VERSION "dbc-export 1 2026.26.6.5"

NS_ :

BS_:

BU_: APB APP APS DAS DPB EPAS3S EPASTS ESP GTW IBST IDB PARK RADC RCM RCM2 RCM3 RCU TPMS USM

BO_ 1009 RCM2_alertMatrix: 8 RCM2
 SG_ RCM2_matrixIndex M : 0|4@1+ (1,0) [0|15] "" Vector__XXX
 SG_ RCM2_a000_crashDetected m0 : 4|1@1+ (1,0) [0|1] "" Vector__XXX
 SG_ RCM2_a001_nearDeploy m0 : 5|1@1+ (1,0) [0|1] "" Vector__XXX
 SG_ RCM2_a002_airbagsUnArmed m0 : 6|1@1+ (1,0) [0|1] "" Vector__XXX
 SG_ RCM2_a003_warningIndicator m0 : 7|1@1+ (1,0) [0|1] "" Vector__XXX
 SG_ RCM2_a004_crashAlgoWakeup m0 : 8|1@1+ (1,0) [0|1] "" Vector__XXX
 SG_ RCM2_a005_abuseImmunityThrshold m0 : 9|1@1+ (1,0) [0|1] "" Vector__XXX
 SG_ RCM2_a006_supplierDiagEnabled m0 : 10|1@1+ (1,0) [0|1] "" Vector__XXX
 SG_ RCM2_a007_pedProCrashDetected m0 : 11|1@1+ (1,0) [0|1] "" Vector__XXX
 SG_ RCM2_a008_factoryMode m0 : 12|1@1+ (1,0) [0|1] "" Vector__XXX
 SG_ RCM2_a009_edrDataAreaLocked m0 : 13|1@1+ (1,0) [0|1] "" Vector__XXX
 SG_ RCM2_a010_pedProEDRDataLocked m0 : 14|1@1+ (1,0) [0|1] "" Vector__XXX
 SG_ RCM2_a011_placeholder0 m0 : 15|1@1+ (1,0) [0|1] "" Vector__XXX
 SG_ RCM2_a012_placeholder1 m0 : 16|1@1+ (1,0) [0|1] "" Vector__XXX
 SG_ RCM2_a013_placeholder2 m0 : 17|1@1+ (1,0) [0|1] "" Vector__XXX
 SG_ RCM2_a014_pedProNearDeploy m0 : 18|1@1+ (1,0) [0|1] "" Vector__XXX
 SG_ RCM2_a015_noDeployCrashCal m0 : 19|1@1+ (1,0) [0|1] "" Vector__XXX
 SG_ RCM2_a016_noDeployPedProCal m0 : 20|1@1+ (1,0) [0|1] "" Vector__XXX
 SG_ RCM2_a017_ecuLogAvailable m0 : 21|1@1+ (1,0) [0|1] "" Vector__XXX
 SG_ RCM2_a047_batteryESRhigh m0 : 22|1@1+ (1,0) [0|1] "" Vector__XXX
 SG_ RCM2_a048_batteryVoltageTooHigh m0 : 23|1@1+ (1,0) [0|1] "" Vector__XXX
 SG_ RCM2_a049_batteryVoltageTooLow m0 : 24|1@1+ (1,0) [0|1] "" Vector__XXX
 SG_ RCM2_a050_driverABStg1Sht2Gnd m0 : 25|1@1+ (1,0) [0|1] "" Vector__XXX
 SG_ RCM2_a051_driverABStg1Sht2Bat m0 : 26|1@1+ (1,0) [0|1] "" Vector__XXX
 SG_ RCM2_a052_driverABStg1Open m0 : 27|1@1+ (1,0) [0|1] "" Vector__XXX
 SG_ RCM2_a053_driverABStg1Short m0 : 28|1@1+ (1,0) [0|1] "" Vector__XXX
 SG_ RCM2_a054_driverABStg1CrssCoup m0 : 29|1@1+ (1,0) [0|1] "" Vector__XXX
 SG_ RCM2_a055_driverABStg1Config m0 : 30|1@1+ (1,0) [0|1] "" Vector__XXX
 SG_ RCM2_a056_driverABStg2Sht2Gnd m0 : 31|1@1+ (1,0) [0|1] "" Vector__XXX
 SG_ RCM2_a057_driverABStg2Sht2Bat m0 : 32|1@1+ (1,0) [0|1] "" Vector__XXX
 SG_ RCM2_a058_driverABStg2Open m0 : 33|1@1+ (1,0) [0|1] "" Vector__XXX
 SG_ RCM2_a059_driverABStg2Short m0 : 34|1@1+ (1,0) [0|1] "" Vector__XXX
 SG_ RCM2_a060_driverABStg2CrssCoup m0 : 35|1@1+ (1,0) [0|1] "" Vector__XXX
 SG_ RCM2_a061_driverABStg2Config m0 : 36|1@1+ (1,0) [0|1] "" Vector__XXX
 SG_ RCM2_a062_passABStg1Sht2Gnd m0 : 37|1@1+ (1,0) [0|1] "" Vector__XXX
 SG_ RCM2_a063_passABStg1Sht2Bat m0 : 38|1@1+ (1,0) [0|1] "" Vector__XXX
 SG_ RCM2_a064_passABStg1Open m0 : 39|1@1+ (1,0) [0|1] "" Vector__XXX
 SG_ RCM2_a065_passABStg1Short m0 : 40|1@1+ (1,0) [0|1] "" Vector__XXX
 SG_ RCM2_a066_passABStg1CrssCoup m0 : 41|1@1+ (1,0) [0|1] "" Vector__XXX
 SG_ RCM2_a067_passABStg1Config m0 : 42|1@1+ (1,0) [0|1] "" Vector__XXX
 SG_ RCM2_a068_passABStg2Sht2Gnd m0 : 43|1@1+ (1,0) [0|1] "" Vector__XXX
 SG_ RCM2_a069_passABStg2Sht2Bat m0 : 44|1@1+ (1,0) [0|1] "" Vector__XXX
 SG_ RCM2_a070_passABStg2Open m0 : 45|1@1+ (1,0) [0|1] "" Vector__XXX
 SG_ RCM2_a071_passABStg2Short m0 : 46|1@1+ (1,0) [0|1] "" Vector__XXX
 SG_ RCM2_a072_passABStg2CrssCoup m0 : 47|1@1+ (1,0) [0|1] "" Vector__XXX
 SG_ RCM2_a073_passABStg2Config m0 : 48|1@1+ (1,0) [0|1] "" Vector__XXX
 SG_ RCM2_a074_passActiveVentSht2Gnd m0 : 49|1@1+ (1,0) [0|1] "" Vector__XXX
 SG_ RCM2_a075_passActiveVentSht2Bat m0 : 50|1@1+ (1,0) [0|1] "" Vector__XXX
 SG_ RCM2_a076_passActiveVentOpen m0 : 51|1@1+ (1,0) [0|1] "" Vector__XXX
 SG_ RCM2_a077_passActiveVentShort m0 : 52|1@1+ (1,0) [0|1] "" Vector__XXX
 SG_ RCM2_a078_passActiveVentCrssCoup m0 : 53|1@1+ (1,0) [0|1] "" Vector__XXX
 SG_ RCM2_a079_passActiveVentConfig m0 : 54|1@1+ (1,0) [0|1] "" Vector__XXX
 SG_ RCM2_a080_pretenShldLeftSht2Gnd m0 : 55|1@1+ (1,0) [0|1] "" Vector__XXX
 SG_ RCM2_a081_pretenShldLeftSht2Bat m0 : 56|1@1+ (1,0) [0|1] "" Vector__XXX
 SG_ RCM2_a082_pretenShldLeftOpen m0 : 57|1@1+ (1,0) [0|1] "" Vector__XXX
 SG_ RCM2_a083_pretenShldLeftShort m0 : 58|1@1+ (1,0) [0|1] "" Vector__XXX
 SG_ RCM2_a084_pretenShldLeftCrossC m0 : 59|1@1+ (1,0) [0|1] "" Vector__XXX
 SG_ RCM2_a085_pretenShldLeftConfig m0 : 60|1@1+ (1,0) [0|1] "" Vector__XXX
 SG_ RCM2_a086_pretenShldRightSht2Gnd m0 : 61|1@1+ (1,0) [0|1] "" Vector__XXX
 SG_ RCM2_a087_pretenShldRightSht2Bat m0 : 62|1@1+ (1,0) [0|1] "" Vector__XXX
 SG_ RCM2_a088_pretenShldRightOpen m0 : 63|1@1+ (1,0) [0|1] "" Vector__XXX
 SG_ RCM2_a089_pretenShldRightShort m1 : 4|1@1+ (1,0) [0|1] "" Vector__XXX
 SG_ RCM2_a090_pretenShldRightCrssCou m1 : 5|1@1+ (1,0) [0|1] "" Vector__XXX
 SG_ RCM2_a091_pretenShldRightConfig m1 : 6|1@1+ (1,0) [0|1] "" Vector__XXX
 SG_ RCM2_a092_pretenLapLeftSht2Gnd m1 : 7|1@1+ (1,0) [0|1] "" Vector__XXX
 SG_ RCM2_a093_pretenLapLeftSht2Bat m1 : 8|1@1+ (1,0) [0|1] "" Vector__XXX
 SG_ RCM2_a094_pretenLapLeftOpen m1 : 9|1@1+ (1,0) [0|1] "" Vector__XXX
 SG_ RCM2_a095_pretenLapLeftShort m1 : 10|1@1+ (1,0) [0|1] "" Vector__XXX
 SG_ RCM2_a096_pretenLapLeftCrssCoup m1 : 11|1@1+ (1,0) [0|1] "" Vector__XXX
 SG_ RCM2_a097_pretenLapLeftConfig m1 : 12|1@1+ (1,0) [0|1] "" Vector__XXX
 SG_ RCM2_a098_pretenLapRightSht2Gnd m1 : 13|1@1+ (1,0) [0|1] "" Vector__XXX
 SG_ RCM2_a099_pretenLapRightSht2Bat m1 : 14|1@1+ (1,0) [0|1] "" Vector__XXX
 SG_ RCM2_a100_pretenLapRightOpen m1 : 15|1@1+ (1,0) [0|1] "" Vector__XXX
 SG_ RCM2_a101_pretenLapRightShort m1 : 16|1@1+ (1,0) [0|1] "" Vector__XXX
 SG_ RCM2_a102_pretenLapRightCrssCoup m1 : 17|1@1+ (1,0) [0|1] "" Vector__XXX
 SG_ RCM2_a103_pretenLapRightConfig m1 : 18|1@1+ (1,0) [0|1] "" Vector__XXX
 SG_ RCM2_a104_loadLimLeftSht2Gnd m1 : 19|1@1+ (1,0) [0|1] "" Vector__XXX
 SG_ RCM2_a105_loadLimLeftSht2Bat m1 : 20|1@1+ (1,0) [0|1] "" Vector__XXX
 SG_ RCM2_a106_loadLimLeftOpen m1 : 21|1@1+ (1,0) [0|1] "" Vector__XXX
 SG_ RCM2_a107_loadLimLeftShort m1 : 22|1@1+ (1,0) [0|1] "" Vector__XXX
 SG_ RCM2_a108_loadLimLeftCrssCoup m1 : 23|1@1+ (1,0) [0|1] "" Vector__XXX
 SG_ RCM2_a109_loadLimLeftConfig m1 : 24|1@1+ (1,0) [0|1] "" Vector__XXX
 SG_ RCM2_a110_loadLimRightSht2Gnd m1 : 25|1@1+ (1,0) [0|1] "" Vector__XXX
 SG_ RCM2_a111_loadLimRightSht2Bat m1 : 26|1@1+ (1,0) [0|1] "" Vector__XXX
 SG_ RCM2_a112_loadLimRightOpen m1 : 27|1@1+ (1,0) [0|1] "" Vector__XXX
 SG_ RCM2_a113_loadLimRightShort m1 : 28|1@1+ (1,0) [0|1] "" Vector__XXX
 SG_ RCM2_a114_loadLimRightCrssCoup m1 : 29|1@1+ (1,0) [0|1] "" Vector__XXX
 SG_ RCM2_a115_loadLimRightConfig m1 : 30|1@1+ (1,0) [0|1] "" Vector__XXX
 SG_ RCM2_a116_kneeABDrvrSht2Gnd m1 : 31|1@1+ (1,0) [0|1] "" Vector__XXX
 SG_ RCM2_a117_kneeABDrvrSht2Bat m1 : 32|1@1+ (1,0) [0|1] "" Vector__XXX
 SG_ RCM2_a118_kneeABDrvrOpen m1 : 33|1@1+ (1,0) [0|1] "" Vector__XXX
 SG_ RCM2_a119_kneeABDrvrShort m1 : 34|1@1+ (1,0) [0|1] "" Vector__XXX
 SG_ RCM2_a120_kneeABDrvrCrssCoup m1 : 35|1@1+ (1,0) [0|1] "" Vector__XXX
 SG_ RCM2_a121_kneeABDrvrConfig m1 : 36|1@1+ (1,0) [0|1] "" Vector__XXX
 SG_ RCM2_a122_kneeABPassSht2Gnd m1 : 37|1@1+ (1,0) [0|1] "" Vector__XXX
 SG_ RCM2_a123_kneeABPassSht2Bat m1 : 38|1@1+ (1,0) [0|1] "" Vector__XXX
 SG_ RCM2_a124_kneeABPassOpen m1 : 39|1@1+ (1,0) [0|1] "" Vector__XXX
 SG_ RCM2_a125_kneeABPassShort m1 : 40|1@1+ (1,0) [0|1] "" Vector__XXX
 SG_ RCM2_a126_kneeABPassCrssCoup m1 : 41|1@1+ (1,0) [0|1] "" Vector__XXX
 SG_ RCM2_a127_kneeABPassConfig m1 : 42|1@1+ (1,0) [0|1] "" Vector__XXX
 SG_ RCM2_a128_sideAB1stRowLSht2Gnd m1 : 43|1@1+ (1,0) [0|1] "" Vector__XXX
 SG_ RCM2_a129_sideAB1stRowLSht2Bat m1 : 44|1@1+ (1,0) [0|1] "" Vector__XXX
 SG_ RCM2_a130_sideAB1stRowLOpen m1 : 45|1@1+ (1,0) [0|1] "" Vector__XXX
 SG_ RCM2_a131_sideAB1stRowLShort m1 : 46|1@1+ (1,0) [0|1] "" Vector__XXX
 SG_ RCM2_a132_sideAB1stRowLCrssCoup m1 : 47|1@1+ (1,0) [0|1] "" Vector__XXX
 SG_ RCM2_a133_sideAB1stRowLConfig m1 : 48|1@1+ (1,0) [0|1] "" Vector__XXX
 SG_ RCM2_a134_sideAB1stRowRSht2Gnd m1 : 49|1@1+ (1,0) [0|1] "" Vector__XXX
 SG_ RCM2_a135_sideAB1stRowRSht2Bat m1 : 50|1@1+ (1,0) [0|1] "" Vector__XXX
 SG_ RCM2_a136_sideAB1stRowROpen m1 : 51|1@1+ (1,0) [0|1] "" Vector__XXX
 SG_ RCM2_a137_sideAB1stRowRShort m1 : 52|1@1+ (1,0) [0|1] "" Vector__XXX
 SG_ RCM2_a138_sideAB1stRowRCrssCoup m1 : 53|1@1+ (1,0) [0|1] "" Vector__XXX
 SG_ RCM2_a139_sideAB1stRowRConfig m1 : 54|1@1+ (1,0) [0|1] "" Vector__XXX
 SG_ RCM2_a140_hvdPyroSht2Gnd m1 : 55|1@1+ (1,0) [0|1] "" Vector__XXX
 SG_ RCM2_a141_hvdPyroSht2Bat m1 : 56|1@1+ (1,0) [0|1] "" Vector__XXX
 SG_ RCM2_a142_hvdPyroOpen m1 : 57|1@1+ (1,0) [0|1] "" Vector__XXX
 SG_ RCM2_a143_hvdPyroShort m1 : 58|1@1+ (1,0) [0|1] "" Vector__XXX
 SG_ RCM2_a144_hvdPyroCrssCoup m1 : 59|1@1+ (1,0) [0|1] "" Vector__XXX
 SG_ RCM2_a145_hvdPyroConfig m1 : 60|1@1+ (1,0) [0|1] "" Vector__XXX
 SG_ RCM2_a146_curABLeftSht2Gnd m1 : 61|1@1+ (1,0) [0|1] "" Vector__XXX
 SG_ RCM2_a147_curABLeftSht2Bat m1 : 62|1@1+ (1,0) [0|1] "" Vector__XXX
 SG_ RCM2_a148_curABLeftOpen m1 : 63|1@1+ (1,0) [0|1] "" Vector__XXX
 SG_ RCM2_a149_curABLeftShort m2 : 4|1@1+ (1,0) [0|1] "" Vector__XXX
 SG_ RCM2_a150_curABLeftCrssCoup m2 : 5|1@1+ (1,0) [0|1] "" Vector__XXX
 SG_ RCM2_a151_curABLeftConfig m2 : 6|1@1+ (1,0) [0|1] "" Vector__XXX
 SG_ RCM2_a152_curABRightSht2Gnd m2 : 7|1@1+ (1,0) [0|1] "" Vector__XXX
 SG_ RCM2_a153_curABRightSht2Bat m2 : 8|1@1+ (1,0) [0|1] "" Vector__XXX
 SG_ RCM2_a154_curABRightOpen m2 : 9|1@1+ (1,0) [0|1] "" Vector__XXX
 SG_ RCM2_a155_curABRightShort m2 : 10|1@1+ (1,0) [0|1] "" Vector__XXX
 SG_ RCM2_a156_curABRightCrssCoup m2 : 11|1@1+ (1,0) [0|1] "" Vector__XXX
 SG_ RCM2_a157_curABRightConfig m2 : 12|1@1+ (1,0) [0|1] "" Vector__XXX
 SG_ RCM2_a158_preten2ndRowLSht2Gnd m2 : 13|1@1+ (1,0) [0|1] "" Vector__XXX
 SG_ RCM2_a159_preten2ndRowLSht2Bat m2 : 14|1@1+ (1,0) [0|1] "" Vector__XXX
 SG_ RCM2_a160_preten2ndRowLOpen m2 : 15|1@1+ (1,0) [0|1] "" Vector__XXX
 SG_ RCM2_a161_preten2ndRowLShort m2 : 16|1@1+ (1,0) [0|1] "" Vector__XXX
 SG_ RCM2_a162_preten2ndRowLCrssCoup m2 : 17|1@1+ (1,0) [0|1] "" Vector__XXX
 SG_ RCM2_a163_preten2ndRowLCgf m2 : 18|1@1+ (1,0) [0|1] "" Vector__XXX
 SG_ RCM2_a164_preten2ndRowRSht2Gnd m2 : 19|1@1+ (1,0) [0|1] "" Vector__XXX
 SG_ RCM2_a165_preten2ndRowRSht2Bat m2 : 20|1@1+ (1,0) [0|1] "" Vector__XXX
 SG_ RCM2_a166_preten2ndRowROpen m2 : 21|1@1+ (1,0) [0|1] "" Vector__XXX
 SG_ RCM2_a167_preten2ndRowRShort m2 : 22|1@1+ (1,0) [0|1] "" Vector__XXX
 SG_ RCM2_a168_preten2ndRowRCrssCoup m2 : 23|1@1+ (1,0) [0|1] "" Vector__XXX
 SG_ RCM2_a169_preten2ndRowRCgf m2 : 24|1@1+ (1,0) [0|1] "" Vector__XXX
 SG_ RCM2_a170_curAB2ndRowLSht2Gnd m2 : 25|1@1+ (1,0) [0|1] "" Vector__XXX
 SG_ RCM2_a171_curAB2ndRowLSht2Bat m2 : 26|1@1+ (1,0) [0|1] "" Vector__XXX
 SG_ RCM2_a172_curAB2ndRowLOpen m2 : 27|1@1+ (1,0) [0|1] "" Vector__XXX
 SG_ RCM2_a173_curAB2ndRowLShort m2 : 28|1@1+ (1,0) [0|1] "" Vector__XXX
 SG_ RCM2_a174_curAB2ndRowLCrssCoup m2 : 29|1@1+ (1,0) [0|1] "" Vector__XXX
 SG_ RCM2_a175_curAB2ndRowLConfig m2 : 30|1@1+ (1,0) [0|1] "" Vector__XXX
 SG_ RCM2_a176_curAB2ndRowRSht2Gnd m2 : 31|1@1+ (1,0) [0|1] "" Vector__XXX
 SG_ RCM2_a177_curAB2ndRowRSht2Bat m2 : 32|1@1+ (1,0) [0|1] "" Vector__XXX
 SG_ RCM2_a178_curAB2ndRowROpen m2 : 33|1@1+ (1,0) [0|1] "" Vector__XXX
 SG_ RCM2_a179_curAB2ndRowRShort m2 : 34|1@1+ (1,0) [0|1] "" Vector__XXX
 SG_ RCM2_a180_curAB2ndRowRCrssCoup m2 : 35|1@1+ (1,0) [0|1] "" Vector__XXX
 SG_ RCM2_a181_curAB2ndRowRConfig m2 : 36|1@1+ (1,0) [0|1] "" Vector__XXX
 SG_ RCM2_a182_hoodActuatorRSht2Gnd m2 : 37|1@1+ (1,0) [0|1] "" Vector__XXX
 SG_ RCM2_a183_hoodActuatorRSht2Bat m2 : 38|1@1+ (1,0) [0|1] "" Vector__XXX
 SG_ RCM2_a184_hoodActuatorROpen m2 : 39|1@1+ (1,0) [0|1] "" Vector__XXX
 SG_ RCM2_a185_hoodActuatorRShort m2 : 40|1@1+ (1,0) [0|1] "" Vector__XXX
 SG_ RCM2_a186_hoodActuatorRCrssCoup m2 : 41|1@1+ (1,0) [0|1] "" Vector__XXX
 SG_ RCM2_a187_hoodActuatorRConfig m2 : 42|1@1+ (1,0) [0|1] "" Vector__XXX
 SG_ RCM2_a188_hoodActuatorLSht2Gnd m2 : 43|1@1+ (1,0) [0|1] "" Vector__XXX
 SG_ RCM2_a189_hoodActuatorLSht2Bat m2 : 44|1@1+ (1,0) [0|1] "" Vector__XXX
 SG_ RCM2_a190_hoodActuatorLOpen m2 : 45|1@1+ (1,0) [0|1] "" Vector__XXX
 SG_ RCM2_a191_hoodActuatorLShort m2 : 46|1@1+ (1,0) [0|1] "" Vector__XXX
 SG_ RCM2_a192_hoodActuatorLCrssCoup m2 : 47|1@1+ (1,0) [0|1] "" Vector__XXX
 SG_ RCM2_a193_hoodActuatorLConfig m2 : 48|1@1+ (1,0) [0|1] "" Vector__XXX
 SG_ RCM2_a194_driverABAVSht2Gnd m2 : 49|1@1+ (1,0) [0|1] "" Vector__XXX
 SG_ RCM2_a195_driverABAVSht2Bat m2 : 50|1@1+ (1,0) [0|1] "" Vector__XXX
 SG_ RCM2_a196_driverABAVOpen m2 : 51|1@1+ (1,0) [0|1] "" Vector__XXX
 SG_ RCM2_a197_driverABAVShort m2 : 52|1@1+ (1,0) [0|1] "" Vector__XXX
 SG_ RCM2_a198_driverABAVCrossCoup m2 : 53|1@1+ (1,0) [0|1] "" Vector__XXX
 SG_ RCM2_a199_driverABAVConfig m2 : 54|1@1+ (1,0) [0|1] "" Vector__XXX
 SG_ RCM2_a200_driverFSABSht2Gnd m2 : 55|1@1+ (1,0) [0|1] "" Vector__XXX
 SG_ RCM2_a201_driverFSABSht2Bat m2 : 56|1@1+ (1,0) [0|1] "" Vector__XXX
 SG_ RCM2_a202_driverFSABOpen m2 : 57|1@1+ (1,0) [0|1] "" Vector__XXX
 SG_ RCM2_a203_driverFSABShort m2 : 58|1@1+ (1,0) [0|1] "" Vector__XXX
 SG_ RCM2_a204_driverFSABCrossCoup m2 : 59|1@1+ (1,0) [0|1] "" Vector__XXX
 SG_ RCM2_a205_driverFSABConfig m2 : 60|1@1+ (1,0) [0|1] "" Vector__XXX
 SG_ RCM2_a206_sideAB2ndRowLSht2Gnd m2 : 61|1@1+ (1,0) [0|1] "" Vector__XXX
 SG_ RCM2_a207_sideAB2ndRowLSht2Bat m2 : 62|1@1+ (1,0) [0|1] "" Vector__XXX
 SG_ RCM2_a208_sideAB2ndRowLOpen m2 : 63|1@1+ (1,0) [0|1] "" Vector__XXX
 SG_ RCM2_a209_sideAB2ndRowLShort m3 : 4|1@1+ (1,0) [0|1] "" Vector__XXX
 SG_ RCM2_a210_sideAB2ndRowLCrssCoup m3 : 5|1@1+ (1,0) [0|1] "" Vector__XXX
 SG_ RCM2_a211_sideAB2ndRowLConfig m3 : 6|1@1+ (1,0) [0|1] "" Vector__XXX
 SG_ RCM2_a212_sideAB2ndRowRSht2Gnd m3 : 7|1@1+ (1,0) [0|1] "" Vector__XXX
 SG_ RCM2_a213_sideAB2ndRowRSht2Bat m3 : 8|1@1+ (1,0) [0|1] "" Vector__XXX
 SG_ RCM2_a214_sideAB2ndRowROpen m3 : 9|1@1+ (1,0) [0|1] "" Vector__XXX
 SG_ RCM2_a215_sideAB2ndRowRShort m3 : 10|1@1+ (1,0) [0|1] "" Vector__XXX
 SG_ RCM2_a216_sideAB2ndRowRCrssCoup m3 : 11|1@1+ (1,0) [0|1] "" Vector__XXX
 SG_ RCM2_a217_sideAB2ndRowRConfig m3 : 12|1@1+ (1,0) [0|1] "" Vector__XXX
 SG_ RCM2_a250_ens1Sht2Bat m3 : 13|1@1+ (1,0) [0|1] "" Vector__XXX
 SG_ RCM2_a251_ens1Sht2Gnd m3 : 14|1@1+ (1,0) [0|1] "" Vector__XXX
 SG_ RCM2_a252_ens1Config m3 : 15|1@1+ (1,0) [0|1] "" Vector__XXX
 SG_ RCM2_a253_ens2Sht2Bat m3 : 16|1@1+ (1,0) [0|1] "" Vector__XXX
 SG_ RCM2_a254_ens2Sht2Gnd m3 : 17|1@1+ (1,0) [0|1] "" Vector__XXX
 SG_ RCM2_a255_ens2Config m3 : 18|1@1+ (1,0) [0|1] "" Vector__XXX
 SG_ RCM2_a256_ens3Sht2Bat m3 : 19|1@1+ (1,0) [0|1] "" Vector__XXX
 SG_ RCM2_a257_ens3Sht2Gnd m3 : 20|1@1+ (1,0) [0|1] "" Vector__XXX
 SG_ RCM2_a258_ens3Config m3 : 21|1@1+ (1,0) [0|1] "" Vector__XXX
 SG_ RCM2_a259_ens4Sht2Bat m3 : 22|1@1+ (1,0) [0|1] "" Vector__XXX
 SG_ RCM2_a260_ens4Sht2Gnd m3 : 23|1@1+ (1,0) [0|1] "" Vector__XXX
 SG_ RCM2_a261_ens4Config m3 : 24|1@1+ (1,0) [0|1] "" Vector__XXX
 SG_ RCM2_a264_imuYawR8OffCompPosLife m3 : 25|1@1+ (1,0) [0|1] "" Vector__XXX
 SG_ RCM2_a265_imuYawR8OffCompNegLife m3 : 26|1@1+ (1,0) [0|1] "" Vector__XXX
 SG_ RCM2_a266_imuYawR8OffCompPosFLDC m3 : 27|1@1+ (1,0) [0|1] "" Vector__XXX
 SG_ RCM2_a267_imuYawR8OffCompNegFLDC m3 : 28|1@1+ (1,0) [0|1] "" Vector__XXX
 SG_ RCM2_a268_imuYawR8OffCompPosSLDC m3 : 29|1@1+ (1,0) [0|1] "" Vector__XXX
 SG_ RCM2_a269_imuYawR8OffCompNegSLDC m3 : 30|1@1+ (1,0) [0|1] "" Vector__XXX
 SG_ RCM2_a270_imuPtchR8OffCompPosLif m3 : 31|1@1+ (1,0) [0|1] "" Vector__XXX
 SG_ RCM2_a271_imuPtchR8OffCompNegLif m3 : 32|1@1+ (1,0) [0|1] "" Vector__XXX
 SG_ RCM2_a272_imuPtchR8OffCompPosFLD m3 : 33|1@1+ (1,0) [0|1] "" Vector__XXX
 SG_ RCM2_a273_imuPtchR8OffCompNegFLD m3 : 34|1@1+ (1,0) [0|1] "" Vector__XXX
 SG_ RCM2_a274_imuPtchR8OffCompPosSLD m3 : 35|1@1+ (1,0) [0|1] "" Vector__XXX
 SG_ RCM2_a275_imuPtchR8OffCompNegSLD m3 : 36|1@1+ (1,0) [0|1] "" Vector__XXX
 SG_ RCM2_a276_imuRollR8OffCompPosLif m3 : 37|1@1+ (1,0) [0|1] "" Vector__XXX
 SG_ RCM2_a277_imuRollR8OffCompNegLif m3 : 38|1@1+ (1,0) [0|1] "" Vector__XXX
 SG_ RCM2_a278_imuRollR8OffCompPosFLD m3 : 39|1@1+ (1,0) [0|1] "" Vector__XXX
 SG_ RCM2_a279_imuRollR8OffCompNegFLD m3 : 40|1@1+ (1,0) [0|1] "" Vector__XXX
 SG_ RCM2_a280_imuRollR8OffCompPosSLD m3 : 41|1@1+ (1,0) [0|1] "" Vector__XXX
 SG_ RCM2_a281_imuRollR8OffCompNegSLD m3 : 42|1@1+ (1,0) [0|1] "" Vector__XXX
 SG_ RCM2_a282_imuLongAOffCompPosLife m3 : 43|1@1+ (1,0) [0|1] "" Vector__XXX
 SG_ RCM2_a283_imuLongAOffCompNegLife m3 : 44|1@1+ (1,0) [0|1] "" Vector__XXX
 SG_ RCM2_a284_imuLongAOffCompPosFLDC m3 : 45|1@1+ (1,0) [0|1] "" Vector__XXX
 SG_ RCM2_a285_imuLongAOffCompNegFLDC m3 : 46|1@1+ (1,0) [0|1] "" Vector__XXX
 SG_ RCM2_a286_imuLongAOffCompPosSLDC m3 : 47|1@1+ (1,0) [0|1] "" Vector__XXX
 SG_ RCM2_a287_imuLongAOffCompNegSLDC m3 : 48|1@1+ (1,0) [0|1] "" Vector__XXX
 SG_ RCM2_a288_imuLatAcOffCompPosLife m3 : 49|1@1+ (1,0) [0|1] "" Vector__XXX
 SG_ RCM2_a289_imuLatAcOffCompNegLife m3 : 50|1@1+ (1,0) [0|1] "" Vector__XXX
 SG_ RCM2_a290_imuLatAcOffCompPosFLDC m3 : 51|1@1+ (1,0) [0|1] "" Vector__XXX
 SG_ RCM2_a291_imuLatAcOffCompNegFLDC m3 : 52|1@1+ (1,0) [0|1] "" Vector__XXX
 SG_ RCM2_a292_imuLatAcOffCompPosSLDC m3 : 53|1@1+ (1,0) [0|1] "" Vector__XXX
 SG_ RCM2_a293_imuLatAcOffCompNegSLDC m3 : 54|1@1+ (1,0) [0|1] "" Vector__XXX
 SG_ RCM2_a294_imuVertAOffCompPosLife m3 : 55|1@1+ (1,0) [0|1] "" Vector__XXX
 SG_ RCM2_a295_imuVertAOffCompNegLife m3 : 56|1@1+ (1,0) [0|1] "" Vector__XXX
 SG_ RCM2_a296_imuVertAOffCompPosFLDC m3 : 57|1@1+ (1,0) [0|1] "" Vector__XXX
 SG_ RCM2_a297_imuVertAOffCompNegFLDC m3 : 58|1@1+ (1,0) [0|1] "" Vector__XXX
 SG_ RCM2_a298_imuVertAOffCompPosSLDC m3 : 59|1@1+ (1,0) [0|1] "" Vector__XXX
 SG_ RCM2_a299_imuVertAOffCompNegSLDC m3 : 60|1@1+ (1,0) [0|1] "" Vector__XXX
 SG_ RCM2_a300_imuAccXHgMonChlPerm m3 : 61|1@1+ (1,0) [0|1] "" Vector__XXX
 SG_ RCM2_a301_imuAccXHgMonChlTemp m3 : 62|1@1+ (1,0) [0|1] "" Vector__XXX
 SG_ RCM2_a302_imuAccYHgMonChlPerm m3 : 63|1@1+ (1,0) [0|1] "" Vector__XXX
 SG_ RCM2_a303_imuAccYHgMonChlTemp m4 : 4|1@1+ (1,0) [0|1] "" Vector__XXX
 SG_ RCM2_a304_imuYawR8SnsrPermBG m4 : 5|1@1+ (1,0) [0|1] "" Vector__XXX
 SG_ RCM2_a305_imuYawR8SnsrPermInit m4 : 6|1@1+ (1,0) [0|1] "" Vector__XXX
 SG_ RCM2_a306_imuYawR8SnsrPermLF m4 : 7|1@1+ (1,0) [0|1] "" Vector__XXX
 SG_ RCM2_a307_imuYawR8ChnlMonTmpLF m4 : 8|1@1+ (1,0) [0|1] "" Vector__XXX
 SG_ RCM2_a308_imuPitchR8SnsrPermBG m4 : 9|1@1+ (1,0) [0|1] "" Vector__XXX
 SG_ RCM2_a309_imuPitchR8SnsrPermInit m4 : 10|1@1+ (1,0) [0|1] "" Vector__XXX
 SG_ RCM2_a310_imuPitchR8SnsrPermLF m4 : 11|1@1+ (1,0) [0|1] "" Vector__XXX
 SG_ RCM2_a311_imuPitchR8ChnlMonTmpLF m4 : 12|1@1+ (1,0) [0|1] "" Vector__XXX
 SG_ RCM2_a312_imuRollR8SnsrPermBG m4 : 13|1@1+ (1,0) [0|1] "" Vector__XXX
 SG_ RCM2_a313_imuRollR8SnsrPermInit m4 : 14|1@1+ (1,0) [0|1] "" Vector__XXX
 SG_ RCM2_a314_imuRollR8SnsrPermLF m4 : 15|1@1+ (1,0) [0|1] "" Vector__XXX
 SG_ RCM2_a315_imuRollR8ChnlMonTmpLF m4 : 16|1@1+ (1,0) [0|1] "" Vector__XXX
 SG_ RCM2_a316_imuAccXLgMonChlPerm m4 : 17|1@1+ (1,0) [0|1] "" Vector__XXX
 SG_ RCM2_a317_imuAccXLgMonChlTemp m4 : 18|1@1+ (1,0) [0|1] "" Vector__XXX
 SG_ RCM2_a318_imuAccYLgMonChlPerm m4 : 19|1@1+ (1,0) [0|1] "" Vector__XXX
 SG_ RCM2_a319_imuAccYLgMonChlTemp m4 : 20|1@1+ (1,0) [0|1] "" Vector__XXX
 SG_ RCM2_a320_imuAccZLgMonChlPerm m4 : 21|1@1+ (1,0) [0|1] "" Vector__XXX
 SG_ RCM2_a321_imuAccZLgMonChlTemp m4 : 22|1@1+ (1,0) [0|1] "" Vector__XXX
 SG_ RCM2_a322_imuCalibrationFailed m4 : 23|1@1+ (1,0) [0|1] "" Vector__XXX
 SG_ RCM2_a323_imuCalibrationNotDone m4 : 24|1@1+ (1,0) [0|1] "" Vector__XXX
 SG_ RCM2_a350_upFrntSnsrLSht2Gnd m4 : 25|1@1+ (1,0) [0|1] "" Vector__XXX
 SG_ RCM2_a351_upFrntSnsrLSht2Bat m4 : 26|1@1+ (1,0) [0|1] "" Vector__XXX
 SG_ RCM2_a352_upFrntSnsrLOpen m4 : 27|1@1+ (1,0) [0|1] "" Vector__XXX
 SG_ RCM2_a353_upFrntSnsrLCrssCoup m4 : 28|1@1+ (1,0) [0|1] "" Vector__XXX
 SG_ RCM2_a354_upFrntSnsrLCommErr m4 : 29|1@1+ (1,0) [0|1] "" Vector__XXX
 SG_ RCM2_a355_upFrntSnsrLInitTyp m4 : 30|1@1+ (1,0) [0|1] "" Vector__XXX
 SG_ RCM2_a356_upFrntSnsrLConfig m4 : 31|1@1+ (1,0) [0|1] "" Vector__XXX
 SG_ RCM2_a357_upFrntSnsrLDefect m4 : 32|1@1+ (1,0) [0|1] "" Vector__XXX
 SG_ RCM2_a358_upFrntSnsrLSigMon m4 : 33|1@1+ (1,0) [0|1] "" Vector__XXX
 SG_ RCM2_a360_upFrntSnsrRSht2Gnd m4 : 34|1@1+ (1,0) [0|1] "" Vector__XXX
 SG_ RCM2_a361_upFrntSnsrRSht2Bat m4 : 35|1@1+ (1,0) [0|1] "" Vector__XXX
 SG_ RCM2_a362_upFrntSnsrROpen m4 : 36|1@1+ (1,0) [0|1] "" Vector__XXX
 SG_ RCM2_a363_upFrntSnsrRCrssCoup m4 : 37|1@1+ (1,0) [0|1] "" Vector__XXX
 SG_ RCM2_a364_upFrntSnsrRCommErr m4 : 38|1@1+ (1,0) [0|1] "" Vector__XXX
 SG_ RCM2_a365_upFrntSnsrRInitTyp m4 : 39|1@1+ (1,0) [0|1] "" Vector__XXX
 SG_ RCM2_a366_upFrntSnsrRConfig m4 : 40|1@1+ (1,0) [0|1] "" Vector__XXX
 SG_ RCM2_a367_upFrntSnsrRDefect m4 : 41|1@1+ (1,0) [0|1] "" Vector__XXX
 SG_ RCM2_a368_upFrntSnsrRSigMon m4 : 42|1@1+ (1,0) [0|1] "" Vector__XXX
 SG_ RCM2_a370_upFrntSnsrMidLSht2Gnd m4 : 43|1@1+ (1,0) [0|1] "" Vector__XXX
 SG_ RCM2_a371_upFrntSnsrMidLSht2Bat m4 : 44|1@1+ (1,0) [0|1] "" Vector__XXX
 SG_ RCM2_a372_upFrntSnsrMidLOpen m4 : 45|1@1+ (1,0) [0|1] "" Vector__XXX
 SG_ RCM2_a373_upFrntSnsrMidLCrssCoup m4 : 46|1@1+ (1,0) [0|1] "" Vector__XXX
 SG_ RCM2_a374_upFrntSnsrMidLCommErr m4 : 47|1@1+ (1,0) [0|1] "" Vector__XXX
 SG_ RCM2_a375_upFrntSnsrMidLInitTyp m4 : 48|1@1+ (1,0) [0|1] "" Vector__XXX
 SG_ RCM2_a376_upFrntSnsrMidLConfig m4 : 49|1@1+ (1,0) [0|1] "" Vector__XXX
 SG_ RCM2_a377_upFrntSnsrMidLDefect m4 : 50|1@1+ (1,0) [0|1] "" Vector__XXX
 SG_ RCM2_a378_upFrntSnsrMidLSigMon m4 : 51|1@1+ (1,0) [0|1] "" Vector__XXX
 SG_ RCM2_a380_upFrntSnsrMidRSht2Gnd m4 : 52|1@1+ (1,0) [0|1] "" Vector__XXX
 SG_ RCM2_a381_upFrntSnsrMidRSht2Bat m4 : 53|1@1+ (1,0) [0|1] "" Vector__XXX
 SG_ RCM2_a382_upFrntSnsrMidROpen m4 : 54|1@1+ (1,0) [0|1] "" Vector__XXX
 SG_ RCM2_a383_upFrntSnsrMidRCrssCoup m4 : 55|1@1+ (1,0) [0|1] "" Vector__XXX
 SG_ RCM2_a384_upFrntSnsrMidRCommErr m4 : 56|1@1+ (1,0) [0|1] "" Vector__XXX
 SG_ RCM2_a385_upFrntSnsrMidRInitTyp m4 : 57|1@1+ (1,0) [0|1] "" Vector__XXX
 SG_ RCM2_a386_upFrntSnsrMidRConfig m4 : 58|1@1+ (1,0) [0|1] "" Vector__XXX
 SG_ RCM2_a387_upFrntSnsrMidRDefect m4 : 59|1@1+ (1,0) [0|1] "" Vector__XXX
 SG_ RCM2_a388_upFrntSnsrMidRSigMon m4 : 60|1@1+ (1,0) [0|1] "" Vector__XXX
 SG_ RCM2_a390_sideAccelBPilLSht2Gnd m4 : 61|1@1+ (1,0) [0|1] "" Vector__XXX
 SG_ RCM2_a391_sideAccelBPilLSht2Bat m4 : 62|1@1+ (1,0) [0|1] "" Vector__XXX
 SG_ RCM2_a392_sideAccelBPilLOpen m4 : 63|1@1+ (1,0) [0|1] "" Vector__XXX
 SG_ RCM2_a393_sideAccelBPilLCLosCoup m5 : 4|1@1+ (1,0) [0|1] "" Vector__XXX
 SG_ RCM2_a394_sideAccelBPilLCommErr m5 : 5|1@1+ (1,0) [0|1] "" Vector__XXX
 SG_ RCM2_a395_sideAccelBPilLInitTyp m5 : 6|1@1+ (1,0) [0|1] "" Vector__XXX
 SG_ RCM2_a396_sideAccelBPilLConfig m5 : 7|1@1+ (1,0) [0|1] "" Vector__XXX
 SG_ RCM2_a397_sideAccelBPilLDefect m5 : 8|1@1+ (1,0) [0|1] "" Vector__XXX
 SG_ RCM2_a398_sideAccelBPilLSigMon m5 : 9|1@1+ (1,0) [0|1] "" Vector__XXX
 SG_ RCM2_a400_sideAccelBPilRSht2Gnd m5 : 10|1@1+ (1,0) [0|1] "" Vector__XXX
 SG_ RCM2_a401_sideAccelBPilRSht2Bat m5 : 11|1@1+ (1,0) [0|1] "" Vector__XXX
 SG_ RCM2_a402_sideAccelBPilROpen m5 : 12|1@1+ (1,0) [0|1] "" Vector__XXX
 SG_ RCM2_a403_sideAccelBPilRCrssCoup m5 : 13|1@1+ (1,0) [0|1] "" Vector__XXX
 SG_ RCM2_a404_sideAccelBPilRCommErr m5 : 14|1@1+ (1,0) [0|1] "" Vector__XXX
 SG_ RCM2_a405_sideAccelBPilRInitTyp m5 : 15|1@1+ (1,0) [0|1] "" Vector__XXX
 SG_ RCM2_a406_sideAccelBPilRConfig m5 : 16|1@1+ (1,0) [0|1] "" Vector__XXX
 SG_ RCM2_a407_sideAccelBPilRDefect m5 : 17|1@1+ (1,0) [0|1] "" Vector__XXX
 SG_ RCM2_a408_sideAccelBPilRSigMon m5 : 18|1@1+ (1,0) [0|1] "" Vector__XXX
 SG_ RCM2_a410_sideAccelCPilLSht2Gnd m5 : 19|1@1+ (1,0) [0|1] "" Vector__XXX
 SG_ RCM2_a411_sideAccelCPilLSht2Bat m5 : 20|1@1+ (1,0) [0|1] "" Vector__XXX
 SG_ RCM2_a412_sideAccelCPilLOpen m5 : 21|1@1+ (1,0) [0|1] "" Vector__XXX
 SG_ RCM2_a413_sideAccelCPilLCrssCoup m5 : 22|1@1+ (1,0) [0|1] "" Vector__XXX
 SG_ RCM2_a414_sideAccelCPilLCommErr m5 : 23|1@1+ (1,0) [0|1] "" Vector__XXX
 SG_ RCM2_a415_sideAccelCPilLInitTyp m5 : 24|1@1+ (1,0) [0|1] "" Vector__XXX
 SG_ RCM2_a416_sideAccelCPilLConfig m5 : 25|1@1+ (1,0) [0|1] "" Vector__XXX
 SG_ RCM2_a417_sideAccelCPilLDefect m5 : 26|1@1+ (1,0) [0|1] "" Vector__XXX
 SG_ RCM2_a418_sideAccelCPilLSigMon m5 : 27|1@1+ (1,0) [0|1] "" Vector__XXX
 SG_ RCM2_a420_sideAccelCPilRSht2Gnd m5 : 28|1@1+ (1,0) [0|1] "" Vector__XXX
 SG_ RCM2_a421_sideAccelCPilRSht2Bat m5 : 29|1@1+ (1,0) [0|1] "" Vector__XXX
 SG_ RCM2_a422_sideAccelCPilROpen m5 : 30|1@1+ (1,0) [0|1] "" Vector__XXX
 SG_ RCM2_a423_sideAccelCPilRCrssCoup m5 : 31|1@1+ (1,0) [0|1] "" Vector__XXX
 SG_ RCM2_a424_sideAccelCPilRCommErr m5 : 32|1@1+ (1,0) [0|1] "" Vector__XXX
 SG_ RCM2_a425_sideAccelCPilRInitTyp m5 : 33|1@1+ (1,0) [0|1] "" Vector__XXX
 SG_ RCM2_a426_sideAccelCPilRConfig m5 : 34|1@1+ (1,0) [0|1] "" Vector__XXX
 SG_ RCM2_a427_sideAccelCPilRDefect m5 : 35|1@1+ (1,0) [0|1] "" Vector__XXX
 SG_ RCM2_a428_sideAccelCPilRSigMon m5 : 36|1@1+ (1,0) [0|1] "" Vector__XXX
 SG_ RCM2_a430_presFrntLDoorSht2Gnd m5 : 37|1@1+ (1,0) [0|1] "" Vector__XXX
 SG_ RCM2_a431_presFrntLDoorSht2Bat m5 : 38|1@1+ (1,0) [0|1] "" Vector__XXX
 SG_ RCM2_a432_presFrntLDoorOpen m5 : 39|1@1+ (1,0) [0|1] "" Vector__XXX
 SG_ RCM2_a433_presFrntLDoorCrssCoup m5 : 40|1@1+ (1,0) [0|1] "" Vector__XXX
 SG_ RCM2_a434_presFrntLDoorCommErr m5 : 41|1@1+ (1,0) [0|1] "" Vector__XXX
 SG_ RCM2_a435_presFrntLDoorInitTyp m5 : 42|1@1+ (1,0) [0|1] "" Vector__XXX
 SG_ RCM2_a436_presFrntLDoorConfig m5 : 43|1@1+ (1,0) [0|1] "" Vector__XXX
 SG_ RCM2_a437_presFrntLDoorDefect m5 : 44|1@1+ (1,0) [0|1] "" Vector__XXX
 SG_ RCM2_a438_presFrntLDoorSigMon m5 : 45|1@1+ (1,0) [0|1] "" Vector__XXX
 SG_ RCM2_a439_presDoorAbsolute1 m5 : 46|1@1+ (1,0) [0|1] "" Vector__XXX
 SG_ RCM2_a440_presFrntRDoorSht2Gnd m5 : 47|1@1+ (1,0) [0|1] "" Vector__XXX
 SG_ RCM2_a441_presFrntRDoorSht2Bat m5 : 48|1@1+ (1,0) [0|1] "" Vector__XXX
 SG_ RCM2_a442_presFrntRDoorOpen m5 : 49|1@1+ (1,0) [0|1] "" Vector__XXX
 SG_ RCM2_a443_presFrntRDoorCrssCoup m5 : 50|1@1+ (1,0) [0|1] "" Vector__XXX
 SG_ RCM2_a444_presFrntRDoorCommErr m5 : 51|1@1+ (1,0) [0|1] "" Vector__XXX
 SG_ RCM2_a445_presFrntRDoorInitTyp m5 : 52|1@1+ (1,0) [0|1] "" Vector__XXX
 SG_ RCM2_a446_presFrntRDoorConfig m5 : 53|1@1+ (1,0) [0|1] "" Vector__XXX
 SG_ RCM2_a447_presFrntRDoorDefect m5 : 54|1@1+ (1,0) [0|1] "" Vector__XXX
 SG_ RCM2_a448_presFrntRDoorSigMon m5 : 55|1@1+ (1,0) [0|1] "" Vector__XXX
 SG_ RCM2_a449_presDoorAbsolute2 m5 : 56|1@1+ (1,0) [0|1] "" Vector__XXX
 SG_ RCM2_a450_presPedProLSht2Gnd m5 : 57|1@1+ (1,0) [0|1] "" Vector__XXX
 SG_ RCM2_a451_presPedProLSht2Bat m5 : 58|1@1+ (1,0) [0|1] "" Vector__XXX
 SG_ RCM2_a452_presPedProLOpen m5 : 59|1@1+ (1,0) [0|1] "" Vector__XXX
 SG_ RCM2_a453_presPedProLCrssCoup m5 : 60|1@1+ (1,0) [0|1] "" Vector__XXX
 SG_ RCM2_a454_presPedProLCommErr m5 : 61|1@1+ (1,0) [0|1] "" Vector__XXX
 SG_ RCM2_a455_presPedProLInitTyp m5 : 62|1@1+ (1,0) [0|1] "" Vector__XXX
 SG_ RCM2_a456_presPedProLConfig m5 : 63|1@1+ (1,0) [0|1] "" Vector__XXX
 SG_ RCM2_a457_presPedProLDefect m6 : 4|1@1+ (1,0) [0|1] "" Vector__XXX
 SG_ RCM2_a458_presPedProLSigMon m6 : 5|1@1+ (1,0) [0|1] "" Vector__XXX
 SG_ RCM2_a460_presPedProRSht2Gnd m6 : 6|1@1+ (1,0) [0|1] "" Vector__XXX
 SG_ RCM2_a461_presPedProRSht2Bat m6 : 7|1@1+ (1,0) [0|1] "" Vector__XXX
 SG_ RCM2_a462_presPedProROpen m6 : 8|1@1+ (1,0) [0|1] "" Vector__XXX
 SG_ RCM2_a463_presPedProRCrssCoup m6 : 9|1@1+ (1,0) [0|1] "" Vector__XXX
 SG_ RCM2_a464_presPedProRCommErr m6 : 10|1@1+ (1,0) [0|1] "" Vector__XXX
 SG_ RCM2_a465_presPedProRInitTyp m6 : 11|1@1+ (1,0) [0|1] "" Vector__XXX
 SG_ RCM2_a466_presPedProRConfig m6 : 12|1@1+ (1,0) [0|1] "" Vector__XXX
 SG_ RCM2_a467_presPedProRDefect m6 : 13|1@1+ (1,0) [0|1] "" Vector__XXX
 SG_ RCM2_a468_presPedProRSigMon m6 : 14|1@1+ (1,0) [0|1] "" Vector__XXX
 SG_ RCM2_a469_presPedProAbsolute m6 : 15|1@1+ (1,0) [0|1] "" Vector__XXX
 SG_ RCM2_a470_upFrntPedProLSht2Gnd m6 : 16|1@1+ (1,0) [0|1] "" Vector__XXX
 SG_ RCM2_a471_upFrntPedProLSht2Bat m6 : 17|1@1+ (1,0) [0|1] "" Vector__XXX
 SG_ RCM2_a472_upFrntPedProLOpen m6 : 18|1@1+ (1,0) [0|1] "" Vector__XXX
 SG_ RCM2_a473_upFrntPedProLCrssCoup m6 : 19|1@1+ (1,0) [0|1] "" Vector__XXX
 SG_ RCM2_a474_upFrntPedProLCommErr m6 : 20|1@1+ (1,0) [0|1] "" Vector__XXX
 SG_ RCM2_a475_upFrntPedProLIntTyp m6 : 21|1@1+ (1,0) [0|1] "" Vector__XXX
 SG_ RCM2_a476_upFrntPedProLConfig m6 : 22|1@1+ (1,0) [0|1] "" Vector__XXX
 SG_ RCM2_a477_upFrntPedProLDefect m6 : 23|1@1+ (1,0) [0|1] "" Vector__XXX
 SG_ RCM2_a478_upFrntPedProLSigMon m6 : 24|1@1+ (1,0) [0|1] "" Vector__XXX
 SG_ RCM2_a480_upFrntPedProRSht2Gnd m6 : 25|1@1+ (1,0) [0|1] "" Vector__XXX
 SG_ RCM2_a481_upFrntPedProRSht2Bat m6 : 26|1@1+ (1,0) [0|1] "" Vector__XXX
 SG_ RCM2_a482_upFrntPedProROpen m6 : 27|1@1+ (1,0) [0|1] "" Vector__XXX
 SG_ RCM2_a483_upFrntPedProRCrssCoup m6 : 28|1@1+ (1,0) [0|1] "" Vector__XXX
 SG_ RCM2_a484_upFrntPedProRCommErr m6 : 29|1@1+ (1,0) [0|1] "" Vector__XXX
 SG_ RCM2_a485_upFrntPedProRIntTyp m6 : 30|1@1+ (1,0) [0|1] "" Vector__XXX
 SG_ RCM2_a486_upFrntPedProRConfig m6 : 31|1@1+ (1,0) [0|1] "" Vector__XXX
 SG_ RCM2_a487_upFrntPedProRDefect m6 : 32|1@1+ (1,0) [0|1] "" Vector__XXX
 SG_ RCM2_a488_upFrntPedProRSigMon m6 : 33|1@1+ (1,0) [0|1] "" Vector__XXX
 SG_ RCM2_a490_presRearLDoorSht2Gnd m6 : 34|1@1+ (1,0) [0|1] "" Vector__XXX
 SG_ RCM2_a491_presRearLDoorSht2Bat m6 : 35|1@1+ (1,0) [0|1] "" Vector__XXX
 SG_ RCM2_a492_presRearLDoorOpen m6 : 36|1@1+ (1,0) [0|1] "" Vector__XXX
 SG_ RCM2_a493_presRearLDoorCrssCoup m6 : 37|1@1+ (1,0) [0|1] "" Vector__XXX
 SG_ RCM2_a494_presRearLDoorCommErr m6 : 38|1@1+ (1,0) [0|1] "" Vector__XXX
 SG_ RCM2_a495_presRearLDoorInitTyp m6 : 39|1@1+ (1,0) [0|1] "" Vector__XXX
 SG_ RCM2_a496_presRearLDoorConfig m6 : 40|1@1+ (1,0) [0|1] "" Vector__XXX
 SG_ RCM2_a497_presRearLDoorDefect m6 : 41|1@1+ (1,0) [0|1] "" Vector__XXX
 SG_ RCM2_a498_presRearLDoorSigMon m6 : 42|1@1+ (1,0) [0|1] "" Vector__XXX
 SG_ RCM2_a500_presRearRDoorSht2Gnd m6 : 43|1@1+ (1,0) [0|1] "" Vector__XXX
 SG_ RCM2_a501_presRearRDoorSht2Bat m6 : 44|1@1+ (1,0) [0|1] "" Vector__XXX
 SG_ RCM2_a502_presRearRDoorOpen m6 : 45|1@1+ (1,0) [0|1] "" Vector__XXX
 SG_ RCM2_a503_presRearRDoorCrssCoup m6 : 46|1@1+ (1,0) [0|1] "" Vector__XXX
 SG_ RCM2_a504_presRearRDoorCommErr m6 : 47|1@1+ (1,0) [0|1] "" Vector__XXX
 SG_ RCM2_a505_presRearRDoorInitTyp m6 : 48|1@1+ (1,0) [0|1] "" Vector__XXX
 SG_ RCM2_a506_presRearRDoorConfig m6 : 49|1@1+ (1,0) [0|1] "" Vector__XXX
 SG_ RCM2_a507_presRearRDoorDefect m6 : 50|1@1+ (1,0) [0|1] "" Vector__XXX
 SG_ RCM2_a508_presRearRDoorSigMon m6 : 51|1@1+ (1,0) [0|1] "" Vector__XXX
 SG_ RCM2_a509_sideAccelDPilLSht2Gnd m6 : 52|1@1+ (1,0) [0|1] "" Vector__XXX
 SG_ RCM2_a510_sideAccelDPilLSht2Bat m6 : 53|1@1+ (1,0) [0|1] "" Vector__XXX
 SG_ RCM2_a511_sideAccelDPilLOpen m6 : 54|1@1+ (1,0) [0|1] "" Vector__XXX
 SG_ RCM2_a512_sideAccelDPilLCrssCoup m6 : 55|1@1+ (1,0) [0|1] "" Vector__XXX
 SG_ RCM2_a513_sideAccelDPilLCommErr m6 : 56|1@1+ (1,0) [0|1] "" Vector__XXX
 SG_ RCM2_a514_sideAccelDPilLInitTyp m6 : 57|1@1+ (1,0) [0|1] "" Vector__XXX
 SG_ RCM2_a515_sideAccelDPilLConfig m6 : 58|1@1+ (1,0) [0|1] "" Vector__XXX
 SG_ RCM2_a516_sideAccelDPilLDefect m6 : 59|1@1+ (1,0) [0|1] "" Vector__XXX
 SG_ RCM2_a517_sideAccelDPilLSigMon m6 : 60|1@1+ (1,0) [0|1] "" Vector__XXX
 SG_ RCM2_a518_sideAccelDPilRSht2Gnd m6 : 61|1@1+ (1,0) [0|1] "" Vector__XXX
 SG_ RCM2_a519_sideAccelDPilRSht2Bat m6 : 62|1@1+ (1,0) [0|1] "" Vector__XXX
 SG_ RCM2_a520_sideAccelDPilROpen m6 : 63|1@1+ (1,0) [0|1] "" Vector__XXX
 SG_ RCM2_a521_sideAccelDPilRCrssCoup m7 : 4|1@1+ (1,0) [0|1] "" Vector__XXX
 SG_ RCM2_a522_sideAccelDPilRCommErr m7 : 5|1@1+ (1,0) [0|1] "" Vector__XXX
 SG_ RCM2_a523_sideAccelDPilRInitTyp m7 : 6|1@1+ (1,0) [0|1] "" Vector__XXX
 SG_ RCM2_a524_sideAccelDPilRConfig m7 : 7|1@1+ (1,0) [0|1] "" Vector__XXX
 SG_ RCM2_a525_sideAccelDPilRDefect m7 : 8|1@1+ (1,0) [0|1] "" Vector__XXX
 SG_ RCM2_a526_sideAccelDPilRSigMon m7 : 9|1@1+ (1,0) [0|1] "" Vector__XXX
 SG_ RCM2_a527_upFrntSnsrCSht2Gnd m7 : 10|1@1+ (1,0) [0|1] "" Vector__XXX
 SG_ RCM2_a528_upFrntSnsrCSht2Bat m7 : 11|1@1+ (1,0) [0|1] "" Vector__XXX
 SG_ RCM2_a529_upFrntSnsrCOpen m7 : 12|1@1+ (1,0) [0|1] "" Vector__XXX
 SG_ RCM2_a530_upFrntSnsrCCrssCoup m7 : 13|1@1+ (1,0) [0|1] "" Vector__XXX
 SG_ RCM2_a531_upFrntSnsrCCommErr m7 : 14|1@1+ (1,0) [0|1] "" Vector__XXX
 SG_ RCM2_a532_upFrntSnsrCInitTyp m7 : 15|1@1+ (1,0) [0|1] "" Vector__XXX
 SG_ RCM2_a533_upFrntSnsrCConfig m7 : 16|1@1+ (1,0) [0|1] "" Vector__XXX
 SG_ RCM2_a534_upFrntSnsrCDefect m7 : 17|1@1+ (1,0) [0|1] "" Vector__XXX
 SG_ RCM2_a535_upFrntSnsrCSigMon m7 : 18|1@1+ (1,0) [0|1] "" Vector__XXX
 SG_ RCM2_a550_bucklHallLeftSht2Gnd m7 : 19|1@1+ (1,0) [0|1] "" Vector__XXX
 SG_ RCM2_a551_bucklHallLeftSht2Bat m7 : 20|1@1+ (1,0) [0|1] "" Vector__XXX
 SG_ RCM2_a552_bucklHallLeftOpen m7 : 21|1@1+ (1,0) [0|1] "" Vector__XXX
 SG_ RCM2_a553_bucklHallLeftUndef m7 : 22|1@1+ (1,0) [0|1] "" Vector__XXX
 SG_ RCM2_a554_bucklHallLeftCrssCoup m7 : 23|1@1+ (1,0) [0|1] "" Vector__XXX
 SG_ RCM2_a555_bucklHallLeftConfig m7 : 24|1@1+ (1,0) [0|1] "" Vector__XXX
 SG_ RCM2_a556_bucklHallRightSht2Gnd m7 : 25|1@1+ (1,0) [0|1] "" Vector__XXX
 SG_ RCM2_a557_bucklHallRightSht2Bat m7 : 26|1@1+ (1,0) [0|1] "" Vector__XXX
 SG_ RCM2_a558_bucklHallRightOpen m7 : 27|1@1+ (1,0) [0|1] "" Vector__XXX
 SG_ RCM2_a559_bucklHallRightUndef m7 : 28|1@1+ (1,0) [0|1] "" Vector__XXX
 SG_ RCM2_a560_bucklHallRightCrssCoup m7 : 29|1@1+ (1,0) [0|1] "" Vector__XXX
 SG_ RCM2_a561_bucklHallRightConfig m7 : 30|1@1+ (1,0) [0|1] "" Vector__XXX
 SG_ RCM2_a562_seaTrkPosLeftSht2Gnd m7 : 31|1@1+ (1,0) [0|1] "" Vector__XXX
 SG_ RCM2_a563_seaTrkPosLeftShtBat m7 : 32|1@1+ (1,0) [0|1] "" Vector__XXX
 SG_ RCM2_a564_seaTrkPosLeftOpen m7 : 33|1@1+ (1,0) [0|1] "" Vector__XXX
 SG_ RCM2_a565_seaTrkPosLeftUndefined m7 : 34|1@1+ (1,0) [0|1] "" Vector__XXX
 SG_ RCM2_a566_seaTrkPosLeftCrssCoup m7 : 35|1@1+ (1,0) [0|1] "" Vector__XXX
 SG_ RCM2_a567_seaTrkPosLeftConfig m7 : 36|1@1+ (1,0) [0|1] "" Vector__XXX
 SG_ RCM2_a568_occPROSSht2Gnd m7 : 37|1@1+ (1,0) [0|1] "" Vector__XXX
 SG_ RCM2_a569_occPROSSht2Bat m7 : 38|1@1+ (1,0) [0|1] "" Vector__XXX
 SG_ RCM2_a570_occPROSOpen m7 : 39|1@1+ (1,0) [0|1] "" Vector__XXX
 SG_ RCM2_a571_occPROSUndef m7 : 40|1@1+ (1,0) [0|1] "" Vector__XXX
 SG_ RCM2_a572_occPROSCrssCoup m7 : 41|1@1+ (1,0) [0|1] "" Vector__XXX
 SG_ RCM2_a573_occPROSConfig m7 : 42|1@1+ (1,0) [0|1] "" Vector__XXX
 SG_ RCM2_a587_sbrRearNetworkSht2Gnd m7 : 43|1@1+ (1,0) [0|1] "" Vector__XXX
 SG_ RCM2_a588_sbrRearNetworkSht2Bat m7 : 44|1@1+ (1,0) [0|1] "" Vector__XXX
 SG_ RCM2_a589_sbrRearNetworkOpen m7 : 45|1@1+ (1,0) [0|1] "" Vector__XXX
 SG_ RCM2_a590_sbrRearNetworkUndefine m7 : 46|1@1+ (1,0) [0|1] "" Vector__XXX
 SG_ RCM2_a591_sbrRearNetworkCrssCoup m7 : 47|1@1+ (1,0) [0|1] "" Vector__XXX
 SG_ RCM2_a592_sbrRearNetworkConfig m7 : 48|1@1+ (1,0) [0|1] "" Vector__XXX
 SG_ RCM2_a593_driveOrientationSht2Gn m7 : 49|1@1+ (1,0) [0|1] "" Vector__XXX
 SG_ RCM2_a594_driveOrientationSht2Ba m7 : 50|1@1+ (1,0) [0|1] "" Vector__XXX
 SG_ RCM2_a595_driveOrientationOpen m7 : 51|1@1+ (1,0) [0|1] "" Vector__XXX
 SG_ RCM2_a596_driveOrientationUndefi m7 : 52|1@1+ (1,0) [0|1] "" Vector__XXX
 SG_ RCM2_a597_driveOrientationCrssCo m7 : 53|1@1+ (1,0) [0|1] "" Vector__XXX
 SG_ RCM2_a598_driveOrientationConfig m7 : 54|1@1+ (1,0) [0|1] "" Vector__XXX
 SG_ RCM2_a600_comCANinternalTimeout m7 : 55|1@1+ (1,0) [0|1] "" Vector__XXX
 SG_ RCM2_a601_comChassisCANSilent m7 : 56|1@1+ (1,0) [0|1] "" Vector__XXX
 SG_ RCM2_a602_comChassisCANBusOff m7 : 57|1@1+ (1,0) [0|1] "" Vector__XXX
 SG_ RCM2_a603_comPARTYCANSilent m7 : 58|1@1+ (1,0) [0|1] "" Vector__XXX
 SG_ RCM2_a604_comPARTYCANBusOff m7 : 59|1@1+ (1,0) [0|1] "" Vector__XXX
 SG_ RCM2_a605_comStwAngStatMIA m7 : 60|1@1+ (1,0) [0|1] "" Vector__XXX
 SG_ RCM2_a606_comStwAngStatChkSm m7 : 61|1@1+ (1,0) [0|1] "" Vector__XXX
 SG_ RCM2_a607_comStwAngStatCntr m7 : 62|1@1+ (1,0) [0|1] "" Vector__XXX
 SG_ RCM2_a608_comDItorque1MIA m7 : 63|1@1+ (1,0) [0|1] "" Vector__XXX
 SG_ RCM2_a609_comDItorque1ChkSm m8 : 4|1@1+ (1,0) [0|1] "" Vector__XXX
 SG_ RCM2_a610_comDItorque1Cntr m8 : 5|1@1+ (1,0) [0|1] "" Vector__XXX
 SG_ RCM2_a611_comDItorque2MIA m8 : 6|1@1+ (1,0) [0|1] "" Vector__XXX
 SG_ RCM2_a612_comDItorque2ChkSm m8 : 7|1@1+ (1,0) [0|1] "" Vector__XXX
 SG_ RCM2_a613_comDItorque2Cntr m8 : 8|1@1+ (1,0) [0|1] "" Vector__XXX
 SG_ RCM2_a614_comESP135MIA m8 : 9|1@1+ (1,0) [0|1] "" Vector__XXX
 SG_ RCM2_a615_comESP135ChkSm m8 : 10|1@1+ (1,0) [0|1] "" Vector__XXX
 SG_ RCM2_a616_comESP135Cntr m8 : 11|1@1+ (1,0) [0|1] "" Vector__XXX
 SG_ RCM2_a617_comESP145MIA m8 : 12|1@1+ (1,0) [0|1] "" Vector__XXX
 SG_ RCM2_a618_comESP145ChkSm m8 : 13|1@1+ (1,0) [0|1] "" Vector__XXX
 SG_ RCM2_a619_comESP145Cntr m8 : 14|1@1+ (1,0) [0|1] "" Vector__XXX
 SG_ RCM2_a620_comInvalidVehicleSpeed m8 : 15|1@1+ (1,0) [0|1] "" Vector__XXX
 SG_ RCM2_a621_comESPBMIA m8 : 16|1@1+ (1,0) [0|1] "" Vector__XXX
 SG_ RCM2_a622_comESPBChkSm m8 : 17|1@1+ (1,0) [0|1] "" Vector__XXX
 SG_ RCM2_a623_comESPBCntr m8 : 18|1@1+ (1,0) [0|1] "" Vector__XXX
 SG_ RCM2_a624_comESPCMIA m8 : 19|1@1+ (1,0) [0|1] "" Vector__XXX
 SG_ RCM2_a625_comESPCChkSm m8 : 20|1@1+ (1,0) [0|1] "" Vector__XXX
 SG_ RCM2_a626_comESPCCntr m8 : 21|1@1+ (1,0) [0|1] "" Vector__XXX
 SG_ RCM2_a627_comEPBStatusMIA m8 : 22|1@1+ (1,0) [0|1] "" Vector__XXX
 SG_ RCM2_a628_comEPBStatusChkSm m8 : 23|1@1+ (1,0) [0|1] "" Vector__XXX
 SG_ RCM2_a629_comEPBStatusCntr m8 : 24|1@1+ (1,0) [0|1] "" Vector__XXX
 SG_ RCM2_a630_comGTWACSMIA m8 : 25|1@1+ (1,0) [0|1] "" Vector__XXX
 SG_ RCM2_a631_comGTWACSChkSm m8 : 26|1@1+ (1,0) [0|1] "" Vector__XXX
 SG_ RCM2_a632_comGTWACSCntr m8 : 27|1@1+ (1,0) [0|1] "" Vector__XXX
 SG_ RCM2_a633_comOCS1PMIA m8 : 28|1@1+ (1,0) [0|1] "" Vector__XXX
 SG_ RCM2_a634_comOCS1PChkSm m8 : 29|1@1+ (1,0) [0|1] "" Vector__XXX
 SG_ RCM2_a635_comOCS1PCntr m8 : 30|1@1+ (1,0) [0|1] "" Vector__XXX
 SG_ RCM2_a636_ocsFaulted m8 : 31|1@1+ (1,0) [0|1] "" Vector__XXX
 SG_ RCM2_a637_ocsUnknown m8 : 32|1@1+ (1,0) [0|1] "" Vector__XXX
 SG_ RCM2_a638_comGTWodoMIA m8 : 33|1@1+ (1,0) [0|1] "" Vector__XXX
 SG_ RCM2_a639_comGTWCarStateMIA m8 : 34|1@1+ (1,0) [0|1] "" Vector__XXX
 SG_ RCM2_a640_comTPMSStatusCMIA m8 : 35|1@1+ (1,0) [0|1] "" Vector__XXX
 SG_ RCM2_a641_comGTWCarConfigMIA m8 : 36|1@1+ (1,0) [0|1] "" Vector__XXX
 SG_ RCM2_a642_comVINmessageMIA m8 : 37|1@1+ (1,0) [0|1] "" Vector__XXX
 SG_ RCM2_a643_comDASSafetyFrntMIA m8 : 38|1@1+ (1,0) [0|1] "" Vector__XXX
 SG_ RCM2_a644_comDASSafetyFrntChkSm m8 : 39|1@1+ (1,0) [0|1] "" Vector__XXX
 SG_ RCM2_a645_comDASSafetyFrntCntr m8 : 40|1@1+ (1,0) [0|1] "" Vector__XXX
 SG_ RCM2_a646_comDIstateMIA m8 : 41|1@1+ (1,0) [0|1] "" Vector__XXX
 SG_ RCM2_a647_comDIstateChkSm m8 : 42|1@1+ (1,0) [0|1] "" Vector__XXX
 SG_ RCM2_a648_comDIstateCntr m8 : 43|1@1+ (1,0) [0|1] "" Vector__XXX
 SG_ RCM2_a649_comDIstate2MIA m8 : 44|1@1+ (1,0) [0|1] "" Vector__XXX
 SG_ RCM2_a650_comDIstate2ChkSm m8 : 45|1@1+ (1,0) [0|1] "" Vector__XXX
 SG_ RCM2_a651_comDIstate2Cntr m8 : 46|1@1+ (1,0) [0|1] "" Vector__XXX
 SG_ RCM2_a652_ambientTempFaulted m8 : 47|1@1+ (1,0) [0|1] "" Vector__XXX
 SG_ RCM2_a653_comGTWESP1MIA m8 : 48|1@1+ (1,0) [0|1] "" Vector__XXX
 SG_ RCM2_a654_comGTWESP1ChkSm m8 : 49|1@1+ (1,0) [0|1] "" Vector__XXX
 SG_ RCM2_a655_comGTWESP1Cntr m8 : 50|1@1+ (1,0) [0|1] "" Vector__XXX
 SG_ RCM2_a656_comVCSEATPrestMIA m8 : 51|1@1+ (1,0) [0|1] "" Vector__XXX
 SG_ RCM2_a657_comVCSEATPrestChkSm m8 : 52|1@1+ (1,0) [0|1] "" Vector__XXX
 SG_ RCM2_a658_comVCSEATPrestCntr m8 : 53|1@1+ (1,0) [0|1] "" Vector__XXX
 SG_ RCM2_a659_comVCSEATPbuckle m8 : 54|1@1+ (1,0) [0|1] "" Vector__XXX
 SG_ RCM2_a660_comVCSEATPOccpy m8 : 55|1@1+ (1,0) [0|1] "" Vector__XXX
 SG_ RCM2_a661_comVCSEATPocs m8 : 56|1@1+ (1,0) [0|1] "" Vector__XXX
 SG_ RCM2_a662_comVCSEATPstps m8 : 57|1@1+ (1,0) [0|1] "" Vector__XXX
 SG_ RCM2_a663_comVCSEATDrestMIA m8 : 58|1@1+ (1,0) [0|1] "" Vector__XXX
 SG_ RCM2_a664_comVCSEATDrestChkSm m8 : 59|1@1+ (1,0) [0|1] "" Vector__XXX
 SG_ RCM2_a665_comVCSEATDrestCntr m8 : 60|1@1+ (1,0) [0|1] "" Vector__XXX
 SG_ RCM2_a666_comVCSEATDbuckle m8 : 61|1@1+ (1,0) [0|1] "" Vector__XXX
 SG_ RCM2_a667_comVCSEATDOccpy m8 : 62|1@1+ (1,0) [0|1] "" Vector__XXX
 SG_ RCM2_a668_comVCSEATDstps m8 : 63|1@1+ (1,0) [0|1] "" Vector__XXX
 SG_ RCM2_a669_comEPBLstatusMIA m9 : 4|1@1+ (1,0) [0|1] "" Vector__XXX
 SG_ RCM2_a670_comEPBLstatusChkSm m9 : 5|1@1+ (1,0) [0|1] "" Vector__XXX
 SG_ RCM2_a671_comEPBLstatusCntr m9 : 6|1@1+ (1,0) [0|1] "" Vector__XXX
 SG_ RCM2_a672_comEPBRstatusMIA m9 : 7|1@1+ (1,0) [0|1] "" Vector__XXX
 SG_ RCM2_a673_comEPBRstatusChkSm m9 : 8|1@1+ (1,0) [0|1] "" Vector__XXX
 SG_ RCM2_a674_comEPBRstatusCntr m9 : 9|1@1+ (1,0) [0|1] "" Vector__XXX
 SG_ RCM2_a675_comUIodoMIA m9 : 10|1@1+ (1,0) [0|1] "" Vector__XXX
 SG_ RCM2_a676_comEPAS3PsysMIA m9 : 11|1@1+ (1,0) [0|1] "" Vector__XXX
 SG_ RCM2_a677_comEPAS3PsysChkSm m9 : 12|1@1+ (1,0) [0|1] "" Vector__XXX
 SG_ RCM2_a678_comEPAS3PsysCntr m9 : 13|1@1+ (1,0) [0|1] "" Vector__XXX
 SG_ RCM2_a679_comESPwheelSpeedsMIA m9 : 14|1@1+ (1,0) [0|1] "" Vector__XXX
 SG_ RCM2_a680_comESPwheelSpeedsChkSm m9 : 15|1@1+ (1,0) [0|1] "" Vector__XXX
 SG_ RCM2_a681_comESPwheelSpeedsCntr m9 : 16|1@1+ (1,0) [0|1] "" Vector__XXX
 SG_ RCM2_a682_comDIspeedMIA m9 : 17|1@1+ (1,0) [0|1] "" Vector__XXX
 SG_ RCM2_a683_comDIspeedChkSm m9 : 18|1@1+ (1,0) [0|1] "" Vector__XXX
 SG_ RCM2_a684_comDIspeedCntr m9 : 19|1@1+ (1,0) [0|1] "" Vector__XXX
 SG_ RCM2_a685_comDIchassControlMIA m9 : 20|1@1+ (1,0) [0|1] "" Vector__XXX
 SG_ RCM2_a686_comDIchassControlChkSm m9 : 21|1@1+ (1,0) [0|1] "" Vector__XXX
 SG_ RCM2_a687_comDIchassControlCntr m9 : 22|1@1+ (1,0) [0|1] "" Vector__XXX
 SG_ RCM2_a688_comVCLEFTrestMIA m9 : 23|1@1+ (1,0) [0|1] "" Vector__XXX
 SG_ RCM2_a689_comVCLEFTrestChkSm m9 : 24|1@1+ (1,0) [0|1] "" Vector__XXX
 SG_ RCM2_a690_comVCLEFTrestCntr m9 : 25|1@1+ (1,0) [0|1] "" Vector__XXX
 SG_ RCM2_a691_comVCLEFT1rLBuckle m9 : 26|1@1+ (1,0) [0|1] "" Vector__XXX
 SG_ RCM2_a692_comVCLEFT2rLBuckle m9 : 27|1@1+ (1,0) [0|1] "" Vector__XXX
 SG_ RCM2_a693_comVCLEFT1rLSTPS m9 : 28|1@1+ (1,0) [0|1] "" Vector__XXX
 SG_ RCM2_a694_comVCRIGHTrestMIA m9 : 29|1@1+ (1,0) [0|1] "" Vector__XXX
 SG_ RCM2_a695_comVCRIGHTrestChkSm m9 : 30|1@1+ (1,0) [0|1] "" Vector__XXX
 SG_ RCM2_a696_comVCRIGHTrestCntr m9 : 31|1@1+ (1,0) [0|1] "" Vector__XXX
 SG_ RCM2_a697_comVCRIGHT1rRBuckle m9 : 32|1@1+ (1,0) [0|1] "" Vector__XXX
 SG_ RCM2_a698_comVCRIGHT2rRBuckle m9 : 33|1@1+ (1,0) [0|1] "" Vector__XXX
 SG_ RCM2_a699_comVCRIGHTocs m9 : 34|1@1+ (1,0) [0|1] "" Vector__XXX
 SG_ RCM2_a700_comVCRIGHT1rRSTPS m9 : 35|1@1+ (1,0) [0|1] "" Vector__XXX
 SG_ RCM2_a701_comVCSECtpmsStatusMIA m9 : 36|1@1+ (1,0) [0|1] "" Vector__XXX
 SG_ RCM2_a750_linInternalTimeout m9 : 37|1@1+ (1,0) [0|1] "" Vector__XXX
 SG_ RCM2_a799_internalFault m9 : 38|1@1+ (1,0) [0|1] "" Vector__XXX
 SG_ RCM2_a800_crcFault m9 : 39|1@1+ (1,0) [0|1] "" Vector__XXX
 SG_ RCM2_a801_parameterLayoutID m9 : 40|1@1+ (1,0) [0|1] "" Vector__XXX
 SG_ RCM2_a802_parameterTransferID m9 : 41|1@1+ (1,0) [0|1] "" Vector__XXX
 SG_ RCM2_a803_algoVerifySensorID m9 : 42|1@1+ (1,0) [0|1] "" Vector__XXX
 SG_ RCM2_a804_configDataInconsistent m9 : 43|1@1+ (1,0) [0|1] "" Vector__XXX
 SG_ RCM2_a805_swVersionWrong m9 : 44|1@1+ (1,0) [0|1] "" Vector__XXX
 SG_ RCM2_a806_configVINnotLearned m9 : 45|1@1+ (1,0) [0|1] "" Vector__XXX
 SG_ RCM2_a807_configVINmismatch m9 : 46|1@1+ (1,0) [0|1] "" Vector__XXX
 SG_ RCM2_a808_configDriveNotLearned m9 : 47|1@1+ (1,0) [0|1] "" Vector__XXX
 SG_ RCM2_a809_configDriveMismatch m9 : 48|1@1+ (1,0) [0|1] "" Vector__XXX
 SG_ RCM2_a810_bootUpActionFailure m9 : 49|1@1+ (1,0) [0|1] "" Vector__XXX
 SG_ RCM2_a811_comAxleSpeed m9 : 50|1@1+ (1,0) [0|1] "" Vector__XXX
 SG_ RCM2_a812_idfMisuseMonitoringErr m9 : 51|1@1+ (1,0) [0|1] "" Vector__XXX
 SG_ RCM2_a813_idfEnviMonitoringError m9 : 52|1@1+ (1,0) [0|1] "" Vector__XXX
 SG_ RCM2_a814_idfEnviMonitoringEvent m9 : 53|1@1+ (1,0) [0|1] "" Vector__XXX
 SG_ RCM2_a815_upFrntPedProMLSht2Gnd m9 : 54|1@1+ (1,0) [0|1] "" Vector__XXX
 SG_ RCM2_a816_upFrntPedProMLSht2Bat m9 : 55|1@1+ (1,0) [0|1] "" Vector__XXX
 SG_ RCM2_a817_upFrntPedProMLOpen m9 : 56|1@1+ (1,0) [0|1] "" Vector__XXX
 SG_ RCM2_a818_upFrntPedProMLCrssCoup m9 : 57|1@1+ (1,0) [0|1] "" Vector__XXX
 SG_ RCM2_a819_upFrntPedProMLCommErr m9 : 58|1@1+ (1,0) [0|1] "" Vector__XXX
 SG_ RCM2_a820_upFrntPedProMLIntTyp m9 : 59|1@1+ (1,0) [0|1] "" Vector__XXX
 SG_ RCM2_a821_upFrntPedProMLConfig m9 : 60|1@1+ (1,0) [0|1] "" Vector__XXX
 SG_ RCM2_a822_upFrntPedProMLDefect m9 : 61|1@1+ (1,0) [0|1] "" Vector__XXX
 SG_ RCM2_a823_upFrntPedProMLSigMon m9 : 62|1@1+ (1,0) [0|1] "" Vector__XXX
 SG_ RCM2_a824_upFrntPedProMRSht2Gnd m9 : 63|1@1+ (1,0) [0|1] "" Vector__XXX
 SG_ RCM2_a825_upFrntPedProMRSht2Bat m10 : 4|1@1+ (1,0) [0|1] "" Vector__XXX
 SG_ RCM2_a826_upFrntPedProMROpen m10 : 5|1@1+ (1,0) [0|1] "" Vector__XXX
 SG_ RCM2_a827_upFrntPedProMRCrssCoup m10 : 6|1@1+ (1,0) [0|1] "" Vector__XXX
 SG_ RCM2_a828_upFrntPedProMRCommErr m10 : 7|1@1+ (1,0) [0|1] "" Vector__XXX
 SG_ RCM2_a829_upFrntPedProMRIntTyp m10 : 8|1@1+ (1,0) [0|1] "" Vector__XXX
 SG_ RCM2_a830_upFrntPedProMRConfig m10 : 9|1@1+ (1,0) [0|1] "" Vector__XXX
 SG_ RCM2_a831_upFrntPedProMRDefect m10 : 10|1@1+ (1,0) [0|1] "" Vector__XXX
 SG_ RCM2_a832_upFrntPedProMRSigMon m10 : 11|1@1+ (1,0) [0|1] "" Vector__XXX
 SG_ RCM2_a833_pretenShldCSht2Gnd m10 : 12|1@1+ (1,0) [0|1] "" Vector__XXX
 SG_ RCM2_a834_pretenShldCSht2Bat m10 : 13|1@1+ (1,0) [0|1] "" Vector__XXX
 SG_ RCM2_a835_pretenShldCOpen m10 : 14|1@1+ (1,0) [0|1] "" Vector__XXX
 SG_ RCM2_a836_pretenShldCShort m10 : 15|1@1+ (1,0) [0|1] "" Vector__XXX
 SG_ RCM2_a837_pretenShldCCrossC m10 : 16|1@1+ (1,0) [0|1] "" Vector__XXX
 SG_ RCM2_a838_pretenShldCConfig m10 : 17|1@1+ (1,0) [0|1] "" Vector__XXX
 SG_ RCM2_a839_preten2ndRowCSht2Gnd m10 : 18|1@1+ (1,0) [0|1] "" Vector__XXX
 SG_ RCM2_a840_preten2ndRowCSht2Bat m10 : 19|1@1+ (1,0) [0|1] "" Vector__XXX
 SG_ RCM2_a841_preten2ndRowCOpen m10 : 20|1@1+ (1,0) [0|1] "" Vector__XXX
 SG_ RCM2_a842_preten2ndRowCShort m10 : 21|1@1+ (1,0) [0|1] "" Vector__XXX
 SG_ RCM2_a843_preten2ndRowCCrssCoup m10 : 22|1@1+ (1,0) [0|1] "" Vector__XXX
 SG_ RCM2_a844_preten2ndRowCConfig m10 : 23|1@1+ (1,0) [0|1] "" Vector__XXX
 SG_ RCM2_a845_comUIchassisControlMIA m10 : 24|1@1+ (1,0) [0|1] "" Vector__XXX
 SG_ RCM2_a846_comSCCMstrAnglSnsMIA m10 : 25|1@1+ (1,0) [0|1] "" Vector__XXX
 SG_ RCM2_a847_comDASctrlMIA m10 : 26|1@1+ (1,0) [0|1] "" Vector__XXX
 SG_ RCM2_a848_comDIlocStatMIA m10 : 27|1@1+ (1,0) [0|1] "" Vector__XXX
 SG_ RCM2_a849_comIBSTparty1MIA m10 : 28|1@1+ (1,0) [0|1] "" Vector__XXX
 SG_ RCM2_a850_comVCFRONTlightingMIA m10 : 29|1@1+ (1,0) [0|1] "" Vector__XXX
 SG_ RCM2_a851_internalFaultTemp m10 : 30|1@1+ (1,0) [0|1] "" Vector__XXX
 SG_ RCM2_a852_autarkyEvent m10 : 31|1@1+ (1,0) [0|1] "" Vector__XXX
 SG_ RCM2_a853_ConfigParametersIncons m10 : 32|1@1+ (1,0) [0|1] "" Vector__XXX
 SG_ RCM2_a854_ConfigParametersNotLea m10 : 33|1@1+ (1,0) [0|1] "" Vector__XXX
 SG_ RCM2_a857_comVCLEFT2rCBuckle m10 : 34|1@1+ (1,0) [0|1] "" Vector__XXX
 SG_ RCM2_a858_comVCxLVPowerStateMIA m10 : 35|1@1+ (1,0) [0|1] "" Vector__XXX
 SG_ RCM2_a859_comVCxLVPowerStateChkS m10 : 36|1@1+ (1,0) [0|1] "" Vector__XXX
 SG_ RCM2_a860_comVCxLVPowerStateCntr m10 : 37|1@1+ (1,0) [0|1] "" Vector__XXX
 SG_ RCM2_a861_typeApprovalStringNotL m10 : 38|1@1+ (1,0) [0|1] "" Vector__XXX
 SG_ RCM2_a862_comPCSalertMatrixMIA m10 : 39|1@1+ (1,0) [0|1] "" Vector__XXX
 SG_ RCM2_a863_comVCFRONTalertMatrixM m10 : 40|1@1+ (1,0) [0|1] "" Vector__XXX
 SG_ RCM2_a864_comGTWepochTimeMIA m10 : 41|1@1+ (1,0) [0|1] "" Vector__XXX
 SG_ RCM2_a865_comVCLVBMSstatusHighMI m10 : 42|1@1+ (1,0) [0|1] "" Vector__XXX
 SG_ RCM2_a866_comDASstatusMIA m10 : 43|1@1+ (1,0) [0|1] "" Vector__XXX
 SG_ RCM2_a867_comPPBepbc1MIA m10 : 44|1@1+ (1,0) [0|1] "" Vector__XXX
 SG_ RCM2_a868_headAB3rdRowRSht2Gnd m10 : 45|1@1+ (1,0) [0|1] "" Vector__XXX
 SG_ RCM2_a869_headAB3rdRowRSht2Bat m10 : 46|1@1+ (1,0) [0|1] "" Vector__XXX
 SG_ RCM2_a870_headAB3rdRowROpen m10 : 47|1@1+ (1,0) [0|1] "" Vector__XXX
 SG_ RCM2_a871_headAB3rdRowRShort m10 : 48|1@1+ (1,0) [0|1] "" Vector__XXX
 SG_ RCM2_a872_headAB3rdRowRCrossC m10 : 49|1@1+ (1,0) [0|1] "" Vector__XXX
 SG_ RCM2_a873_headAB3rdRowRConfig m10 : 50|1@1+ (1,0) [0|1] "" Vector__XXX
 SG_ RCM2_a874_headAB3rdRowLSht2Gnd m10 : 51|1@1+ (1,0) [0|1] "" Vector__XXX
 SG_ RCM2_a875_headAB3rdRowLSht2Bat m10 : 52|1@1+ (1,0) [0|1] "" Vector__XXX
 SG_ RCM2_a876_headAB3rdRowLOpen m10 : 53|1@1+ (1,0) [0|1] "" Vector__XXX
 SG_ RCM2_a877_headAB3rdRowLShort m10 : 54|1@1+ (1,0) [0|1] "" Vector__XXX
 SG_ RCM2_a878_headAB3rdRowLCrossC m10 : 55|1@1+ (1,0) [0|1] "" Vector__XXX
 SG_ RCM2_a879_headAB3rdRowLConfig m10 : 56|1@1+ (1,0) [0|1] "" Vector__XXX
 SG_ RCM2_a880_comVCLEFT3rLBuckle m10 : 57|1@1+ (1,0) [0|1] "" Vector__XXX
 SG_ RCM2_a881_comVCRIGHT3rRBuckle m10 : 58|1@1+ (1,0) [0|1] "" Vector__XXX
 SG_ RCM2_a882_comPEBSbrakeSpeedMIA m10 : 59|1@1+ (1,0) [0|1] "" Vector__XXX
 SG_ RCM2_a883_comPEBSstatus2MIA m10 : 60|1@1+ (1,0) [0|1] "" Vector__XXX
 SG_ RCM2_a884_comPEBSstatus3MIA m10 : 61|1@1+ (1,0) [0|1] "" Vector__XXX
 SG_ RCM2_a885_comPEBSstatus2Counter m10 : 62|1@1+ (1,0) [0|1] "" Vector__XXX
 SG_ RCM2_a886_comPEBSstatus2CRC m10 : 63|1@1+ (1,0) [0|1] "" Vector__XXX

BO_ 1252 RCM3_alertLog: 8 RCM3
 SG_ RCM3_alertID : 0|1@1+ (1,0) [0|1] "" Vector__XXX
 SG_ RCM3_alertState : 15|1@1+ (1,0) [0|1] "" Vector__XXX

BO_ 1010 RCM3_alertMatrix: 8 RCM3
 SG_ RCM3_matrixIndex M : 0|4@1+ (1,0) [0|15] "" Vector__XXX
 SG_ RCM3_a001_LVPowerLossDetected m0 : 4|1@1+ (1,0) [0|1] "" Vector__XXX

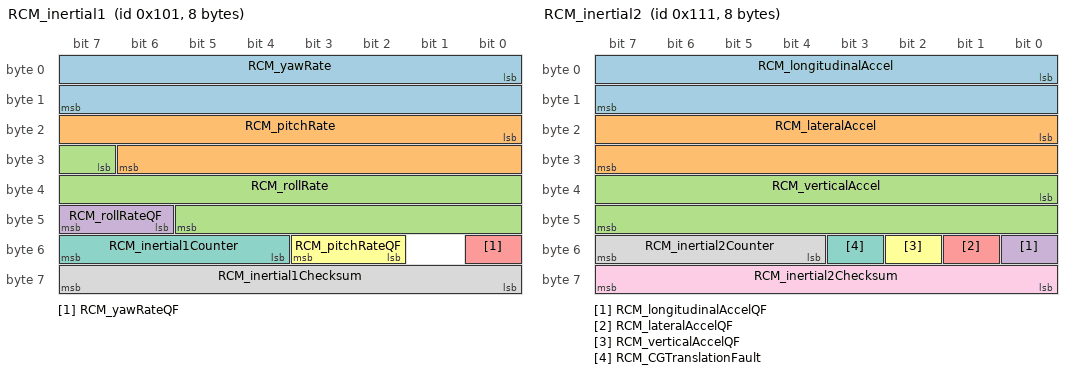
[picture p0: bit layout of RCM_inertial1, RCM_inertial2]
BO_ 257 RCM_inertial1: 8 RCM
 SG_ RCM_yawRate : 0|16@1- (0.0001,0) [-3.2766|3.2766] "rad/s" Vector__XXX
 SG_ RCM_pitchRate : 16|15@1- (0.00025,0) [-4.096|4.09575] "rad/s" Vector__XXX
 SG_ RCM_rollRate : 31|15@1- (0.00025,0) [-4.096|4.09575] "rad/s" Vector__XXX
 SG_ RCM_rollRateQF : 46|2@1+ (1,0) [0|3] "" Vector__XXX
 SG_ RCM_yawRateQF : 48|1@1+ (1,0) [0|1] "" Vector__XXX
 SG_ RCM_pitchRateQF : 50|2@1+ (1,0) [0|3] "" Vector__XXX
 SG_ RCM_inertial1Counter : 52|4@1+ (1,0) [0|15] "" Vector__XXX
 SG_ RCM_inertial1Checksum : 56|8@1+ (1,0) [0|255] "" Vector__XXX

BO_ 273 RCM_inertial2: 8 RCM
 SG_ RCM_longitudinalAccel : 0|16@1- (0.00125,0) [-40.9575|40.9575] "m/s^2" Vector__XXX
 SG_ RCM_lateralAccel : 16|16@1- (0.00125,0) [-40.9575|40.9575] "m/s^2" Vector__XXX
 SG_ RCM_verticalAccel : 32|16@1- (0.00125,0) [-40.9575|39.2] "m/s^2" Vector__XXX
 SG_ RCM_longitudinalAccelQF : 48|1@1+ (1,0) [0|1] "" Vector__XXX
 SG_ RCM_lateralAccelQF : 49|1@1+ (1,0) [0|1] "" Vector__XXX
 SG_ RCM_verticalAccelQF : 50|1@1+ (1,0) [0|1] "" Vector__XXX
 SG_ RCM_CGTranslationFault : 51|1@1+ (1,0) [0|1] "" Vector__XXX
 SG_ RCM_inertial2Counter : 52|4@1+ (1,0) [0|15] "" Vector__XXX
 SG_ RCM_inertial2Checksum : 56|8@1+ (1,0) [0|255] "" Vector__XXX

BO_ 849 RCM_info: 8 RCM
 SG_ RCM_infoIndex M : 0|8@1+ (1,0) [0|255] "" Vector__XXX
 SG_ RCM_infoBuildType m10 : 8|8@1+ (1,0) [0|255] "" Vector__XXX
 SG_ RCM_infoComponentID m10 : 48|16@1+ (1,0) [0|65535] "" Vector__XXX
 SG_ RCM_infoPcbaID m11 : 16|8@1+ (1,0) [0|255] "" Vector__XXX
 SG_ RCM_infoAssemblyID m11 : 24|8@1+ (1,0) [0|255] "" Vector__XXX
 SG_ RCM_infoUsageID m11 : 32|16@1+ (1,0) [0|65535] "" Vector__XXX
 SG_ RCM_infoApplicationCRC m13 : 32|32@1+ (1,0) [0|4294967295] "" Vector__XXX
 SG_ RCM_infoBootUdsProtoVersion m20 : 8|8@1+ (1,0) [0|255] "" Vector__XXX
 SG_ RCM_infoBootloaderCRC m20 : 32|32@1+ (1,0) [0|4294967295] "" Vector__XXX
 SG_ RCM_infoAlgoCalID m22 : 8|8@1+ (1,0) [0|255] "" Vector__XXX
 SG_ RCM_infoVariantCRC m22 : 32|32@1+ (1,0) [0|4294967295] "" Vector__XXX

BO_ 529 RCM_status: 6 RCM
 SG_ RCM_statusChecksum : 0|8@1+ (1,0) [0|255] "" Vector__XXX
 SG_ RCM_statusCounter : 8|4@1+ (1,0) [0|15] "" Vector__XXX
 SG_ RCM_armStatus : 12|2@1+ (1,0) [0|2] "" Vector__XXX
 SG_ RCM_warningIndicatorState : 14|2@1+ (1,0) [0|2] "" Vector__XXX
 SG_ RCM_passAirbagIndicatorRequest : 16|2@1+ (1,0) [0|2] "" Vector__XXX
 SG_ RCM_airbagCutoffStatus : 18|2@1+ (1,0) [0|2] "" Vector__XXX
 SG_ RCM_alrSwitchStatus : 20|2@1+ (1,0) [0|2] "" Vector__XXX
 SG_ RCM_vinLearnFlag : 22|2@1+ (1,0) [0|2] "" Vector__XXX
 SG_ RCM_seatTrackPositionDrvr : 24|2@1+ (1,0) [0|2] "" Vector__XXX
 SG_ RCM_seatTrackPositionPass : 26|2@1+ (1,0) [0|2] "" Vector__XXX
 SG_ RCM_edr1State : 28|2@1+ (1,0) [0|3] "" Vector__XXX
 SG_ RCM_edr2State : 30|2@1+ (1,0) [0|3] "" Vector__XXX
 SG_ RCM_keepPowerReason : 32|4@1+ (1,0) [0|15] "" Vector__XXX
 SG_ RCM_imuOffsetLearnState : 36|2@1+ (1,0) [0|3] "" Vector__XXX
 SG_ RCM_edr3State : 38|2@1+ (1,0) [0|3] "" Vector__XXX
 SG_ RCM_driverOrientationInitStatus : 40|3@1+ (1,0) [0|6] "" Vector__XXX
 SG_ RCM_occupantClassificationSource : 43|1@1+ (1,0) [0|1] "" Vector__XXX
 SG_ RCM_pedProEDR1State : 44|2@1+ (1,0) [0|3] "" Vector__XXX
 SG_ RCM_pedProEDR2State : 46|2@1+ (1,0) [0|3] "" Vector__XXX

BO_ 1617 RCM_udsResponse: 8 RCM
 SG_ RCM_udsResponseData : 7|64@0+ (1,0) [0|1.84467440737e+19] "" Vector__XXX

BO_ 1471 RCU_alertLog: 8 RCU
 SG_ RCU_alertID M : 0|7@1+ (1,0) [0|127] "" Vector__XXX
 SG_ RCU_alertState : 15|1@1+ (1,0) [0|1] "" Vector__XXX
 SG_ RCU_a010_sensorPowerSupply m10 : 16|1@1+ (1,0) [0|1] "" Vector__XXX
 SG_ RCU_a010_sensorHardware m10 : 17|1@1+ (1,0) [0|1] "" Vector__XXX
 SG_ RCU_a010_sensorSignal m10 : 18|1@1+ (1,0) [0|1] "" Vector__XXX
 SG_ RCU_a023_validityOnChassisBus m23 : 16|1@1+ (1,0) [0|1] "" Vector__XXX
 SG_ RCU_a023_validityOnPartyBus m23 : 17|1@1+ (1,0) [0|1] "" Vector__XXX
 SG_ RCU_a024_validityOnChassisBus m24 : 16|1@1+ (1,0) [0|1] "" Vector__XXX
 SG_ RCU_a024_validityOnPartyBus m24 : 17|1@1+ (1,0) [0|1] "" Vector__XXX
 SG_ RCU_a025_validityOnChassisBus m25 : 16|1@1+ (1,0) [0|1] "" Vector__XXX
 SG_ RCU_a025_validityOnPartyBus m25 : 17|1@1+ (1,0) [0|1] "" Vector__XXX
 SG_ RCU_a035_validityOnChassisBus m35 : 16|1@1+ (1,0) [0|1] "" Vector__XXX
 SG_ RCU_a035_validityOnPartyBus m35 : 17|1@1+ (1,0) [0|1] "" Vector__XXX
 SG_ RCU_a036_validityOnChassisBus m36 : 16|1@1+ (1,0) [0|1] "" Vector__XXX
 SG_ RCU_a036_validityOnPartyBus m36 : 17|1@1+ (1,0) [0|1] "" Vector__XXX

BO_ 998 RCU_alertMatrix: 8 RCU
 SG_ RCU_matrixIndex M : 0|4@1+ (1,0) [0|15] "" Vector__XXX
 SG_ RCU_a001_valveDriverFault m0 : 4|1@1+ (1,0) [0|1] "" Vector__XXX
 SG_ RCU_a002_solenoidValveFault m0 : 5|1@1+ (1,0) [0|1] "" Vector__XXX
 SG_ RCU_a003_pumpMotorFault m0 : 6|1@1+ (1,0) [0|1] "" Vector__XXX
 SG_ RCU_a004_supplyOvervoltage m0 : 7|1@1+ (1,0) [0|1] "" Vector__XXX
 SG_ RCU_a005_supplyUndervoltage m0 : 8|1@1+ (1,0) [0|1] "" Vector__XXX
 SG_ RCU_a006_wakeLineOpen m0 : 9|1@1+ (1,0) [0|1] "" Vector__XXX
 SG_ RCU_a007_pressureSensorFault m0 : 10|1@1+ (1,0) [0|1] "" Vector__XXX
 SG_ RCU_a008_pressureNotCalibrated m0 : 11|1@1+ (1,0) [0|1] "" Vector__XXX
 SG_ RCU_a009_brakeFluidLow m0 : 12|1@1+ (1,0) [0|1] "" Vector__XXX
 SG_ RCU_a010_pedalSensorFault m0 : 13|1@1+ (1,0) [0|1] "" Vector__XXX
 SG_ RCU_a011_idbPedalTravelMismatch m0 : 14|1@1+ (1,0) [0|1] "" Vector__XXX
 SG_ RCU_a012_pedalSensorNotCal m0 : 15|1@1+ (1,0) [0|1] "" Vector__XXX
 SG_ RCU_a013_mcuGenericFault m0 : 16|1@1+ (1,0) [0|1] "" Vector__XXX
 SG_ RCU_a014_asicTempHigh m0 : 17|1@1+ (1,0) [0|1] "" Vector__XXX
 SG_ RCU_a015_fluidLeakDetected m0 : 18|1@1+ (1,0) [0|1] "" Vector__XXX
 SG_ RCU_a016_partyBusOff m0 : 19|1@1+ (1,0) [0|1] "" Vector__XXX
 SG_ RCU_a017_chassisBusOff m0 : 20|1@1+ (1,0) [0|1] "" Vector__XXX
 SG_ RCU_a018_DItorquePathFaulted m0 : 21|1@1+ (1,0) [0|1] "" Vector__XXX
 SG_ RCU_a019_DItorquePathActive m0 : 22|1@1+ (1,0) [0|1] "" Vector__XXX
 SG_ RCU_a020_BBstatusDLC m0 : 23|1@1+ (1,0) [0|1] "" Vector__XXX
 SG_ RCU_a021_BBstatusChecksum m0 : 24|1@1+ (1,0) [0|1] "" Vector__XXX
 SG_ RCU_a022_BBstatusCounter m0 : 25|1@1+ (1,0) [0|1] "" Vector__XXX
 SG_ RCU_a023_IDBstatusDLC m0 : 26|1@1+ (1,0) [0|1] "" Vector__XXX
 SG_ RCU_a024_IDBstatusChecksum m0 : 27|1@1+ (1,0) [0|1] "" Vector__XXX
 SG_ RCU_a025_IDBstatusCounter m0 : 28|1@1+ (1,0) [0|1] "" Vector__XXX
 SG_ RCU_a026_DIchassisControlDLC m0 : 29|1@1+ (1,0) [0|1] "" Vector__XXX
 SG_ RCU_a027_DIchassisCtrlChecksum m0 : 30|1@1+ (1,0) [0|1] "" Vector__XXX
 SG_ RCU_a028_DIchassisControlCounter m0 : 31|1@1+ (1,0) [0|1] "" Vector__XXX
 SG_ RCU_a029_PMstate2DLC m0 : 32|1@1+ (1,0) [0|1] "" Vector__XXX
 SG_ RCU_a030_PMstate2Checksum m0 : 33|1@1+ (1,0) [0|1] "" Vector__XXX
 SG_ RCU_a031_PMstate2Counter m0 : 34|1@1+ (1,0) [0|1] "" Vector__XXX
 SG_ RCU_a032_VCFRONTLVPowerStateDLC m0 : 35|1@1+ (1,0) [0|1] "" Vector__XXX
 SG_ RCU_a033_VCFRONTLVPowerStateChec m0 : 36|1@1+ (1,0) [0|1] "" Vector__XXX
 SG_ RCU_a034_VCFRONTLVPowerStateCoun m0 : 37|1@1+ (1,0) [0|1] "" Vector__XXX
 SG_ RCU_a035_IDBpcpInvalid m0 : 38|1@1+ (1,0) [0|1] "" Vector__XXX
 SG_ RCU_a036_IDBpspInvalid m0 : 39|1@1+ (1,0) [0|1] "" Vector__XXX
 SG_ RCU_a037_IDBinputRodStrokeInvali m0 : 40|1@1+ (1,0) [0|1] "" Vector__XXX
 SG_ RCU_a038_DIsystemStatusDLC m0 : 41|1@1+ (1,0) [0|1] "" Vector__XXX
 SG_ RCU_a039_DIaccelPosInvalid m0 : 42|1@1+ (1,0) [0|1] "" Vector__XXX
 SG_ RCU_a040_DIgearInvalid m0 : 43|1@1+ (1,0) [0|1] "" Vector__XXX
 SG_ RCU_a041_DIsystemStatusCounter m0 : 44|1@1+ (1,0) [0|1] "" Vector__XXX
 SG_ RCU_a042_DIsystemStatusChecksum m0 : 45|1@1+ (1,0) [0|1] "" Vector__XXX
 SG_ RCU_a043_VCFRONTiBoosterLvStateI m0 : 46|1@1+ (1,0) [0|1] "" Vector__XXX
 SG_ RCU_a044_VCFRONTsensorsMIA m0 : 47|1@1+ (1,0) [0|1] "" Vector__XXX
 SG_ RCU_a045_VCFRONTtempInvalid m0 : 48|1@1+ (1,0) [0|1] "" Vector__XXX
 SG_ RCU_a046_brakeFluidLevelSNA m0 : 49|1@1+ (1,0) [0|1] "" Vector__XXX
 SG_ RCU_a047_ESPwheelSpeedsDLC m0 : 50|1@1+ (1,0) [0|1] "" Vector__XXX
 SG_ RCU_a048_ESPFrLWSSLInvalid m0 : 51|1@1+ (1,0) [0|1] "" Vector__XXX
 SG_ RCU_a049_ESPFrRWSSLInvalid m0 : 52|1@1+ (1,0) [0|1] "" Vector__XXX
 SG_ RCU_a050_ESPReLWSSLInvalid m0 : 53|1@1+ (1,0) [0|1] "" Vector__XXX
 SG_ RCU_a051_ESPReRWSSLInvalid m0 : 54|1@1+ (1,0) [0|1] "" Vector__XXX
 SG_ RCU_a052_ESPwheelSpeedsCounter m0 : 55|1@1+ (1,0) [0|1] "" Vector__XXX
 SG_ RCU_a053_ESPwheelSpeedsChecksum m0 : 56|1@1+ (1,0) [0|1] "" Vector__XXX
 SG_ RCU_a054_IDBcircuitPressFaulted m0 : 57|1@1+ (1,0) [0|1] "" Vector__XXX
 SG_ RCU_a055_IDBsimulatorPressFaulte m0 : 58|1@1+ (1,0) [0|1] "" Vector__XXX
 SG_ RCU_a056_redundantControllerIsMa m0 : 59|1@1+ (1,0) [0|1] "" Vector__XXX
 SG_ RCU_a057_DASredundantBrakingCont m0 : 60|1@1+ (1,0) [0|1] "" Vector__XXX
 SG_ RCU_a058_DASredundantBrakingCont m0 : 61|1@1+ (1,0) [0|1] "" Vector__XXX
 SG_ RCU_a059_DASredundantBrakingCont m0 : 62|1@1+ (1,0) [0|1] "" Vector__XXX
 SG_ RCU_a060_DASbrakeTorqueCommandIn m0 : 63|1@1+ (1,0) [0|1] "" Vector__XXX
 SG_ RCU_a061_DIlocStatus2DLC m1 : 4|1@1+ (1,0) [0|1] "" Vector__XXX
 SG_ RCU_a062_DIlocStatus2Counter m1 : 5|1@1+ (1,0) [0|1] "" Vector__XXX
 SG_ RCU_a063_DIlocStatus2Checksum m1 : 6|1@1+ (1,0) [0|1] "" Vector__XXX
 SG_ RCU_a064_ESPredundantBrakingStat m1 : 7|1@1+ (1,0) [0|1] "" Vector__XXX
 SG_ RCU_a065_ESPredundantBrakingStat m1 : 8|1@1+ (1,0) [0|1] "" Vector__XXX
 SG_ RCU_a066_ESPredundantBrakingStat m1 : 9|1@1+ (1,0) [0|1] "" Vector__XXX

BO_ 831 RCU_info: 8 RCU
 SG_ RCU_infoIndex M : 0|8@1+ (1,0) [0|255] "" Vector__XXX
 SG_ RCU_infoPcbaID m11 : 16|8@1+ (1,0) [0|255] "" Vector__XXX
 SG_ RCU_infoAssemblyID m11 : 24|8@1+ (1,0) [0|255] "" Vector__XXX
 SG_ RCU_infoUsageID m11 : 32|16@1+ (1,0) [0|65535] "" Vector__XXX
 SG_ RCU_infoSubUsageID m11 : 48|16@1+ (1,0) [0|65535] "" Vector__XXX

BO_ 879 TPMS_StatusC: 8 TPMS
 SG_ TPMS_c_globalHardWarning : 0|1@1+ (1,0) [0|1] "" Vector__XXX
 SG_ TPMS_c_globalSoftWarning : 1|1@1+ (1,0) [0|1] "" Vector__XXX
 SG_ TPMS_systemMalfunction : 2|1@1+ (1,0) [0|1] "" Vector__XXX
 SG_ TPMS_WA_version : 3|1@1+ (1,0) [0|1] "" Vector__XXX
 SG_ TPMS_globalDeltaPressure : 4|1@1+ (1,0) [0|1] "" Vector__XXX
 SG_ TPMS_newSensorLearnt : 5|3@1+ (1,0) [0|7] "" Vector__XXX
 SG_ TPMS_softWarningRR : 8|1@1+ (1,0) [0|1] "" Vector__XXX
 SG_ TPMS_hardWarningRR : 9|1@1+ (1,0) [0|1] "" Vector__XXX
 SG_ TPMS_softWarningRL : 10|1@1+ (1,0) [0|1] "" Vector__XXX
 SG_ TPMS_hardWarningRL : 11|1@1+ (1,0) [0|1] "" Vector__XXX
 SG_ TPMS_softWarningFR : 12|1@1+ (1,0) [0|1] "" Vector__XXX
 SG_ TPMS_hardWarningFR : 13|1@1+ (1,0) [0|1] "" Vector__XXX
 SG_ TPMS_softWarningFL : 14|1@1+ (1,0) [0|1] "" Vector__XXX
 SG_ TPMS_hardWarningFL : 15|1@1+ (1,0) [0|1] "" Vector__XXX
 SG_ TPMS_learningStatus : 16|2@1+ (1,0) [0|3] "" Vector__XXX
 SG_ TPMS_localisationStatus : 18|2@1+ (1,0) [0|3] "" Vector__XXX
 SG_ TPMS_deltaPressWarningFL : 20|1@1+ (1,0) [0|1] "" Vector__XXX
 SG_ TPMS_deltaPressWarningFR : 21|1@1+ (1,0) [0|1] "" Vector__XXX
 SG_ TPMS_deltaPressWarningRL : 22|1@1+ (1,0) [0|1] "" Vector__XXX
 SG_ TPMS_deltaPressWarningRR : 23|1@1+ (1,0) [0|1] "" Vector__XXX
 SG_ TPMS_sensorNoResponseFL : 24|1@1+ (1,0) [0|1] "" Vector__XXX
 SG_ TPMS_sensorNoResponseFR : 25|1@1+ (1,0) [0|1] "" Vector__XXX
 SG_ TPMS_sensorNoResponseRL : 26|1@1+ (1,0) [0|1] "" Vector__XXX
 SG_ TPMS_sensorNoResponseRR : 27|1@1+ (1,0) [0|1] "" Vector__XXX
 SG_ TPMS_sensorThermShutdownFL : 28|1@1+ (1,0) [0|1] "" Vector__XXX
 SG_ TPMS_sensorThermShutdownFR : 29|1@1+ (1,0) [0|1] "" Vector__XXX
 SG_ TPMS_sensorThermShutdownRL : 30|1@1+ (1,0) [0|1] "" Vector__XXX
 SG_ TPMS_sensorThermShutdownRR : 31|1@1+ (1,0) [0|1] "" Vector__XXX
 SG_ TPMS_sensorBatteryLowFL : 32|1@1+ (1,0) [0|1] "" Vector__XXX
 SG_ TPMS_sensorBatteryLowFR : 33|1@1+ (1,0) [0|1] "" Vector__XXX
 SG_ TPMS_sensorBatteryLowRL : 34|1@1+ (1,0) [0|1] "" Vector__XXX
 SG_ TPMS_sensorBatteryLowRR : 35|1@1+ (1,0) [0|1] "" Vector__XXX
 SG_ TPMS_sensorDefectiveFL : 36|1@1+ (1,0) [0|1] "" Vector__XXX
 SG_ TPMS_sensorDefectiveFR : 37|1@1+ (1,0) [0|1] "" Vector__XXX
 SG_ TPMS_sensorDefectiveRL : 38|1@1+ (1,0) [0|1] "" Vector__XXX
 SG_ TPMS_sensorDefectiveRR : 39|1@1+ (1,0) [0|1] "" Vector__XXX
 SG_ TPMS_ecuUnderVoltage : 40|1@1+ (1,0) [0|1] "" Vector__XXX
 SG_ TPMS_ecuOverVoltage : 41|1@1+ (1,0) [0|1] "" Vector__XXX
 SG_ TPMS_ecuRamRomNvMFail : 42|1@1+ (1,0) [0|1] "" Vector__XXX
 SG_ TPMS_rfReceiverFail : 43|1@1+ (1,0) [0|1] "" Vector__XXX
 SG_ TPMS_wheelPulseMissing : 44|1@1+ (1,0) [0|1] "" Vector__XXX
 SG_ TPMS_vehicleSpeedFail : 45|1@1+ (1,0) [0|1] "" Vector__XXX
 SG_ TPMS_externalTemperatureFail : 46|1@1+ (1,0) [0|1] "" Vector__XXX
 SG_ TPMS_eolNotCompleted : 47|1@1+ (1,0) [0|1] "" Vector__XXX
 SG_ TPMS_rcpFront : 48|8@1+ (0.025,0) [0|6.375] "bar" Vector__XXX
 SG_ TPMS_rcpRear : 56|8@1+ (0.025,0) [0|6.375] "bar" Vector__XXX

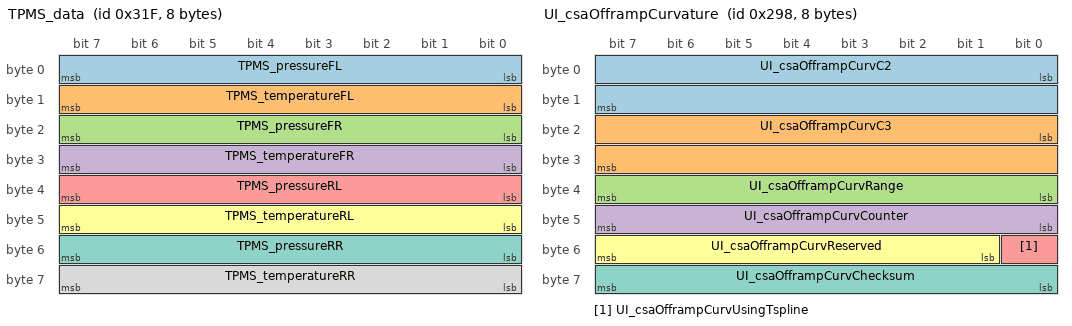
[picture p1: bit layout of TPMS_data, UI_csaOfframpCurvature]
BO_ 799 TPMS_data: 8 TPMS
 SG_ TPMS_pressureFL : 0|8@1+ (0.025,0) [0|6.35] "bar" Vector__XXX
 SG_ TPMS_temperatureFL : 8|8@1+ (1,-40) [-40|214] "degC" Vector__XXX
 SG_ TPMS_pressureFR : 16|8@1+ (0.025,0) [0|6.35] "bar" Vector__XXX
 SG_ TPMS_temperatureFR : 24|8@1+ (1,-40) [-40|214] "degC" Vector__XXX
 SG_ TPMS_pressureRL : 32|8@1+ (0.025,0) [0|6.35] "bar" Vector__XXX
 SG_ TPMS_temperatureRL : 40|8@1+ (1,-40) [-40|214] "degC" Vector__XXX
 SG_ TPMS_pressureRR : 48|8@1+ (0.025,0) [0|6.35] "bar" Vector__XXX
 SG_ TPMS_temperatureRR : 56|8@1+ (1,-40) [-40|214] "degC" Vector__XXX

BO_ 1519 TPMS_info: 8 TPMS
 SG_ TPMS_infoIndex M : 0|8@1+ (1,0) [0|255] "" Vector__XXX
 SG_ TPMS_infoComponentID m10 : 48|16@1+ (1,0) [0|65535] "" Vector__XXX
 SG_ TPMS_infoPcbaID m11 : 16|8@1+ (1,0) [0|255] "" Vector__XXX
 SG_ TPMS_infoAssemblyID m11 : 24|8@1+ (1,0) [0|255] "" Vector__XXX
 SG_ TPMS_infoUsageID m11 : 32|16@1+ (1,0) [0|65535] "" Vector__XXX
 SG_ TPMS_infoApplicationCRC m13 : 32|32@1+ (1,0) [0|4294967295] "" Vector__XXX
 SG_ TPMS_infoBootUdsProtoVersion m20 : 8|8@1+ (1,0) [0|255] "" Vector__XXX
 SG_ TPMS_infoBootloaderCRC m20 : 32|32@1+ (1,0) [0|4294967295] "" Vector__XXX

BO_ 1631 TPMS_udsResponse: 8 TPMS
 SG_ TPMS_udsResponseData : 7|64@0+ (1,0) [0|1.84467440737e+19] "" Vector__XXX

BO_ 1609 UDS_dasRequest: 8 GTW
 SG_ UDS_dasRequestData : 7|64@0+ (1,0) [0|1.84467440737e+19] "" Vector__XXX

BO_ 1584 UDS_epas3pRequest: 8 GTW
 SG_ UDS_epas3pRequestData : 7|64@0+ (1,0) [0|1.84467440737e+19] "" Vector__XXX

BO_ 1840 UDS_epas3sRequest: 8 GTW
 SG_ UDS_epas3sRequestData : 7|64@0+ (1,0) [0|1.84467440737e+19] "" Vector__XXX

BO_ 1605 UDS_espRequest: 8 GTW
 SG_ UDS_espRequestData : 7|64@0+ (1,0) [0|1.84467440737e+19] "" Vector__XXX

BO_ 2015 UDS_functionalRequest_CH: 8 GTW
 SG_ UDS_functionalRequestDataCH : 7|64@0+ (1,0) [0|1.84467440737e+19] "" Vector__XXX

BO_ 1613 UDS_ibstRequest: 8 GTW
 SG_ UDS_ibstRequestData : 7|64@0+ (1,0) [0|1.84467440737e+19] "" Vector__XXX

BO_ 1614 UDS_parkRequest: 8 GTW
 SG_ UDS_parkRequestData : 7|64@0+ (1,0) [0|1.84467440737e+19] "" Vector__XXX

BO_ 1649 UDS_radcRequest: 8 GTW
 SG_ UDS_radcRequestData : 7|64@0+ (1,0) [0|1.84467440737e+19] "" Vector__XXX

BO_ 1601 UDS_rcmRequest: 8 GTW
 SG_ UDS_rcmRequestData : 7|64@0+ (1,0) [0|1.84467440737e+19] "" Vector__XXX

BO_ 1615 UDS_tpmsRequest: 8 GTW
 SG_ UDS_tpmsRequestData : 7|64@0+ (1,0) [0|1.84467440737e+19] "" Vector__XXX

BO_ 1021 UI_autopilotControl: 8 GTW
 SG_ UI_autopilotControlIndex M : 0|3@1+ (1,0) [0|7] "" Vector__XXX
 SG_ UI_hovEnabled m0 : 3|1@1+ (1,0) [0|1] "" Vector__XXX
 SG_ UI_donDisableAutoWiperDuration m0 : 4|3@1+ (1,0) [0|7] "" Vector__XXX
 SG_ UI_donDisableOnAutoWiperSpeed m0 : 7|4@1+ (1,0) [0|15] "" Vector__XXX
 SG_ UI_blindspotMinSpeed m0 : 11|4@1+ (1,0) [0|15] "" Vector__XXX
 SG_ UI_blindspotDistance m0 : 15|3@1+ (1,0) [0|7] "" Vector__XXX
 SG_ UI_blindspotTTC m0 : 18|3@1+ (1,0) [0|7] "" Vector__XXX
 SG_ UI_donStopEndOfRampBuffer m0 : 21|3@1+ (1,0) [0|7] "" Vector__XXX
 SG_ UI_donDisableCutin m0 : 24|1@1+ (1,0) [0|1] "" Vector__XXX
 SG_ UI_smartSetSpeedOffset m0 : 25|6@1+ (1,-30) [-30|33] "%" Vector__XXX
 SG_ UI_smartSetSpeedOffsetType m0 : 31|1@1+ (1,0) [0|1] "" Vector__XXX
 SG_ UI_autopilotMonarchBackup m0 : 32|1@1+ (1,0) [0|1] "" Vector__XXX
 SG_ UI_fsdVisualizationEnabled m0 : 37|1@1+ (1,0) [0|1] "" Vector__XXX
 SG_ UI_fsdStopsControlEnabled m0 : 38|1@1+ (1,0) [0|1] "" Vector__XXX
 SG_ UI_fsdContinueOnGreenWithCIPV m0 : 39|1@1+ (1,0) [0|1] "" Vector__XXX
 SG_ UI_smartSetSpeed m0 : 40|1@1+ (1,0) [0|1] "" Vector__XXX
 SG_ UI_automaticSetSpeedOffset m0 : 41|1@1+ (1,0) [0|1] "" Vector__XXX
 SG_ UI_apply2021_1958_ISA m0 : 42|1@1+ (1,0) [0|1] "" Vector__XXX
 SG_ UI_apply2021_646_ELKS m0 : 43|1@1+ (1,0) [0|1] "" Vector__XXX
 SG_ UI_apply2021_1341_DDAW m0 : 44|1@1+ (1,0) [0|1] "" Vector__XXX
 SG_ UI_homelinkNearby m0 : 45|1@1+ (1,0) [0|1] "" Vector__XXX
 SG_ UI_enableFullSelfDriving m0 : 46|1@1+ (1,0) [0|1] "" Vector__XXX
 SG_ UI_hasFullSelfDriving m0 : 47|1@1+ (1,0) [0|1] "" Vector__XXX
 SG_ UI_autosteerActivation m0 : 48|1@1+ (1,0) [0|1] "" Vector__XXX
 SG_ UI_fsdBetaRequest m0 : 51|1@1+ (1,0) [0|1] "" Vector__XXX
 SG_ UI_fullSelfDrivingSuspended m0 : 52|1@1+ (1,0) [0|1] "" Vector__XXX
 SG_ UI_disableOptionalLaneChanges m0 : 53|1@1+ (1,0) [0|1] "" Vector__XXX
 SG_ UI_applyR152_AEBS m0 : 59|1@1+ (1,0) [0|1] "" Vector__XXX
 SG_ UI_applyDCASBehavior m0 : 60|1@1+ (1,0) [0|1] "" Vector__XXX
 SG_ UI_applyDCASBehaviorLegacy m0 : 61|1@1+ (1,0) [0|1] "" Vector__XXX
 SG_ UI_applyADDWWarnings m0 : 62|1@1+ (1,0) [0|1] "" Vector__XXX
 SG_ UI_autopilotControlMux0Valid m0 : 63|1@1+ (1,0) [0|1] "" Vector__XXX
 SG_ UI_selectableCameraRequest m1 : 8|4@1+ (1,0) [0|14] "" Vector__XXX
 SG_ UI_overrideSleepWithSuspend m1 : 16|1@1+ (1,0) [0|1] "" Vector__XXX
 SG_ UI_driverMonitorConfirmation m1 : 17|1@1+ (1,0) [0|1] "" Vector__XXX
 SG_ UI_parkAssistUseVision m1 : 18|1@1+ (1,0) [0|1] "" Vector__XXX
 SG_ UI_applyEceR79 m1 : 19|1@1+ (1,0) [0|1] "" Vector__XXX
 SG_ UI_enableMapStops m1 : 20|1@1+ (1,0) [0|1] "" Vector__XXX
 SG_ UI_disableMain m1 : 23|1@1+ (1,0) [0|1] "" Vector__XXX
 SG_ UI_disableNarrow m1 : 24|1@1+ (1,0) [0|1] "" Vector__XXX
 SG_ UI_disableFisheye m1 : 25|1@1+ (1,0) [0|1] "" Vector__XXX
 SG_ UI_disableLeftPillar m1 : 26|1@1+ (1,0) [0|1] "" Vector__XXX
 SG_ UI_disableRightPillar m1 : 27|1@1+ (1,0) [0|1] "" Vector__XXX
 SG_ UI_disableLeftRepeater m1 : 28|1@1+ (1,0) [0|1] "" Vector__XXX
 SG_ UI_disableRightRepeater m1 : 29|1@1+ (1,0) [0|1] "" Vector__XXX
 SG_ UI_disableBackup m1 : 30|1@1+ (1,0) [0|1] "" Vector__XXX
 SG_ UI_disableRadar m1 : 31|1@1+ (1,0) [0|1] "" Vector__XXX
 SG_ UI_noStalkConfirmAlertHaptic m1 : 32|1@1+ (1,0) [0|1] "" Vector__XXX
 SG_ UI_regulatoryLKA m1 : 33|1@1+ (1,0) [0|1] "" Vector__XXX
 SG_ UI_regulatoryLaneAssistLevel m1 : 34|1@1+ (1,0) [0|1] "" Vector__XXX
 SG_ UI_ulcSnooze m1 : 36|1@1+ (1,0) [0|1] "" Vector__XXX
 SG_ UI_noStalkConfirmAlertChime m1 : 37|1@1+ (1,0) [0|1] "" Vector__XXX
 SG_ UI_factorySummonEnable m1 : 39|1@1+ (1,0) [0|1] "" Vector__XXX
 SG_ UI_apmv3Branch m1 : 40|3@1+ (1,0) [0|7] "" Vector__XXX
 SG_ UI_enableCabinCamera m1 : 43|1@1+ (1,0) [0|1] "" Vector__XXX
 SG_ UI_enableAutopilotStopWarning m1 : 44|1@1+ (1,0) [0|1] "" Vector__XXX
 SG_ UI_showLaneGraph m1 : 45|1@1+ (1,0) [0|1] "" Vector__XXX
 SG_ UI_showTrackLabels m1 : 46|1@1+ (1,0) [0|1] "" Vector__XXX
 SG_ UI_hardCoreSummon m1 : 47|1@1+ (1,0) [0|1] "" Vector__XXX
 SG_ UI_enableCabinCameraTelemetry m1 : 48|1@1+ (1,0) [0|1] "" Vector__XXX
 SG_ UI_enableVisionSpeedControl m1 : 49|1@1+ (1,0) [0|1] "" Vector__XXX
 SG_ UI_autopilotTelemetryInChina m1 : 50|1@1+ (1,0) [0|1] "" Vector__XXX
 SG_ UI_enableTeslaAutopark m1 : 51|1@1+ (1,0) [0|1] "" Vector__XXX
 SG_ UI_autoTurnSignalMode m1 : 52|1@1+ (1,0) [0|1] "" Vector__XXX
 SG_ UI_enableCautionLightControl m1 : 54|1@1+ (1,0) [0|1] "" Vector__XXX
 SG_ UI_applyEceR79SmartSummonOnly m1 : 55|1@1+ (1,0) [0|1] "" Vector__XXX
 SG_ UI_autopilotMonarchEnabled m1 : 56|1@1+ (1,0) [0|1] "" Vector__XXX
 SG_ UI_autopilotEphemerisEnabled m1 : 57|1@1+ (1,0) [0|1] "" Vector__XXX
 SG_ UI_enableCabinAudioRecording m1 : 59|1@1+ (1,0) [0|1] "" Vector__XXX
 SG_ UI_autopilotControlMux1Valid m1 : 63|1@1+ (1,0) [0|1] "" Vector__XXX
 SG_ UI_enableApproachingEmergencyVeh m2 : 5|1@1+ (1,0) [0|1] "" Vector__XXX
 SG_ UI_enableStartFsdFromParkBrakeCo m2 : 6|1@1+ (1,0) [0|1] "" Vector__XXX
 SG_ UI_enableStartFsdFromPark m2 : 7|1@1+ (1,0) [0|1] "" Vector__XXX
 SG_ UI_fsdMaxSpeedOffsetPercentage m2 : 8|6@1+ (1,0) [0|63] "%" Vector__XXX
 SG_ UI_calibrationReadyInFactory m2 : 15|1@1+ (1,0) [0|1] "" Vector__XXX
 SG_ UI_coldStartMonarchInFactory m2 : 16|1@1+ (1,0) [0|1] "" Vector__XXX
 SG_ UI_navMinutesToArrival m2 : 17|10@1+ (1,0) [0|1023] "minutes" Vector__XXX
 SG_ UI_fsdQuizRequired m2 : 27|1@1+ (1,0) [0|1] "" Vector__XXX
 SG_ UI_fsdQuizPassed m2 : 28|1@1+ (1,0) [0|1] "" Vector__XXX
 SG_ UI_fsdAllowedInLocalizedRegion m2 : 29|1@1+ (1,0) [0|1] "" Vector__XXX
 SG_ UI_autopilotDrivingProfile m2 : 60|3@1+ (1,0) [0|7] "" Vector__XXX
 SG_ UI_autopilotControlMux2Valid m2 : 63|1@1+ (1,0) [0|1] "" Vector__XXX

BO_ 659 UI_chassisControl: 8 GTW
 SG_ UI_steeringTuneRequest : 0|2@1+ (1,0) [0|3] "" Vector__XXX
 SG_ UI_tractionControlMode : 2|3@1+ (1,0) [0|7] "" Vector__XXX
 SG_ UI_parkBrakeRequest : 5|2@1+ (1,0) [0|2] "" Vector__XXX
 SG_ UI_narrowGarages : 7|1@1+ (1,0) [0|1] "" Vector__XXX
 SG_ UI_winchModeRequest : 8|2@1+ (1,0) [0|3] "" Vector__XXX
 SG_ UI_zeroSpeedConfirmed : 10|2@1+ (1,0) [0|2] "" Vector__XXX
 SG_ UI_trailerMode : 12|1@1+ (1,0) [0|1] "" Vector__XXX
 SG_ UI_distanceUnits : 13|1@1+ (1,0) [0|1] "" Vector__XXX
 SG_ UI_dasDebugEnable : 14|1@1+ (1,0) [0|1] "" Vector__XXX
 SG_ UI_accOvertakeEnable : 16|2@1+ (1,0) [0|2] "" Vector__XXX
 SG_ UI_aebEnable : 18|2@1+ (1,0) [0|2] "" Vector__XXX
 SG_ UI_aesEnable : 20|2@1+ (1,0) [0|2] "" Vector__XXX
 SG_ UI_ahlbEnable : 22|2@1+ (1,0) [0|2] "" Vector__XXX
 SG_ UI_autoLaneChangeEnable : 24|2@1+ (1,0) [0|2] "" Vector__XXX
 SG_ UI_winchProxUserOverride : 26|1@1+ (1,0) [0|1] "" Vector__XXX
 SG_ UI_rebootAutopilot : 27|1@1+ (1,0) [0|1] "" Vector__XXX
 SG_ UI_autoParkRequest : 28|4@1+ (1,0) [0|14] "" Vector__XXX
 SG_ UI_bsdEnable : 32|2@1+ (1,0) [0|2] "" Vector__XXX
 SG_ UI_fcwEnable : 34|2@1+ (1,0) [0|2] "" Vector__XXX
 SG_ UI_fcwSensitivity : 36|2@1+ (1,0) [0|2] "" Vector__XXX
 SG_ UI_latControlEnable : 38|2@1+ (1,0) [0|2] "" Vector__XXX
 SG_ UI_ldwEnable : 40|2@1+ (1,0) [0|2] "" Vector__XXX
 SG_ UI_pedalSafetyEnable : 42|2@1+ (1,0) [0|2] "" Vector__XXX
 SG_ UI_pedalMap_epas : 44|2@1+ (1,0) [0|3] "" Vector__XXX
 SG_ UI_redLightStopSignEnable : 46|2@1+ (1,0) [0|2] "" Vector__XXX
 SG_ UI_selfParkTune : 48|4@1+ (1,0) [0|14] "" Vector__XXX
 SG_ UI_chassisControlCounter : 52|4@1+ (1,0) [0|15] "" Vector__XXX
 SG_ UI_chassisControlChecksum : 56|8@1+ (1,0) [0|255] "" Vector__XXX

BO_ 664 UI_csaOfframpCurvature: 8 GTW
 SG_ UI_csaOfframpCurvC2 : 0|16@1- (1.0e-06,0) [-0.032768|0.032767] "1/m" Vector__XXX
 SG_ UI_csaOfframpCurvC3 : 16|16@1- (4.0e-09,0) [-0.000131072|0.000131068] "1/m2" Vector__XXX
 SG_ UI_csaOfframpCurvRange : 32|8@1+ (2,0) [0|510] "m" Vector__XXX
 SG_ UI_csaOfframpCurvCounter : 40|8@1+ (1,0) [0|255] "" Vector__XXX
 SG_ UI_csaOfframpCurvUsingTspline : 48|1@1+ (1,0) [0|1] "" Vector__XXX
 SG_ UI_csaOfframpCurvReserved : 49|7@1+ (1,0) [0|127] "" Vector__XXX
 SG_ UI_csaOfframpCurvChecksum : 56|8@1+ (1,0) [0|255] "" Vector__XXX

BO_TX_BU_ 1009 : RCM2;
BO_TX_BU_ 1252 : RCM3;
BO_TX_BU_ 1010 : RCM3;
BO_TX_BU_ 257 : RCM;
BO_TX_BU_ 273 : RCM;
BO_TX_BU_ 849 : RCM;
BO_TX_BU_ 529 : RCM;
BO_TX_BU_ 1617 : RCM;
BO_TX_BU_ 1471 : RCU;
BO_TX_BU_ 998 : RCU;
BO_TX_BU_ 831 : RCU;
BO_TX_BU_ 879 : TPMS;
BO_TX_BU_ 799 : TPMS;
BO_TX_BU_ 1519 : TPMS;
BO_TX_BU_ 1631 : TPMS;
BO_TX_BU_ 1609 : GTW;
BO_TX_BU_ 1584 : GTW;
BO_TX_BU_ 1840 : GTW;
BO_TX_BU_ 1605 : GTW;
BO_TX_BU_ 2015 : GTW;
BO_TX_BU_ 1613 : GTW;
BO_TX_BU_ 1614 : GTW;
BO_TX_BU_ 1649 : GTW;
BO_TX_BU_ 1601 : GTW;
BO_TX_BU_ 1615 : GTW;
BO_TX_BU_ 1021 : GTW;
BO_TX_BU_ 659 : GTW;
BO_TX_BU_ 664 : GTW;
CM_ BO_ 1009 "RCM2 ECU message: alert matrix; frame length from the layout, not yet observed on a vehicle bus";
CM_ SG_ 1009 RCM2_matrixIndex "RCM2 ECU: matrix index";
CM_ SG_ 1009 RCM2_a000_crashDetected "RCM2 ECU: a000 crash detected";
CM_ SG_ 1009 RCM2_a001_nearDeploy "RCM2 ECU: a001 near deploy";
CM_ SG_ 1009 RCM2_a002_airbagsUnArmed "RCM2 ECU: a002 airbags un armed";
CM_ SG_ 1009 RCM2_a003_warningIndicator "RCM2 ECU: a003 warning indicator";
CM_ SG_ 1009 RCM2_a004_crashAlgoWakeup "RCM2 ECU: a004 crash algo wakeup";
CM_ SG_ 1009 RCM2_a005_abuseImmunityThrshold "RCM2 ECU: a005 abuse immunity thrshold";
CM_ SG_ 1009 RCM2_a006_supplierDiagEnabled "RCM2 ECU: a006 supplier diag enabled";
CM_ SG_ 1009 RCM2_a007_pedProCrashDetected "RCM2 ECU: a007 ped pro crash detected";
CM_ SG_ 1009 RCM2_a008_factoryMode "RCM2 ECU: a008 factory mode";
CM_ SG_ 1009 RCM2_a009_edrDataAreaLocked "RCM2 ECU: a009 edr data area locked";
CM_ SG_ 1009 RCM2_a010_pedProEDRDataLocked "RCM2 ECU: a010 ped pro EDR data locked";
CM_ SG_ 1009 RCM2_a011_placeholder0 "RCM2 ECU: a011 placeholder0";
CM_ SG_ 1009 RCM2_a012_placeholder1 "RCM2 ECU: a012 placeholder1";
CM_ SG_ 1009 RCM2_a013_placeholder2 "RCM2 ECU: a013 placeholder2";
CM_ SG_ 1009 RCM2_a014_pedProNearDeploy "RCM2 ECU: a014 ped pro near deploy";
CM_ SG_ 1009 RCM2_a015_noDeployCrashCal "RCM2 ECU: a015 no deploy crash cal";
CM_ SG_ 1009 RCM2_a016_noDeployPedProCal "RCM2 ECU: a016 no deploy ped pro cal";
CM_ SG_ 1009 RCM2_a017_ecuLogAvailable "RCM2 ECU: a017 ecu log available";
CM_ SG_ 1009 RCM2_a047_batteryESRhigh "RCM2 ECU: a047 battery ES rhigh";
CM_ SG_ 1009 RCM2_a048_batteryVoltageTooHigh "RCM2 ECU: a048 battery voltage too high";
CM_ SG_ 1009 RCM2_a049_batteryVoltageTooLow "RCM2 ECU: a049 battery voltage too low";
CM_ SG_ 1009 RCM2_a050_driverABStg1Sht2Gnd "RCM2 ECU: a050 driver AB stg1 sht2 gnd";
CM_ SG_ 1009 RCM2_a051_driverABStg1Sht2Bat "RCM2 ECU: a051 driver AB stg1 sht2 bat";
CM_ SG_ 1009 RCM2_a052_driverABStg1Open "RCM2 ECU: a052 driver AB stg1 open";
CM_ SG_ 1009 RCM2_a053_driverABStg1Short "RCM2 ECU: a053 driver AB stg1 short";
CM_ SG_ 1009 RCM2_a054_driverABStg1CrssCoup "RCM2 ECU: a054 driver AB stg1 crss coup";
CM_ SG_ 1009 RCM2_a055_driverABStg1Config "RCM2 ECU: a055 driver AB stg1 config";
CM_ SG_ 1009 RCM2_a056_driverABStg2Sht2Gnd "RCM2 ECU: a056 driver AB stg2 sht2 gnd";
CM_ SG_ 1009 RCM2_a057_driverABStg2Sht2Bat "RCM2 ECU: a057 driver AB stg2 sht2 bat";
CM_ SG_ 1009 RCM2_a058_driverABStg2Open "RCM2 ECU: a058 driver AB stg2 open";
CM_ SG_ 1009 RCM2_a059_driverABStg2Short "RCM2 ECU: a059 driver AB stg2 short";
CM_ SG_ 1009 RCM2_a060_driverABStg2CrssCoup "RCM2 ECU: a060 driver AB stg2 crss coup";
CM_ SG_ 1009 RCM2_a061_driverABStg2Config "RCM2 ECU: a061 driver AB stg2 config";
CM_ SG_ 1009 RCM2_a062_passABStg1Sht2Gnd "RCM2 ECU: a062 pass AB stg1 sht2 gnd";
CM_ SG_ 1009 RCM2_a063_passABStg1Sht2Bat "RCM2 ECU: a063 pass AB stg1 sht2 bat";
CM_ SG_ 1009 RCM2_a064_passABStg1Open "RCM2 ECU: a064 pass AB stg1 open";
CM_ SG_ 1009 RCM2_a065_passABStg1Short "RCM2 ECU: a065 pass AB stg1 short";
CM_ SG_ 1009 RCM2_a066_passABStg1CrssCoup "RCM2 ECU: a066 pass AB stg1 crss coup";
CM_ SG_ 1009 RCM2_a067_passABStg1Config "RCM2 ECU: a067 pass AB stg1 config";
CM_ SG_ 1009 RCM2_a068_passABStg2Sht2Gnd "RCM2 ECU: a068 pass AB stg2 sht2 gnd";
CM_ SG_ 1009 RCM2_a069_passABStg2Sht2Bat "RCM2 ECU: a069 pass AB stg2 sht2 bat";
CM_ SG_ 1009 RCM2_a070_passABStg2Open "RCM2 ECU: a070 pass AB stg2 open";
CM_ SG_ 1009 RCM2_a071_passABStg2Short "RCM2 ECU: a071 pass AB stg2 short";
CM_ SG_ 1009 RCM2_a072_passABStg2CrssCoup "RCM2 ECU: a072 pass AB stg2 crss coup";
CM_ SG_ 1009 RCM2_a073_passABStg2Config "RCM2 ECU: a073 pass AB stg2 config";
CM_ SG_ 1009 RCM2_a074_passActiveVentSht2Gnd "RCM2 ECU: a074 pass active vent sht2 gnd";
CM_ SG_ 1009 RCM2_a075_passActiveVentSht2Bat "RCM2 ECU: a075 pass active vent sht2 bat";
CM_ SG_ 1009 RCM2_a076_passActiveVentOpen "RCM2 ECU: a076 pass active vent open";
CM_ SG_ 1009 RCM2_a077_passActiveVentShort "RCM2 ECU: a077 pass active vent short";
CM_ SG_ 1009 RCM2_a078_passActiveVentCrssCoup "RCM2 ECU: a078 pass active vent crss coup";
CM_ SG_ 1009 RCM2_a079_passActiveVentConfig "RCM2 ECU: a079 pass active vent config";
CM_ SG_ 1009 RCM2_a080_pretenShldLeftSht2Gnd "RCM2 ECU: a080 preten shld left sht2 gnd";
CM_ SG_ 1009 RCM2_a081_pretenShldLeftSht2Bat "RCM2 ECU: a081 preten shld left sht2 bat";
CM_ SG_ 1009 RCM2_a082_pretenShldLeftOpen "RCM2 ECU: a082 preten shld left open";
CM_ SG_ 1009 RCM2_a083_pretenShldLeftShort "RCM2 ECU: a083 preten shld left short";
CM_ SG_ 1009 RCM2_a084_pretenShldLeftCrossC "RCM2 ECU: a084 preten shld left cross c";
CM_ SG_ 1009 RCM2_a085_pretenShldLeftConfig "RCM2 ECU: a085 preten shld left config";
CM_ SG_ 1009 RCM2_a086_pretenShldRightSht2Gnd "RCM2 ECU: a086 preten shld right sht2 gnd";
CM_ SG_ 1009 RCM2_a087_pretenShldRightSht2Bat "RCM2 ECU: a087 preten shld right sht2 bat";
CM_ SG_ 1009 RCM2_a088_pretenShldRightOpen "RCM2 ECU: a088 preten shld right open";
CM_ SG_ 1009 RCM2_a089_pretenShldRightShort "RCM2 ECU: a089 preten shld right short";
CM_ SG_ 1009 RCM2_a090_pretenShldRightCrssCou "RCM2 ECU: a090 preten shld right crss cou";
CM_ SG_ 1009 RCM2_a091_pretenShldRightConfig "RCM2 ECU: a091 preten shld right config";
CM_ SG_ 1009 RCM2_a092_pretenLapLeftSht2Gnd "RCM2 ECU: a092 preten lap left sht2 gnd";
CM_ SG_ 1009 RCM2_a093_pretenLapLeftSht2Bat "RCM2 ECU: a093 preten lap left sht2 bat";
CM_ SG_ 1009 RCM2_a094_pretenLapLeftOpen "RCM2 ECU: a094 preten lap left open";
CM_ SG_ 1009 RCM2_a095_pretenLapLeftShort "RCM2 ECU: a095 preten lap left short";
CM_ SG_ 1009 RCM2_a096_pretenLapLeftCrssCoup "RCM2 ECU: a096 preten lap left crss coup";
CM_ SG_ 1009 RCM2_a097_pretenLapLeftConfig "RCM2 ECU: a097 preten lap left config";
CM_ SG_ 1009 RCM2_a098_pretenLapRightSht2Gnd "RCM2 ECU: a098 preten lap right sht2 gnd";
CM_ SG_ 1009 RCM2_a099_pretenLapRightSht2Bat "RCM2 ECU: a099 preten lap right sht2 bat";
CM_ SG_ 1009 RCM2_a100_pretenLapRightOpen "RCM2 ECU: a100 preten lap right open";
CM_ SG_ 1009 RCM2_a101_pretenLapRightShort "RCM2 ECU: a101 preten lap right short";
CM_ SG_ 1009 RCM2_a102_pretenLapRightCrssCoup "RCM2 ECU: a102 preten lap right crss coup";
CM_ SG_ 1009 RCM2_a103_pretenLapRightConfig "RCM2 ECU: a103 preten lap right config";
CM_ SG_ 1009 RCM2_a104_loadLimLeftSht2Gnd "RCM2 ECU: a104 load lim left sht2 gnd";
CM_ SG_ 1009 RCM2_a105_loadLimLeftSht2Bat "RCM2 ECU: a105 load lim left sht2 bat";
CM_ SG_ 1009 RCM2_a106_loadLimLeftOpen "RCM2 ECU: a106 load lim left open";
CM_ SG_ 1009 RCM2_a107_loadLimLeftShort "RCM2 ECU: a107 load lim left short";
CM_ SG_ 1009 RCM2_a108_loadLimLeftCrssCoup "RCM2 ECU: a108 load lim left crss coup";
CM_ SG_ 1009 RCM2_a109_loadLimLeftConfig "RCM2 ECU: a109 load lim left config";
CM_ SG_ 1009 RCM2_a110_loadLimRightSht2Gnd "RCM2 ECU: a110 load lim right sht2 gnd";
CM_ SG_ 1009 RCM2_a111_loadLimRightSht2Bat "RCM2 ECU: a111 load lim right sht2 bat";
CM_ SG_ 1009 RCM2_a112_loadLimRightOpen "RCM2 ECU: a112 load lim right open";
CM_ SG_ 1009 RCM2_a113_loadLimRightShort "RCM2 ECU: a113 load lim right short";
CM_ SG_ 1009 RCM2_a114_loadLimRightCrssCoup "RCM2 ECU: a114 load lim right crss coup";
CM_ SG_ 1009 RCM2_a115_loadLimRightConfig "RCM2 ECU: a115 load lim right config";
CM_ SG_ 1009 RCM2_a116_kneeABDrvrSht2Gnd "RCM2 ECU: a116 knee AB drvr sht2 gnd";
CM_ SG_ 1009 RCM2_a117_kneeABDrvrSht2Bat "RCM2 ECU: a117 knee AB drvr sht2 bat";
CM_ SG_ 1009 RCM2_a118_kneeABDrvrOpen "RCM2 ECU: a118 knee AB drvr open";
CM_ SG_ 1009 RCM2_a119_kneeABDrvrShort "RCM2 ECU: a119 knee AB drvr short";
CM_ SG_ 1009 RCM2_a120_kneeABDrvrCrssCoup "RCM2 ECU: a120 knee AB drvr crss coup";
CM_ SG_ 1009 RCM2_a121_kneeABDrvrConfig "RCM2 ECU: a121 knee AB drvr config";
CM_ SG_ 1009 RCM2_a122_kneeABPassSht2Gnd "RCM2 ECU: a122 knee AB pass sht2 gnd";
CM_ SG_ 1009 RCM2_a123_kneeABPassSht2Bat "RCM2 ECU: a123 knee AB pass sht2 bat";
CM_ SG_ 1009 RCM2_a124_kneeABPassOpen "RCM2 ECU: a124 knee AB pass open";
CM_ SG_ 1009 RCM2_a125_kneeABPassShort "RCM2 ECU: a125 knee AB pass short";
CM_ SG_ 1009 RCM2_a126_kneeABPassCrssCoup "RCM2 ECU: a126 knee AB pass crss coup";
CM_ SG_ 1009 RCM2_a127_kneeABPassConfig "RCM2 ECU: a127 knee AB pass config";
CM_ SG_ 1009 RCM2_a128_sideAB1stRowLSht2Gnd "RCM2 ECU: a128 side ab1st row l sht2 gnd";
CM_ SG_ 1009 RCM2_a129_sideAB1stRowLSht2Bat "RCM2 ECU: a129 side ab1st row l sht2 bat";
CM_ SG_ 1009 RCM2_a130_sideAB1stRowLOpen "RCM2 ECU: a130 side ab1st row l open";
CM_ SG_ 1009 RCM2_a131_sideAB1stRowLShort "RCM2 ECU: a131 side ab1st row l short";
CM_ SG_ 1009 RCM2_a132_sideAB1stRowLCrssCoup "RCM2 ECU: a132 side ab1st row l crss coup";
CM_ SG_ 1009 RCM2_a133_sideAB1stRowLConfig "RCM2 ECU: a133 side ab1st row l config";
CM_ SG_ 1009 RCM2_a134_sideAB1stRowRSht2Gnd "RCM2 ECU: a134 side ab1st row r sht2 gnd";
CM_ SG_ 1009 RCM2_a135_sideAB1stRowRSht2Bat "RCM2 ECU: a135 side ab1st row r sht2 bat";
CM_ SG_ 1009 RCM2_a136_sideAB1stRowROpen "RCM2 ECU: a136 side ab1st row r open";
CM_ SG_ 1009 RCM2_a137_sideAB1stRowRShort "RCM2 ECU: a137 side ab1st row r short";
CM_ SG_ 1009 RCM2_a138_sideAB1stRowRCrssCoup "RCM2 ECU: a138 side ab1st row r crss coup";
CM_ SG_ 1009 RCM2_a139_sideAB1stRowRConfig "RCM2 ECU: a139 side ab1st row r config";
CM_ SG_ 1009 RCM2_a140_hvdPyroSht2Gnd "RCM2 ECU: a140 hvd pyro sht2 gnd";
CM_ SG_ 1009 RCM2_a141_hvdPyroSht2Bat "RCM2 ECU: a141 hvd pyro sht2 bat";
CM_ SG_ 1009 RCM2_a142_hvdPyroOpen "RCM2 ECU: a142 hvd pyro open";
CM_ SG_ 1009 RCM2_a143_hvdPyroShort "RCM2 ECU: a143 hvd pyro short";
CM_ SG_ 1009 RCM2_a144_hvdPyroCrssCoup "RCM2 ECU: a144 hvd pyro crss coup";
CM_ SG_ 1009 RCM2_a145_hvdPyroConfig "RCM2 ECU: a145 hvd pyro config";
CM_ SG_ 1009 RCM2_a146_curABLeftSht2Gnd "RCM2 ECU: a146 cur AB left sht2 gnd";
CM_ SG_ 1009 RCM2_a147_curABLeftSht2Bat "RCM2 ECU: a147 cur AB left sht2 bat";
CM_ SG_ 1009 RCM2_a148_curABLeftOpen "RCM2 ECU: a148 cur AB left open";
CM_ SG_ 1009 RCM2_a149_curABLeftShort "RCM2 ECU: a149 cur AB left short";
CM_ SG_ 1009 RCM2_a150_curABLeftCrssCoup "RCM2 ECU: a150 cur AB left crss coup";
CM_ SG_ 1009 RCM2_a151_curABLeftConfig "RCM2 ECU: a151 cur AB left config";
CM_ SG_ 1009 RCM2_a152_curABRightSht2Gnd "RCM2 ECU: a152 cur AB right sht2 gnd";
CM_ SG_ 1009 RCM2_a153_curABRightSht2Bat "RCM2 ECU: a153 cur AB right sht2 bat";
CM_ SG_ 1009 RCM2_a154_curABRightOpen "RCM2 ECU: a154 cur AB right open";
CM_ SG_ 1009 RCM2_a155_curABRightShort "RCM2 ECU: a155 cur AB right short";
CM_ SG_ 1009 RCM2_a156_curABRightCrssCoup "RCM2 ECU: a156 cur AB right crss coup";
CM_ SG_ 1009 RCM2_a157_curABRightConfig "RCM2 ECU: a157 cur AB right config";
CM_ SG_ 1009 RCM2_a158_preten2ndRowLSht2Gnd "RCM2 ECU: a158 preten2nd row l sht2 gnd";
CM_ SG_ 1009 RCM2_a159_preten2ndRowLSht2Bat "RCM2 ECU: a159 preten2nd row l sht2 bat";
CM_ SG_ 1009 RCM2_a160_preten2ndRowLOpen "RCM2 ECU: a160 preten2nd row l open";
CM_ SG_ 1009 RCM2_a161_preten2ndRowLShort "RCM2 ECU: a161 preten2nd row l short";
CM_ SG_ 1009 RCM2_a162_preten2ndRowLCrssCoup "RCM2 ECU: a162 preten2nd row l crss coup";
CM_ SG_ 1009 RCM2_a163_preten2ndRowLCgf "RCM2 ECU: a163 preten2nd row l cgf";
CM_ SG_ 1009 RCM2_a164_preten2ndRowRSht2Gnd "RCM2 ECU: a164 preten2nd row r sht2 gnd";
CM_ SG_ 1009 RCM2_a165_preten2ndRowRSht2Bat "RCM2 ECU: a165 preten2nd row r sht2 bat";
CM_ SG_ 1009 RCM2_a166_preten2ndRowROpen "RCM2 ECU: a166 preten2nd row r open";
CM_ SG_ 1009 RCM2_a167_preten2ndRowRShort "RCM2 ECU: a167 preten2nd row r short";
CM_ SG_ 1009 RCM2_a168_preten2ndRowRCrssCoup "RCM2 ECU: a168 preten2nd row r crss coup";
CM_ SG_ 1009 RCM2_a169_preten2ndRowRCgf "RCM2 ECU: a169 preten2nd row r cgf";
CM_ SG_ 1009 RCM2_a170_curAB2ndRowLSht2Gnd "RCM2 ECU: a170 cur ab2nd row l sht2 gnd";
CM_ SG_ 1009 RCM2_a171_curAB2ndRowLSht2Bat "RCM2 ECU: a171 cur ab2nd row l sht2 bat";
CM_ SG_ 1009 RCM2_a172_curAB2ndRowLOpen "RCM2 ECU: a172 cur ab2nd row l open";
CM_ SG_ 1009 RCM2_a173_curAB2ndRowLShort "RCM2 ECU: a173 cur ab2nd row l short";
CM_ SG_ 1009 RCM2_a174_curAB2ndRowLCrssCoup "RCM2 ECU: a174 cur ab2nd row l crss coup";
CM_ SG_ 1009 RCM2_a175_curAB2ndRowLConfig "RCM2 ECU: a175 cur ab2nd row l config";
CM_ SG_ 1009 RCM2_a176_curAB2ndRowRSht2Gnd "RCM2 ECU: a176 cur ab2nd row r sht2 gnd";
CM_ SG_ 1009 RCM2_a177_curAB2ndRowRSht2Bat "RCM2 ECU: a177 cur ab2nd row r sht2 bat";
CM_ SG_ 1009 RCM2_a178_curAB2ndRowROpen "RCM2 ECU: a178 cur ab2nd row r open";
CM_ SG_ 1009 RCM2_a179_curAB2ndRowRShort "RCM2 ECU: a179 cur ab2nd row r short";
CM_ SG_ 1009 RCM2_a180_curAB2ndRowRCrssCoup "RCM2 ECU: a180 cur ab2nd row r crss coup";
CM_ SG_ 1009 RCM2_a181_curAB2ndRowRConfig "RCM2 ECU: a181 cur ab2nd row r config";
CM_ SG_ 1009 RCM2_a182_hoodActuatorRSht2Gnd "RCM2 ECU: a182 hood actuator r sht2 gnd";
CM_ SG_ 1009 RCM2_a183_hoodActuatorRSht2Bat "RCM2 ECU: a183 hood actuator r sht2 bat";
CM_ SG_ 1009 RCM2_a184_hoodActuatorROpen "RCM2 ECU: a184 hood actuator r open";
CM_ SG_ 1009 RCM2_a185_hoodActuatorRShort "RCM2 ECU: a185 hood actuator r short";
CM_ SG_ 1009 RCM2_a186_hoodActuatorRCrssCoup "RCM2 ECU: a186 hood actuator r crss coup";
CM_ SG_ 1009 RCM2_a187_hoodActuatorRConfig "RCM2 ECU: a187 hood actuator r config";
CM_ SG_ 1009 RCM2_a188_hoodActuatorLSht2Gnd "RCM2 ECU: a188 hood actuator l sht2 gnd";
CM_ SG_ 1009 RCM2_a189_hoodActuatorLSht2Bat "RCM2 ECU: a189 hood actuator l sht2 bat";
CM_ SG_ 1009 RCM2_a190_hoodActuatorLOpen "RCM2 ECU: a190 hood actuator l open";
CM_ SG_ 1009 RCM2_a191_hoodActuatorLShort "RCM2 ECU: a191 hood actuator l short";
CM_ SG_ 1009 RCM2_a192_hoodActuatorLCrssCoup "RCM2 ECU: a192 hood actuator l crss coup";
CM_ SG_ 1009 RCM2_a193_hoodActuatorLConfig "RCM2 ECU: a193 hood actuator l config";
CM_ SG_ 1009 RCM2_a194_driverABAVSht2Gnd "RCM2 ECU: a194 driver ABAV sht2 gnd";
CM_ SG_ 1009 RCM2_a195_driverABAVSht2Bat "RCM2 ECU: a195 driver ABAV sht2 bat";
CM_ SG_ 1009 RCM2_a196_driverABAVOpen "RCM2 ECU: a196 driver ABAV open";
CM_ SG_ 1009 RCM2_a197_driverABAVShort "RCM2 ECU: a197 driver ABAV short";
CM_ SG_ 1009 RCM2_a198_driverABAVCrossCoup "RCM2 ECU: a198 driver ABAV cross coup";
CM_ SG_ 1009 RCM2_a199_driverABAVConfig "RCM2 ECU: a199 driver ABAV config";
CM_ SG_ 1009 RCM2_a200_driverFSABSht2Gnd "RCM2 ECU: a200 driver FSAB sht2 gnd";
CM_ SG_ 1009 RCM2_a201_driverFSABSht2Bat "RCM2 ECU: a201 driver FSAB sht2 bat";
CM_ SG_ 1009 RCM2_a202_driverFSABOpen "RCM2 ECU: a202 driver FSAB open";
CM_ SG_ 1009 RCM2_a203_driverFSABShort "RCM2 ECU: a203 driver FSAB short";
CM_ SG_ 1009 RCM2_a204_driverFSABCrossCoup "RCM2 ECU: a204 driver FSAB cross coup";
CM_ SG_ 1009 RCM2_a205_driverFSABConfig "RCM2 ECU: a205 driver FSAB config";
CM_ SG_ 1009 RCM2_a206_sideAB2ndRowLSht2Gnd "RCM2 ECU: a206 side ab2nd row l sht2 gnd";
CM_ SG_ 1009 RCM2_a207_sideAB2ndRowLSht2Bat "RCM2 ECU: a207 side ab2nd row l sht2 bat";
CM_ SG_ 1009 RCM2_a208_sideAB2ndRowLOpen "RCM2 ECU: a208 side ab2nd row l open";
CM_ SG_ 1009 RCM2_a209_sideAB2ndRowLShort "RCM2 ECU: a209 side ab2nd row l short";
CM_ SG_ 1009 RCM2_a210_sideAB2ndRowLCrssCoup "RCM2 ECU: a210 side ab2nd row l crss coup";
CM_ SG_ 1009 RCM2_a211_sideAB2ndRowLConfig "RCM2 ECU: a211 side ab2nd row l config";
CM_ SG_ 1009 RCM2_a212_sideAB2ndRowRSht2Gnd "RCM2 ECU: a212 side ab2nd row r sht2 gnd";
CM_ SG_ 1009 RCM2_a213_sideAB2ndRowRSht2Bat "RCM2 ECU: a213 side ab2nd row r sht2 bat";
CM_ SG_ 1009 RCM2_a214_sideAB2ndRowROpen "RCM2 ECU: a214 side ab2nd row r open";
CM_ SG_ 1009 RCM2_a215_sideAB2ndRowRShort "RCM2 ECU: a215 side ab2nd row r short";
CM_ SG_ 1009 RCM2_a216_sideAB2ndRowRCrssCoup "RCM2 ECU: a216 side ab2nd row r crss coup";
CM_ SG_ 1009 RCM2_a217_sideAB2ndRowRConfig "RCM2 ECU: a217 side ab2nd row r config";
CM_ SG_ 1009 RCM2_a250_ens1Sht2Bat "RCM2 ECU: a250 ens1 sht2 bat";
CM_ SG_ 1009 RCM2_a251_ens1Sht2Gnd "RCM2 ECU: a251 ens1 sht2 gnd";
CM_ SG_ 1009 RCM2_a252_ens1Config "RCM2 ECU: a252 ens1 config";
CM_ SG_ 1009 RCM2_a253_ens2Sht2Bat "RCM2 ECU: a253 ens2 sht2 bat";
CM_ SG_ 1009 RCM2_a254_ens2Sht2Gnd "RCM2 ECU: a254 ens2 sht2 gnd";
CM_ SG_ 1009 RCM2_a255_ens2Config "RCM2 ECU: a255 ens2 config";
CM_ SG_ 1009 RCM2_a256_ens3Sht2Bat "RCM2 ECU: a256 ens3 sht2 bat";
CM_ SG_ 1009 RCM2_a257_ens3Sht2Gnd "RCM2 ECU: a257 ens3 sht2 gnd";
CM_ SG_ 1009 RCM2_a258_ens3Config "RCM2 ECU: a258 ens3 config";
CM_ SG_ 1009 RCM2_a259_ens4Sht2Bat "RCM2 ECU: a259 ens4 sht2 bat";
CM_ SG_ 1009 RCM2_a260_ens4Sht2Gnd "RCM2 ECU: a260 ens4 sht2 gnd";
CM_ SG_ 1009 RCM2_a261_ens4Config "RCM2 ECU: a261 ens4 config";
CM_ SG_ 1009 RCM2_a264_imuYawR8OffCompPosLife "RCM2 ECU: a264 imu yaw R8 off comp pos life";
CM_ SG_ 1009 RCM2_a265_imuYawR8OffCompNegLife "RCM2 ECU: a265 imu yaw R8 off comp neg life";
CM_ SG_ 1009 RCM2_a266_imuYawR8OffCompPosFLDC "RCM2 ECU: a266 imu yaw R8 off comp pos FLDC";
CM_ SG_ 1009 RCM2_a267_imuYawR8OffCompNegFLDC "RCM2 ECU: a267 imu yaw R8 off comp neg FLDC";
CM_ SG_ 1009 RCM2_a268_imuYawR8OffCompPosSLDC "RCM2 ECU: a268 imu yaw R8 off comp pos SLDC";
CM_ SG_ 1009 RCM2_a269_imuYawR8OffCompNegSLDC "RCM2 ECU: a269 imu yaw R8 off comp neg SLDC";
CM_ SG_ 1009 RCM2_a270_imuPtchR8OffCompPosLif "RCM2 ECU: a270 imu ptch R8 off comp pos life";
CM_ SG_ 1009 RCM2_a271_imuPtchR8OffCompNegLif "RCM2 ECU: a271 imu ptch R8 off comp neg life";
CM_ SG_ 1009 RCM2_a272_imuPtchR8OffCompPosFLD "RCM2 ECU: a272 imu ptch R8 off comp pos FLDC";
CM_ SG_ 1009 RCM2_a273_imuPtchR8OffCompNegFLD "RCM2 ECU: a273 imu ptch R8 off comp neg FLDC";
CM_ SG_ 1009 RCM2_a274_imuPtchR8OffCompPosSLD "RCM2 ECU: a274 imu ptch R8 off comp pos SLDC";
CM_ SG_ 1009 RCM2_a275_imuPtchR8OffCompNegSLD "RCM2 ECU: a275 imu ptch R8 off comp neg SLDC";
CM_ SG_ 1009 RCM2_a276_imuRollR8OffCompPosLif "RCM2 ECU: a276 imu roll R8 off comp pos life";
CM_ SG_ 1009 RCM2_a277_imuRollR8OffCompNegLif "RCM2 ECU: a277 imu roll R8 off comp neg life";
CM_ SG_ 1009 RCM2_a278_imuRollR8OffCompPosFLD "RCM2 ECU: a278 imu roll R8 off comp pos FLDC";
CM_ SG_ 1009 RCM2_a279_imuRollR8OffCompNegFLD "RCM2 ECU: a279 imu roll R8 off comp neg FLDC";
CM_ SG_ 1009 RCM2_a280_imuRollR8OffCompPosSLD "RCM2 ECU: a280 imu roll R8 off comp pos SLDC";
CM_ SG_ 1009 RCM2_a281_imuRollR8OffCompNegSLD "RCM2 ECU: a281 imu roll R8 off comp neg SLDC";
CM_ SG_ 1009 RCM2_a282_imuLongAOffCompPosLife "RCM2 ECU: a282 imu long a off comp pos life";
CM_ SG_ 1009 RCM2_a283_imuLongAOffCompNegLife "RCM2 ECU: a283 imu long a off comp neg life";
CM_ SG_ 1009 RCM2_a284_imuLongAOffCompPosFLDC "RCM2 ECU: a284 imu long a off comp pos FLDC";
CM_ SG_ 1009 RCM2_a285_imuLongAOffCompNegFLDC "RCM2 ECU: a285 imu long a off comp neg FLDC";
CM_ SG_ 1009 RCM2_a286_imuLongAOffCompPosSLDC "RCM2 ECU: a286 imu long a off comp pos SLDC";
CM_ SG_ 1009 RCM2_a287_imuLongAOffCompNegSLDC "RCM2 ECU: a287 imu long a off comp neg SLDC";
CM_ SG_ 1009 RCM2_a288_imuLatAcOffCompPosLife "RCM2 ECU: a288 imu lat ac off comp pos life";
CM_ SG_ 1009 RCM2_a289_imuLatAcOffCompNegLife "RCM2 ECU: a289 imu lat ac off comp neg life";
CM_ SG_ 1009 RCM2_a290_imuLatAcOffCompPosFLDC "RCM2 ECU: a290 imu lat ac off comp pos FLDC";
CM_ SG_ 1009 RCM2_a291_imuLatAcOffCompNegFLDC "RCM2 ECU: a291 imu lat ac off comp neg FLDC";
CM_ SG_ 1009 RCM2_a292_imuLatAcOffCompPosSLDC "RCM2 ECU: a292 imu lat ac off comp pos SLDC";
CM_ SG_ 1009 RCM2_a293_imuLatAcOffCompNegSLDC "RCM2 ECU: a293 imu lat ac off comp neg SLDC";
CM_ SG_ 1009 RCM2_a294_imuVertAOffCompPosLife "RCM2 ECU: a294 imu vert a off comp pos life";
CM_ SG_ 1009 RCM2_a295_imuVertAOffCompNegLife "RCM2 ECU: a295 imu vert a off comp neg life";
CM_ SG_ 1009 RCM2_a296_imuVertAOffCompPosFLDC "RCM2 ECU: a296 imu vert a off comp pos FLDC";
CM_ SG_ 1009 RCM2_a297_imuVertAOffCompNegFLDC "RCM2 ECU: a297 imu vert a off comp neg FLDC";
CM_ SG_ 1009 RCM2_a298_imuVertAOffCompPosSLDC "RCM2 ECU: a298 imu vert a off comp pos SLDC";
CM_ SG_ 1009 RCM2_a299_imuVertAOffCompNegSLDC "RCM2 ECU: a299 imu vert a off comp neg SLDC";
CM_ SG_ 1009 RCM2_a300_imuAccXHgMonChlPerm "RCM2 ECU: a300 imu acc x hg mon chl perm";
CM_ SG_ 1009 RCM2_a301_imuAccXHgMonChlTemp "RCM2 ECU: a301 imu acc x hg mon chl temp";
CM_ SG_ 1009 RCM2_a302_imuAccYHgMonChlPerm "RCM2 ECU: a302 imu acc y hg mon chl perm";
CM_ SG_ 1009 RCM2_a303_imuAccYHgMonChlTemp "RCM2 ECU: a303 imu acc y hg mon chl temp";
CM_ SG_ 1009 RCM2_a304_imuYawR8SnsrPermBG "RCM2 ECU: a304 imu yaw R8 snsr perm BG";
CM_ SG_ 1009 RCM2_a305_imuYawR8SnsrPermInit "RCM2 ECU: a305 imu yaw R8 snsr perm init";
CM_ SG_ 1009 RCM2_a306_imuYawR8SnsrPermLF "RCM2 ECU: a306 imu yaw R8 snsr perm LF";
CM_ SG_ 1009 RCM2_a307_imuYawR8ChnlMonTmpLF "RCM2 ECU: a307 imu yaw R8 chnl mon tmp LF";
CM_ SG_ 1009 RCM2_a308_imuPitchR8SnsrPermBG "RCM2 ECU: a308 imu pitch R8 snsr perm BG";
CM_ SG_ 1009 RCM2_a309_imuPitchR8SnsrPermInit "RCM2 ECU: a309 imu pitch R8 snsr perm init";
CM_ SG_ 1009 RCM2_a310_imuPitchR8SnsrPermLF "RCM2 ECU: a310 imu pitch R8 snsr perm LF";
CM_ SG_ 1009 RCM2_a311_imuPitchR8ChnlMonTmpLF "RCM2 ECU: a311 imu pitch R8 chnl mon tmp LF";
CM_ SG_ 1009 RCM2_a312_imuRollR8SnsrPermBG "RCM2 ECU: a312 imu roll R8 snsr perm BG";
CM_ SG_ 1009 RCM2_a313_imuRollR8SnsrPermInit "RCM2 ECU: a313 imu roll R8 snsr perm init";
CM_ SG_ 1009 RCM2_a314_imuRollR8SnsrPermLF "RCM2 ECU: a314 imu roll R8 snsr perm LF";
CM_ SG_ 1009 RCM2_a315_imuRollR8ChnlMonTmpLF "RCM2 ECU: a315 imu roll R8 chnl mon tmp LF";
CM_ SG_ 1009 RCM2_a316_imuAccXLgMonChlPerm "RCM2 ECU: a316 imu acc x lg mon chl perm";
CM_ SG_ 1009 RCM2_a317_imuAccXLgMonChlTemp "RCM2 ECU: a317 imu acc x lg mon chl temp";
CM_ SG_ 1009 RCM2_a318_imuAccYLgMonChlPerm "RCM2 ECU: a318 imu acc y lg mon chl perm";
CM_ SG_ 1009 RCM2_a319_imuAccYLgMonChlTemp "RCM2 ECU: a319 imu acc y lg mon chl temp";
CM_ SG_ 1009 RCM2_a320_imuAccZLgMonChlPerm "RCM2 ECU: a320 imu acc z lg mon chl perm";
CM_ SG_ 1009 RCM2_a321_imuAccZLgMonChlTemp "RCM2 ECU: a321 imu acc z lg mon chl temp";
CM_ SG_ 1009 RCM2_a322_imuCalibrationFailed "RCM2 ECU: a322 imu calibration failed";
CM_ SG_ 1009 RCM2_a323_imuCalibrationNotDone "RCM2 ECU: a323 imu calibration not done";
CM_ SG_ 1009 RCM2_a350_upFrntSnsrLSht2Gnd "RCM2 ECU: a350 up frnt snsr l sht2 gnd";
CM_ SG_ 1009 RCM2_a351_upFrntSnsrLSht2Bat "RCM2 ECU: a351 up frnt snsr l sht2 bat";
CM_ SG_ 1009 RCM2_a352_upFrntSnsrLOpen "RCM2 ECU: a352 up frnt snsr l open";
CM_ SG_ 1009 RCM2_a353_upFrntSnsrLCrssCoup "RCM2 ECU: a353 up frnt snsr l crss coup";
CM_ SG_ 1009 RCM2_a354_upFrntSnsrLCommErr "RCM2 ECU: a354 up frnt snsr l comm err";
CM_ SG_ 1009 RCM2_a355_upFrntSnsrLInitTyp "RCM2 ECU: a355 up frnt snsr l init typ";
CM_ SG_ 1009 RCM2_a356_upFrntSnsrLConfig "RCM2 ECU: a356 up frnt snsr l config";
CM_ SG_ 1009 RCM2_a357_upFrntSnsrLDefect "RCM2 ECU: a357 up frnt snsr l defect";
CM_ SG_ 1009 RCM2_a358_upFrntSnsrLSigMon "RCM2 ECU: a358 up frnt snsr l sig mon";
CM_ SG_ 1009 RCM2_a360_upFrntSnsrRSht2Gnd "RCM2 ECU: a360 up frnt snsr r sht2 gnd";
CM_ SG_ 1009 RCM2_a361_upFrntSnsrRSht2Bat "RCM2 ECU: a361 up frnt snsr r sht2 bat";
CM_ SG_ 1009 RCM2_a362_upFrntSnsrROpen "RCM2 ECU: a362 up frnt snsr r open";
CM_ SG_ 1009 RCM2_a363_upFrntSnsrRCrssCoup "RCM2 ECU: a363 up frnt snsr r crss coup";
CM_ SG_ 1009 RCM2_a364_upFrntSnsrRCommErr "RCM2 ECU: a364 up frnt snsr r comm err";
CM_ SG_ 1009 RCM2_a365_upFrntSnsrRInitTyp "RCM2 ECU: a365 up frnt snsr r init typ";
CM_ SG_ 1009 RCM2_a366_upFrntSnsrRConfig "RCM2 ECU: a366 up frnt snsr r config";
CM_ SG_ 1009 RCM2_a367_upFrntSnsrRDefect "RCM2 ECU: a367 up frnt snsr r defect";
CM_ SG_ 1009 RCM2_a368_upFrntSnsrRSigMon "RCM2 ECU: a368 up frnt snsr r sig mon";
CM_ SG_ 1009 RCM2_a370_upFrntSnsrMidLSht2Gnd "RCM2 ECU: a370 up frnt snsr mid l sht2 gnd";
CM_ SG_ 1009 RCM2_a371_upFrntSnsrMidLSht2Bat "RCM2 ECU: a371 up frnt snsr mid l sht2 bat";
CM_ SG_ 1009 RCM2_a372_upFrntSnsrMidLOpen "RCM2 ECU: a372 up frnt snsr mid l open";
CM_ SG_ 1009 RCM2_a373_upFrntSnsrMidLCrssCoup "RCM2 ECU: a373 up frnt snsr mid l crss coup";
CM_ SG_ 1009 RCM2_a374_upFrntSnsrMidLCommErr "RCM2 ECU: a374 up frnt snsr mid l comm err";
CM_ SG_ 1009 RCM2_a375_upFrntSnsrMidLInitTyp "RCM2 ECU: a375 up frnt snsr mid l init typ";
CM_ SG_ 1009 RCM2_a376_upFrntSnsrMidLConfig "RCM2 ECU: a376 up frnt snsr mid l config";
CM_ SG_ 1009 RCM2_a377_upFrntSnsrMidLDefect "RCM2 ECU: a377 up frnt snsr mid l defect";
CM_ SG_ 1009 RCM2_a378_upFrntSnsrMidLSigMon "RCM2 ECU: a378 up frnt snsr mid l sig mon";
CM_ SG_ 1009 RCM2_a380_upFrntSnsrMidRSht2Gnd "RCM2 ECU: a380 up frnt snsr mid r sht2 gnd";
CM_ SG_ 1009 RCM2_a381_upFrntSnsrMidRSht2Bat "RCM2 ECU: a381 up frnt snsr mid r sht2 bat";
CM_ SG_ 1009 RCM2_a382_upFrntSnsrMidROpen "RCM2 ECU: a382 up frnt snsr mid r open";
CM_ SG_ 1009 RCM2_a383_upFrntSnsrMidRCrssCoup "RCM2 ECU: a383 up frnt snsr mid r crss coup";
CM_ SG_ 1009 RCM2_a384_upFrntSnsrMidRCommErr "RCM2 ECU: a384 up frnt snsr mid r comm err";
CM_ SG_ 1009 RCM2_a385_upFrntSnsrMidRInitTyp "RCM2 ECU: a385 up frnt snsr mid r init typ";
CM_ SG_ 1009 RCM2_a386_upFrntSnsrMidRConfig "RCM2 ECU: a386 up frnt snsr mid r config";
CM_ SG_ 1009 RCM2_a387_upFrntSnsrMidRDefect "RCM2 ECU: a387 up frnt snsr mid r defect";
CM_ SG_ 1009 RCM2_a388_upFrntSnsrMidRSigMon "RCM2 ECU: a388 up frnt snsr mid r sig mon";
CM_ SG_ 1009 RCM2_a390_sideAccelBPilLSht2Gnd "RCM2 ECU: a390 side accel b pil l sht2 gnd";
CM_ SG_ 1009 RCM2_a391_sideAccelBPilLSht2Bat "RCM2 ECU: a391 side accel b pil l sht2 bat";
CM_ SG_ 1009 RCM2_a392_sideAccelBPilLOpen "RCM2 ECU: a392 side accel b pil l open";
CM_ SG_ 1009 RCM2_a393_sideAccelBPilLCLosCoup "RCM2 ECU: a393 side accel b pil LC los coup";
CM_ SG_ 1009 RCM2_a394_sideAccelBPilLCommErr "RCM2 ECU: a394 side accel b pil l comm err";
CM_ SG_ 1009 RCM2_a395_sideAccelBPilLInitTyp "RCM2 ECU: a395 side accel b pil l init typ";
CM_ SG_ 1009 RCM2_a396_sideAccelBPilLConfig "RCM2 ECU: a396 side accel b pil l config";
CM_ SG_ 1009 RCM2_a397_sideAccelBPilLDefect "RCM2 ECU: a397 side accel b pil l defect";
CM_ SG_ 1009 RCM2_a398_sideAccelBPilLSigMon "RCM2 ECU: a398 side accel b pil l sig mon";
CM_ SG_ 1009 RCM2_a400_sideAccelBPilRSht2Gnd "RCM2 ECU: a400 side accel b pil r sht2 gnd";
CM_ SG_ 1009 RCM2_a401_sideAccelBPilRSht2Bat "RCM2 ECU: a401 side accel b pil r sht2 bat";
CM_ SG_ 1009 RCM2_a402_sideAccelBPilROpen "RCM2 ECU: a402 side accel b pil r open";
CM_ SG_ 1009 RCM2_a403_sideAccelBPilRCrssCoup "RCM2 ECU: a403 side accel b pil r crss coup";
CM_ SG_ 1009 RCM2_a404_sideAccelBPilRCommErr "RCM2 ECU: a404 side accel b pil r comm err";
CM_ SG_ 1009 RCM2_a405_sideAccelBPilRInitTyp "RCM2 ECU: a405 side accel b pil r init typ";
CM_ SG_ 1009 RCM2_a406_sideAccelBPilRConfig "RCM2 ECU: a406 side accel b pil r config";
CM_ SG_ 1009 RCM2_a407_sideAccelBPilRDefect "RCM2 ECU: a407 side accel b pil r defect";
CM_ SG_ 1009 RCM2_a408_sideAccelBPilRSigMon "RCM2 ECU: a408 side accel b pil r sig mon";
CM_ SG_ 1009 RCM2_a410_sideAccelCPilLSht2Gnd "RCM2 ECU: a410 side accel c pil l sht2 gnd";
CM_ SG_ 1009 RCM2_a411_sideAccelCPilLSht2Bat "RCM2 ECU: a411 side accel c pil l sht2 bat";
CM_ SG_ 1009 RCM2_a412_sideAccelCPilLOpen "RCM2 ECU: a412 side accel c pil l open";
CM_ SG_ 1009 RCM2_a413_sideAccelCPilLCrssCoup "RCM2 ECU: a413 side accel c pil l crss coup";
CM_ SG_ 1009 RCM2_a414_sideAccelCPilLCommErr "RCM2 ECU: a414 side accel c pil l comm err";
CM_ SG_ 1009 RCM2_a415_sideAccelCPilLInitTyp "RCM2 ECU: a415 side accel c pil l init typ";
CM_ SG_ 1009 RCM2_a416_sideAccelCPilLConfig "RCM2 ECU: a416 side accel c pil l config";
CM_ SG_ 1009 RCM2_a417_sideAccelCPilLDefect "RCM2 ECU: a417 side accel c pil l defect";
CM_ SG_ 1009 RCM2_a418_sideAccelCPilLSigMon "RCM2 ECU: a418 side accel c pil l sig mon";
CM_ SG_ 1009 RCM2_a420_sideAccelCPilRSht2Gnd "RCM2 ECU: a420 side accel c pil r sht2 gnd";
CM_ SG_ 1009 RCM2_a421_sideAccelCPilRSht2Bat "RCM2 ECU: a421 side accel c pil r sht2 bat";
CM_ SG_ 1009 RCM2_a422_sideAccelCPilROpen "RCM2 ECU: a422 side accel c pil r open";
CM_ SG_ 1009 RCM2_a423_sideAccelCPilRCrssCoup "RCM2 ECU: a423 side accel c pil r crss coup";
CM_ SG_ 1009 RCM2_a424_sideAccelCPilRCommErr "RCM2 ECU: a424 side accel c pil r comm err";
CM_ SG_ 1009 RCM2_a425_sideAccelCPilRInitTyp "RCM2 ECU: a425 side accel c pil r init typ";
CM_ SG_ 1009 RCM2_a426_sideAccelCPilRConfig "RCM2 ECU: a426 side accel c pil r config";
CM_ SG_ 1009 RCM2_a427_sideAccelCPilRDefect "RCM2 ECU: a427 side accel c pil r defect";
CM_ SG_ 1009 RCM2_a428_sideAccelCPilRSigMon "RCM2 ECU: a428 side accel c pil r sig mon";
CM_ SG_ 1009 RCM2_a430_presFrntLDoorSht2Gnd "RCM2 ECU: a430 pres frnt l door sht2 gnd";
CM_ SG_ 1009 RCM2_a431_presFrntLDoorSht2Bat "RCM2 ECU: a431 pres frnt l door sht2 bat";
CM_ SG_ 1009 RCM2_a432_presFrntLDoorOpen "RCM2 ECU: a432 pres frnt l door open";
CM_ SG_ 1009 RCM2_a433_presFrntLDoorCrssCoup "RCM2 ECU: a433 pres frnt l door crss coup";
CM_ SG_ 1009 RCM2_a434_presFrntLDoorCommErr "RCM2 ECU: a434 pres frnt l door comm err";
CM_ SG_ 1009 RCM2_a435_presFrntLDoorInitTyp "RCM2 ECU: a435 pres frnt l door init typ";
CM_ SG_ 1009 RCM2_a436_presFrntLDoorConfig "RCM2 ECU: a436 pres frnt l door config";
CM_ SG_ 1009 RCM2_a437_presFrntLDoorDefect "RCM2 ECU: a437 pres frnt l door defect";
CM_ SG_ 1009 RCM2_a438_presFrntLDoorSigMon "RCM2 ECU: a438 pres frnt l door sig mon";
CM_ SG_ 1009 RCM2_a439_presDoorAbsolute1 "RCM2 ECU: a439 pres door absolute1";
CM_ SG_ 1009 RCM2_a440_presFrntRDoorSht2Gnd "RCM2 ECU: a440 pres frnt r door sht2 gnd";
CM_ SG_ 1009 RCM2_a441_presFrntRDoorSht2Bat "RCM2 ECU: a441 pres frnt r door sht2 bat";
CM_ SG_ 1009 RCM2_a442_presFrntRDoorOpen "RCM2 ECU: a442 pres frnt r door open";
CM_ SG_ 1009 RCM2_a443_presFrntRDoorCrssCoup "RCM2 ECU: a443 pres frnt r door crss coup";
CM_ SG_ 1009 RCM2_a444_presFrntRDoorCommErr "RCM2 ECU: a444 pres frnt r door comm err";
CM_ SG_ 1009 RCM2_a445_presFrntRDoorInitTyp "RCM2 ECU: a445 pres frnt r door init typ";
CM_ SG_ 1009 RCM2_a446_presFrntRDoorConfig "RCM2 ECU: a446 pres frnt r door config";
CM_ SG_ 1009 RCM2_a447_presFrntRDoorDefect "RCM2 ECU: a447 pres frnt r door defect";
CM_ SG_ 1009 RCM2_a448_presFrntRDoorSigMon "RCM2 ECU: a448 pres frnt r door sig mon";
CM_ SG_ 1009 RCM2_a449_presDoorAbsolute2 "RCM2 ECU: a449 pres door absolute2";
CM_ SG_ 1009 RCM2_a450_presPedProLSht2Gnd "RCM2 ECU: a450 pres ped pro l sht2 gnd";
CM_ SG_ 1009 RCM2_a451_presPedProLSht2Bat "RCM2 ECU: a451 pres ped pro l sht2 bat";
CM_ SG_ 1009 RCM2_a452_presPedProLOpen "RCM2 ECU: a452 pres ped pro l open";
CM_ SG_ 1009 RCM2_a453_presPedProLCrssCoup "RCM2 ECU: a453 pres ped pro l crss coup";
CM_ SG_ 1009 RCM2_a454_presPedProLCommErr "RCM2 ECU: a454 pres ped pro l comm err";
CM_ SG_ 1009 RCM2_a455_presPedProLInitTyp "RCM2 ECU: a455 pres ped pro l init typ";
CM_ SG_ 1009 RCM2_a456_presPedProLConfig "RCM2 ECU: a456 pres ped pro l config";
CM_ SG_ 1009 RCM2_a457_presPedProLDefect "RCM2 ECU: a457 pres ped pro l defect";
CM_ SG_ 1009 RCM2_a458_presPedProLSigMon "RCM2 ECU: a458 pres ped pro l sig mon";
CM_ SG_ 1009 RCM2_a460_presPedProRSht2Gnd "RCM2 ECU: a460 pres ped pro r sht2 gnd";
CM_ SG_ 1009 RCM2_a461_presPedProRSht2Bat "RCM2 ECU: a461 pres ped pro r sht2 bat";
CM_ SG_ 1009 RCM2_a462_presPedProROpen "RCM2 ECU: a462 pres ped pro r open";
CM_ SG_ 1009 RCM2_a463_presPedProRCrssCoup "RCM2 ECU: a463 pres ped pro r crss coup";
CM_ SG_ 1009 RCM2_a464_presPedProRCommErr "RCM2 ECU: a464 pres ped pro r comm err";
CM_ SG_ 1009 RCM2_a465_presPedProRInitTyp "RCM2 ECU: a465 pres ped pro r init typ";
CM_ SG_ 1009 RCM2_a466_presPedProRConfig "RCM2 ECU: a466 pres ped pro r config";
CM_ SG_ 1009 RCM2_a467_presPedProRDefect "RCM2 ECU: a467 pres ped pro r defect";
CM_ SG_ 1009 RCM2_a468_presPedProRSigMon "RCM2 ECU: a468 pres ped pro r sig mon";
CM_ SG_ 1009 RCM2_a469_presPedProAbsolute "RCM2 ECU: a469 pres ped pro absolute";
CM_ SG_ 1009 RCM2_a470_upFrntPedProLSht2Gnd "RCM2 ECU: a470 up frnt ped pro l sht2 gnd";
CM_ SG_ 1009 RCM2_a471_upFrntPedProLSht2Bat "RCM2 ECU: a471 up frnt ped pro l sht2 bat";
CM_ SG_ 1009 RCM2_a472_upFrntPedProLOpen "RCM2 ECU: a472 up frnt ped pro l open";
CM_ SG_ 1009 RCM2_a473_upFrntPedProLCrssCoup "RCM2 ECU: a473 up frnt ped pro l crss coup";
CM_ SG_ 1009 RCM2_a474_upFrntPedProLCommErr "RCM2 ECU: a474 up frnt ped pro l comm err";
CM_ SG_ 1009 RCM2_a475_upFrntPedProLIntTyp "RCM2 ECU: a475 up frnt ped pro l int typ";
CM_ SG_ 1009 RCM2_a476_upFrntPedProLConfig "RCM2 ECU: a476 up frnt ped pro l config";
CM_ SG_ 1009 RCM2_a477_upFrntPedProLDefect "RCM2 ECU: a477 up frnt ped pro l defect";
CM_ SG_ 1009 RCM2_a478_upFrntPedProLSigMon "RCM2 ECU: a478 up frnt ped pro l sig mon";
CM_ SG_ 1009 RCM2_a480_upFrntPedProRSht2Gnd "RCM2 ECU: a480 up frnt ped pro r sht2 gnd";
CM_ SG_ 1009 RCM2_a481_upFrntPedProRSht2Bat "RCM2 ECU: a481 up frnt ped pro r sht2 bat";
CM_ SG_ 1009 RCM2_a482_upFrntPedProROpen "RCM2 ECU: a482 up frnt ped pro r open";
CM_ SG_ 1009 RCM2_a483_upFrntPedProRCrssCoup "RCM2 ECU: a483 up frnt ped pro r crss coup";
CM_ SG_ 1009 RCM2_a484_upFrntPedProRCommErr "RCM2 ECU: a484 up frnt ped pro r comm err";
CM_ SG_ 1009 RCM2_a485_upFrntPedProRIntTyp "RCM2 ECU: a485 up frnt ped pro r int typ";
CM_ SG_ 1009 RCM2_a486_upFrntPedProRConfig "RCM2 ECU: a486 up frnt ped pro r config";
CM_ SG_ 1009 RCM2_a487_upFrntPedProRDefect "RCM2 ECU: a487 up frnt ped pro r defect";
CM_ SG_ 1009 RCM2_a488_upFrntPedProRSigMon "RCM2 ECU: a488 up frnt ped pro r sig mon";
CM_ SG_ 1009 RCM2_a490_presRearLDoorSht2Gnd "RCM2 ECU: a490 pres rear l door sht2 gnd";
CM_ SG_ 1009 RCM2_a491_presRearLDoorSht2Bat "RCM2 ECU: a491 pres rear l door sht2 bat";
CM_ SG_ 1009 RCM2_a492_presRearLDoorOpen "RCM2 ECU: a492 pres rear l door open";
CM_ SG_ 1009 RCM2_a493_presRearLDoorCrssCoup "RCM2 ECU: a493 pres rear l door crss coup";
CM_ SG_ 1009 RCM2_a494_presRearLDoorCommErr "RCM2 ECU: a494 pres rear l door comm err";
CM_ SG_ 1009 RCM2_a495_presRearLDoorInitTyp "RCM2 ECU: a495 pres rear l door init typ";
CM_ SG_ 1009 RCM2_a496_presRearLDoorConfig "RCM2 ECU: a496 pres rear l door config";
CM_ SG_ 1009 RCM2_a497_presRearLDoorDefect "RCM2 ECU: a497 pres rear l door defect";
CM_ SG_ 1009 RCM2_a498_presRearLDoorSigMon "RCM2 ECU: a498 pres rear l door sig mon";
CM_ SG_ 1009 RCM2_a500_presRearRDoorSht2Gnd "RCM2 ECU: a500 pres rear r door sht2 gnd";
CM_ SG_ 1009 RCM2_a501_presRearRDoorSht2Bat "RCM2 ECU: a501 pres rear r door sht2 bat";
CM_ SG_ 1009 RCM2_a502_presRearRDoorOpen "RCM2 ECU: a502 pres rear r door open";
CM_ SG_ 1009 RCM2_a503_presRearRDoorCrssCoup "RCM2 ECU: a503 pres rear r door crss coup";
CM_ SG_ 1009 RCM2_a504_presRearRDoorCommErr "RCM2 ECU: a504 pres rear r door comm err";
CM_ SG_ 1009 RCM2_a505_presRearRDoorInitTyp "RCM2 ECU: a505 pres rear r door init typ";
CM_ SG_ 1009 RCM2_a506_presRearRDoorConfig "RCM2 ECU: a506 pres rear r door config";
CM_ SG_ 1009 RCM2_a507_presRearRDoorDefect "RCM2 ECU: a507 pres rear r door defect";
CM_ SG_ 1009 RCM2_a508_presRearRDoorSigMon "RCM2 ECU: a508 pres rear r door sig mon";
CM_ SG_ 1009 RCM2_a509_sideAccelDPilLSht2Gnd "RCM2 ECU: a509 side accel d pil l sht2 gnd";
CM_ SG_ 1009 RCM2_a510_sideAccelDPilLSht2Bat "RCM2 ECU: a510 side accel d pil l sht2 bat";
CM_ SG_ 1009 RCM2_a511_sideAccelDPilLOpen "RCM2 ECU: a511 side accel d pil l open";
CM_ SG_ 1009 RCM2_a512_sideAccelDPilLCrssCoup "RCM2 ECU: a512 side accel d pil l crss coup";
CM_ SG_ 1009 RCM2_a513_sideAccelDPilLCommErr "RCM2 ECU: a513 side accel d pil l comm err";
CM_ SG_ 1009 RCM2_a514_sideAccelDPilLInitTyp "RCM2 ECU: a514 side accel d pil l init typ";
CM_ SG_ 1009 RCM2_a515_sideAccelDPilLConfig "RCM2 ECU: a515 side accel d pil l config";
CM_ SG_ 1009 RCM2_a516_sideAccelDPilLDefect "RCM2 ECU: a516 side accel d pil l defect";
CM_ SG_ 1009 RCM2_a517_sideAccelDPilLSigMon "RCM2 ECU: a517 side accel d pil l sig mon";
CM_ SG_ 1009 RCM2_a518_sideAccelDPilRSht2Gnd "RCM2 ECU: a518 side accel d pil r sht2 gnd";
CM_ SG_ 1009 RCM2_a519_sideAccelDPilRSht2Bat "RCM2 ECU: a519 side accel d pil r sht2 bat";
CM_ SG_ 1009 RCM2_a520_sideAccelDPilROpen "RCM2 ECU: a520 side accel d pil r open";
CM_ SG_ 1009 RCM2_a521_sideAccelDPilRCrssCoup "RCM2 ECU: a521 side accel d pil r crss coup";
CM_ SG_ 1009 RCM2_a522_sideAccelDPilRCommErr "RCM2 ECU: a522 side accel d pil r comm err";
CM_ SG_ 1009 RCM2_a523_sideAccelDPilRInitTyp "RCM2 ECU: a523 side accel d pil r init typ";
CM_ SG_ 1009 RCM2_a524_sideAccelDPilRConfig "RCM2 ECU: a524 side accel d pil r config";
CM_ SG_ 1009 RCM2_a525_sideAccelDPilRDefect "RCM2 ECU: a525 side accel d pil r defect";
CM_ SG_ 1009 RCM2_a526_sideAccelDPilRSigMon "RCM2 ECU: a526 side accel d pil r sig mon";
CM_ SG_ 1009 RCM2_a527_upFrntSnsrCSht2Gnd "RCM2 ECU: a527 up frnt snsr c sht2 gnd";
CM_ SG_ 1009 RCM2_a528_upFrntSnsrCSht2Bat "RCM2 ECU: a528 up frnt snsr c sht2 bat";
CM_ SG_ 1009 RCM2_a529_upFrntSnsrCOpen "RCM2 ECU: a529 up frnt snsr c open";
CM_ SG_ 1009 RCM2_a530_upFrntSnsrCCrssCoup "RCM2 ECU: a530 up frnt snsr c crss coup";
CM_ SG_ 1009 RCM2_a531_upFrntSnsrCCommErr "RCM2 ECU: a531 up frnt snsr c comm err";
CM_ SG_ 1009 RCM2_a532_upFrntSnsrCInitTyp "RCM2 ECU: a532 up frnt snsr c init typ";
CM_ SG_ 1009 RCM2_a533_upFrntSnsrCConfig "RCM2 ECU: a533 up frnt snsr c config";
CM_ SG_ 1009 RCM2_a534_upFrntSnsrCDefect "RCM2 ECU: a534 up frnt snsr c defect";
CM_ SG_ 1009 RCM2_a535_upFrntSnsrCSigMon "RCM2 ECU: a535 up frnt snsr c sig mon";
CM_ SG_ 1009 RCM2_a550_bucklHallLeftSht2Gnd "RCM2 ECU: a550 buckl hall left sht2 gnd";
CM_ SG_ 1009 RCM2_a551_bucklHallLeftSht2Bat "RCM2 ECU: a551 buckl hall left sht2 bat";
CM_ SG_ 1009 RCM2_a552_bucklHallLeftOpen "RCM2 ECU: a552 buckl hall left open";
CM_ SG_ 1009 RCM2_a553_bucklHallLeftUndef "RCM2 ECU: a553 buckl hall left undef";
CM_ SG_ 1009 RCM2_a554_bucklHallLeftCrssCoup "RCM2 ECU: a554 buckl hall left crss coup";
CM_ SG_ 1009 RCM2_a555_bucklHallLeftConfig "RCM2 ECU: a555 buckl hall left config";
CM_ SG_ 1009 RCM2_a556_bucklHallRightSht2Gnd "RCM2 ECU: a556 buckl hall right sht2 gnd";
CM_ SG_ 1009 RCM2_a557_bucklHallRightSht2Bat "RCM2 ECU: a557 buckl hall right sht2 bat";
CM_ SG_ 1009 RCM2_a558_bucklHallRightOpen "RCM2 ECU: a558 buckl hall right open";
CM_ SG_ 1009 RCM2_a559_bucklHallRightUndef "RCM2 ECU: a559 buckl hall right undef";
CM_ SG_ 1009 RCM2_a560_bucklHallRightCrssCoup "RCM2 ECU: a560 buckl hall right crss coup";
CM_ SG_ 1009 RCM2_a561_bucklHallRightConfig "RCM2 ECU: a561 buckl hall right config";
CM_ SG_ 1009 RCM2_a562_seaTrkPosLeftSht2Gnd "RCM2 ECU: a562 sea trk pos left sht2 gnd";
CM_ SG_ 1009 RCM2_a563_seaTrkPosLeftShtBat "RCM2 ECU: a563 sea trk pos left sht bat";
CM_ SG_ 1009 RCM2_a564_seaTrkPosLeftOpen "RCM2 ECU: a564 sea trk pos left open";
CM_ SG_ 1009 RCM2_a565_seaTrkPosLeftUndefined "RCM2 ECU: a565 sea trk pos left undefined";
CM_ SG_ 1009 RCM2_a566_seaTrkPosLeftCrssCoup "RCM2 ECU: a566 sea trk pos left crss coup";
CM_ SG_ 1009 RCM2_a567_seaTrkPosLeftConfig "RCM2 ECU: a567 sea trk pos left config";
CM_ SG_ 1009 RCM2_a568_occPROSSht2Gnd "RCM2 ECU: a568 occ PROS sht2 gnd";
CM_ SG_ 1009 RCM2_a569_occPROSSht2Bat "RCM2 ECU: a569 occ PROS sht2 bat";
CM_ SG_ 1009 RCM2_a570_occPROSOpen "RCM2 ECU: a570 occ PROS open";
CM_ SG_ 1009 RCM2_a571_occPROSUndef "RCM2 ECU: a571 occ PROS undef";
CM_ SG_ 1009 RCM2_a572_occPROSCrssCoup "RCM2 ECU: a572 occ PROS crss coup";
CM_ SG_ 1009 RCM2_a573_occPROSConfig "RCM2 ECU: a573 occ PROS config";
CM_ SG_ 1009 RCM2_a587_sbrRearNetworkSht2Gnd "RCM2 ECU: a587 sbr rear network sht2 gnd";
CM_ SG_ 1009 RCM2_a588_sbrRearNetworkSht2Bat "RCM2 ECU: a588 sbr rear network sht2 bat";
CM_ SG_ 1009 RCM2_a589_sbrRearNetworkOpen "RCM2 ECU: a589 sbr rear network open";
CM_ SG_ 1009 RCM2_a590_sbrRearNetworkUndefine "RCM2 ECU: a590 sbr rear network undefined";
CM_ SG_ 1009 RCM2_a591_sbrRearNetworkCrssCoup "RCM2 ECU: a591 sbr rear network crss coup";
CM_ SG_ 1009 RCM2_a592_sbrRearNetworkConfig "RCM2 ECU: a592 sbr rear network config";
CM_ SG_ 1009 RCM2_a593_driveOrientationSht2Gn "RCM2 ECU: a593 drive orientation sht2 gnd";
CM_ SG_ 1009 RCM2_a594_driveOrientationSht2Ba "RCM2 ECU: a594 drive orientation sht2 bat";
CM_ SG_ 1009 RCM2_a595_driveOrientationOpen "RCM2 ECU: a595 drive orientation open";
CM_ SG_ 1009 RCM2_a596_driveOrientationUndefi "RCM2 ECU: a596 drive orientation undefined";
CM_ SG_ 1009 RCM2_a597_driveOrientationCrssCo "RCM2 ECU: a597 drive orientation crss coup";
CM_ SG_ 1009 RCM2_a598_driveOrientationConfig "RCM2 ECU: a598 drive orientation config";
CM_ SG_ 1009 RCM2_a600_comCANinternalTimeout "RCM2 ECU: a600 com CA ninternal timeout";
CM_ SG_ 1009 RCM2_a601_comChassisCANSilent "RCM2 ECU: a601 com chassis CAN silent";
CM_ SG_ 1009 RCM2_a602_comChassisCANBusOff "RCM2 ECU: a602 com chassis CAN bus off";
CM_ SG_ 1009 RCM2_a603_comPARTYCANSilent "RCM2 ECU: a603 com PARTYCAN silent";
CM_ SG_ 1009 RCM2_a604_comPARTYCANBusOff "RCM2 ECU: a604 com PARTYCAN bus off";
CM_ SG_ 1009 RCM2_a605_comStwAngStatMIA "RCM2 ECU: a605 com stw ang stat MIA";
CM_ SG_ 1009 RCM2_a606_comStwAngStatChkSm "RCM2 ECU: a606 com stw ang stat chk sm";
CM_ SG_ 1009 RCM2_a607_comStwAngStatCntr "RCM2 ECU: a607 com stw ang stat cntr";
CM_ SG_ 1009 RCM2_a608_comDItorque1MIA "RCM2 ECU: a608 com d itorque1 MIA";
CM_ SG_ 1009 RCM2_a609_comDItorque1ChkSm "RCM2 ECU: a609 com d itorque1 chk sm";
CM_ SG_ 1009 RCM2_a610_comDItorque1Cntr "RCM2 ECU: a610 com d itorque1 cntr";
CM_ SG_ 1009 RCM2_a611_comDItorque2MIA "RCM2 ECU: a611 com d itorque2 MIA";
CM_ SG_ 1009 RCM2_a612_comDItorque2ChkSm "RCM2 ECU: a612 com d itorque2 chk sm";
CM_ SG_ 1009 RCM2_a613_comDItorque2Cntr "RCM2 ECU: a613 com d itorque2 cntr";
CM_ SG_ 1009 RCM2_a614_comESP135MIA "RCM2 ECU: a614 com ESP135 MIA";
CM_ SG_ 1009 RCM2_a615_comESP135ChkSm "RCM2 ECU: a615 com ESP135 chk sm";
CM_ SG_ 1009 RCM2_a616_comESP135Cntr "RCM2 ECU: a616 com ESP135 cntr";
CM_ SG_ 1009 RCM2_a617_comESP145MIA "RCM2 ECU: a617 com ESP145 MIA";
CM_ SG_ 1009 RCM2_a618_comESP145ChkSm "RCM2 ECU: a618 com ESP145 chk sm";
CM_ SG_ 1009 RCM2_a619_comESP145Cntr "RCM2 ECU: a619 com ESP145 cntr";
CM_ SG_ 1009 RCM2_a620_comInvalidVehicleSpeed "RCM2 ECU: a620 com invalid vehicle speed";
CM_ SG_ 1009 RCM2_a621_comESPBMIA "RCM2 ECU: a621 com ESPBMIA";
CM_ SG_ 1009 RCM2_a622_comESPBChkSm "RCM2 ECU: a622 com ESPB chk sm";
CM_ SG_ 1009 RCM2_a623_comESPBCntr "RCM2 ECU: a623 com ESPB cntr";
CM_ SG_ 1009 RCM2_a624_comESPCMIA "RCM2 ECU: a624 com ESPCMIA";
CM_ SG_ 1009 RCM2_a625_comESPCChkSm "RCM2 ECU: a625 com ESPC chk sm";
CM_ SG_ 1009 RCM2_a626_comESPCCntr "RCM2 ECU: a626 com ESPC cntr";
CM_ SG_ 1009 RCM2_a627_comEPBStatusMIA "RCM2 ECU: a627 com EPB status MIA";
CM_ SG_ 1009 RCM2_a628_comEPBStatusChkSm "RCM2 ECU: a628 com EPB status chk sm";
CM_ SG_ 1009 RCM2_a629_comEPBStatusCntr "RCM2 ECU: a629 com EPB status cntr";
CM_ SG_ 1009 RCM2_a630_comGTWACSMIA "RCM2 ECU: a630 com GTWACSMIA";
CM_ SG_ 1009 RCM2_a631_comGTWACSChkSm "RCM2 ECU: a631 com GTWACS chk sm";
CM_ SG_ 1009 RCM2_a632_comGTWACSCntr "RCM2 ECU: a632 com GTWACS cntr";
CM_ SG_ 1009 RCM2_a633_comOCS1PMIA "RCM2 ECU: a633 com OCS1 PMIA";
CM_ SG_ 1009 RCM2_a634_comOCS1PChkSm "RCM2 ECU: a634 com OCS1 p chk sm";
CM_ SG_ 1009 RCM2_a635_comOCS1PCntr "RCM2 ECU: a635 com OCS1 p cntr";
CM_ SG_ 1009 RCM2_a636_ocsFaulted "RCM2 ECU: a636 ocs faulted";
CM_ SG_ 1009 RCM2_a637_ocsUnknown "RCM2 ECU: a637 ocs unknown";
CM_ SG_ 1009 RCM2_a638_comGTWodoMIA "RCM2 ECU: a638 com GT wodo MIA";
CM_ SG_ 1009 RCM2_a639_comGTWCarStateMIA "RCM2 ECU: a639 com GTW car state MIA";
CM_ SG_ 1009 RCM2_a640_comTPMSStatusCMIA "RCM2 ECU: a640 com TPMS status CMIA";
CM_ SG_ 1009 RCM2_a641_comGTWCarConfigMIA "RCM2 ECU: a641 com GTW car config MIA";
CM_ SG_ 1009 RCM2_a642_comVINmessageMIA "RCM2 ECU: a642 com VI nmessage MIA";
CM_ SG_ 1009 RCM2_a643_comDASSafetyFrntMIA "RCM2 ECU: a643 com DAS safety frnt MIA";
CM_ SG_ 1009 RCM2_a644_comDASSafetyFrntChkSm "RCM2 ECU: a644 com DAS safety frnt chk sm";
CM_ SG_ 1009 RCM2_a645_comDASSafetyFrntCntr "RCM2 ECU: a645 com DAS safety frnt cntr";
CM_ SG_ 1009 RCM2_a646_comDIstateMIA "RCM2 ECU: a646 com d istate MIA";
CM_ SG_ 1009 RCM2_a647_comDIstateChkSm "RCM2 ECU: a647 com d istate chk sm";
CM_ SG_ 1009 RCM2_a648_comDIstateCntr "RCM2 ECU: a648 com d istate cntr";
CM_ SG_ 1009 RCM2_a649_comDIstate2MIA "RCM2 ECU: a649 com d istate2 MIA";
CM_ SG_ 1009 RCM2_a650_comDIstate2ChkSm "RCM2 ECU: a650 com d istate2 chk sm";
CM_ SG_ 1009 RCM2_a651_comDIstate2Cntr "RCM2 ECU: a651 com d istate2 cntr";
CM_ SG_ 1009 RCM2_a652_ambientTempFaulted "RCM2 ECU: a652 ambient temp faulted";
CM_ SG_ 1009 RCM2_a653_comGTWESP1MIA "RCM2 ECU: a653 com GTWESP1 MIA";
CM_ SG_ 1009 RCM2_a654_comGTWESP1ChkSm "RCM2 ECU: a654 com GTWESP1 chk sm";
CM_ SG_ 1009 RCM2_a655_comGTWESP1Cntr "RCM2 ECU: a655 com GTWESP1 cntr";
CM_ SG_ 1009 RCM2_a656_comVCSEATPrestMIA "RCM2 ECU: a656 com VCSEAT prest MIA";
CM_ SG_ 1009 RCM2_a657_comVCSEATPrestChkSm "RCM2 ECU: a657 com VCSEAT prest chk sm";
CM_ SG_ 1009 RCM2_a658_comVCSEATPrestCntr "RCM2 ECU: a658 com VCSEAT prest cntr";
CM_ SG_ 1009 RCM2_a659_comVCSEATPbuckle "RCM2 ECU: a659 com VCSEAT pbuckle";
CM_ SG_ 1009 RCM2_a660_comVCSEATPOccpy "RCM2 ECU: a660 com VCSEATP occpy";
CM_ SG_ 1009 RCM2_a661_comVCSEATPocs "RCM2 ECU: a661 com VCSEAT pocs";
CM_ SG_ 1009 RCM2_a662_comVCSEATPstps "RCM2 ECU: a662 com VCSEAT pstps";
CM_ SG_ 1009 RCM2_a663_comVCSEATDrestMIA "RCM2 ECU: a663 com VCSEAT drest MIA";
CM_ SG_ 1009 RCM2_a664_comVCSEATDrestChkSm "RCM2 ECU: a664 com VCSEAT drest chk sm";
CM_ SG_ 1009 RCM2_a665_comVCSEATDrestCntr "RCM2 ECU: a665 com VCSEAT drest cntr";
CM_ SG_ 1009 RCM2_a666_comVCSEATDbuckle "RCM2 ECU: a666 com VCSEAT dbuckle";
CM_ SG_ 1009 RCM2_a667_comVCSEATDOccpy "RCM2 ECU: a667 com VCSEATD occpy";
CM_ SG_ 1009 RCM2_a668_comVCSEATDstps "RCM2 ECU: a668 com VCSEAT dstps";
CM_ SG_ 1009 RCM2_a669_comEPBLstatusMIA "RCM2 ECU: a669 com EPB lstatus MIA";
CM_ SG_ 1009 RCM2_a670_comEPBLstatusChkSm "RCM2 ECU: a670 com EPB lstatus chk sm";
CM_ SG_ 1009 RCM2_a671_comEPBLstatusCntr "RCM2 ECU: a671 com EPB lstatus cntr";
CM_ SG_ 1009 RCM2_a672_comEPBRstatusMIA "RCM2 ECU: a672 com EPB rstatus MIA";
CM_ SG_ 1009 RCM2_a673_comEPBRstatusChkSm "RCM2 ECU: a673 com EPB rstatus chk sm";
CM_ SG_ 1009 RCM2_a674_comEPBRstatusCntr "RCM2 ECU: a674 com EPB rstatus cntr";
CM_ SG_ 1009 RCM2_a675_comUIodoMIA "RCM2 ECU: a675 com u iodo MIA";
CM_ SG_ 1009 RCM2_a676_comEPAS3PsysMIA "RCM2 ECU: a676 com EPAS3 psys MIA";
CM_ SG_ 1009 RCM2_a677_comEPAS3PsysChkSm "RCM2 ECU: a677 com EPAS3 psys chk sm";
CM_ SG_ 1009 RCM2_a678_comEPAS3PsysCntr "RCM2 ECU: a678 com EPAS3 psys cntr";
CM_ SG_ 1009 RCM2_a679_comESPwheelSpeedsMIA "RCM2 ECU: a679 com ES pwheel speeds MIA";
CM_ SG_ 1009 RCM2_a680_comESPwheelSpeedsChkSm "RCM2 ECU: a680 com ES pwheel speeds chk sm";
CM_ SG_ 1009 RCM2_a681_comESPwheelSpeedsCntr "RCM2 ECU: a681 com ES pwheel speeds cntr";
CM_ SG_ 1009 RCM2_a682_comDIspeedMIA "RCM2 ECU: a682 com d ispeed MIA";
CM_ SG_ 1009 RCM2_a683_comDIspeedChkSm "RCM2 ECU: a683 com d ispeed chk sm";
CM_ SG_ 1009 RCM2_a684_comDIspeedCntr "RCM2 ECU: a684 com d ispeed cntr";
CM_ SG_ 1009 RCM2_a685_comDIchassControlMIA "RCM2 ECU: a685 com d ichass control MIA";
CM_ SG_ 1009 RCM2_a686_comDIchassControlChkSm "RCM2 ECU: a686 com d ichass control chk sm";
CM_ SG_ 1009 RCM2_a687_comDIchassControlCntr "RCM2 ECU: a687 com d ichass control cntr";
CM_ SG_ 1009 RCM2_a688_comVCLEFTrestMIA "RCM2 ECU: a688 com VCLEF trest MIA";
CM_ SG_ 1009 RCM2_a689_comVCLEFTrestChkSm "RCM2 ECU: a689 com VCLEF trest chk sm";
CM_ SG_ 1009 RCM2_a690_comVCLEFTrestCntr "RCM2 ECU: a690 com VCLEF trest cntr";
CM_ SG_ 1009 RCM2_a691_comVCLEFT1rLBuckle "RCM2 ECU: a691 com vcleft1r l buckle";
CM_ SG_ 1009 RCM2_a692_comVCLEFT2rLBuckle "RCM2 ECU: a692 com vcleft2r l buckle";
CM_ SG_ 1009 RCM2_a693_comVCLEFT1rLSTPS "RCM2 ECU: a693 com vcleft1r LSTPS";
CM_ SG_ 1009 RCM2_a694_comVCRIGHTrestMIA "RCM2 ECU: a694 com VCRIGH trest MIA";
CM_ SG_ 1009 RCM2_a695_comVCRIGHTrestChkSm "RCM2 ECU: a695 com VCRIGH trest chk sm";
CM_ SG_ 1009 RCM2_a696_comVCRIGHTrestCntr "RCM2 ECU: a696 com VCRIGH trest cntr";
CM_ SG_ 1009 RCM2_a697_comVCRIGHT1rRBuckle "RCM2 ECU: a697 com vcright1r r buckle";
CM_ SG_ 1009 RCM2_a698_comVCRIGHT2rRBuckle "RCM2 ECU: a698 com vcright2r r buckle";
CM_ SG_ 1009 RCM2_a699_comVCRIGHTocs "RCM2 ECU: a699 com VCRIGH tocs";
CM_ SG_ 1009 RCM2_a700_comVCRIGHT1rRSTPS "RCM2 ECU: a700 com vcright1r RSTPS";
CM_ SG_ 1009 RCM2_a701_comVCSECtpmsStatusMIA "RCM2 ECU: a701 com VCSE ctpms status MIA";
CM_ SG_ 1009 RCM2_a750_linInternalTimeout "RCM2 ECU: a750 lin internal timeout";
CM_ SG_ 1009 RCM2_a799_internalFault "RCM2 ECU: a799 internal fault";
CM_ SG_ 1009 RCM2_a800_crcFault "RCM2 ECU: a800 crc fault";
CM_ SG_ 1009 RCM2_a801_parameterLayoutID "RCM2 ECU: a801 parameter layout ID";
CM_ SG_ 1009 RCM2_a802_parameterTransferID "RCM2 ECU: a802 parameter transfer ID";
CM_ SG_ 1009 RCM2_a803_algoVerifySensorID "RCM2 ECU: a803 algo verify sensor ID";
CM_ SG_ 1009 RCM2_a804_configDataInconsistent "RCM2 ECU: a804 config data inconsistent";
CM_ SG_ 1009 RCM2_a805_swVersionWrong "RCM2 ECU: a805 sw version wrong";
CM_ SG_ 1009 RCM2_a806_configVINnotLearned "RCM2 ECU: a806 config VI nnot learned";
CM_ SG_ 1009 RCM2_a807_configVINmismatch "RCM2 ECU: a807 config VI nmismatch";
CM_ SG_ 1009 RCM2_a808_configDriveNotLearned "RCM2 ECU: a808 config drive not learned";
CM_ SG_ 1009 RCM2_a809_configDriveMismatch "RCM2 ECU: a809 config drive mismatch";
CM_ SG_ 1009 RCM2_a810_bootUpActionFailure "RCM2 ECU: a810 boot up action failure";
CM_ SG_ 1009 RCM2_a811_comAxleSpeed "RCM2 ECU: a811 com axle speed";
CM_ SG_ 1009 RCM2_a812_idfMisuseMonitoringErr "RCM2 ECU: a812 idf misuse monitoring err";
CM_ SG_ 1009 RCM2_a813_idfEnviMonitoringError "RCM2 ECU: a813 idf envi monitoring error";
CM_ SG_ 1009 RCM2_a814_idfEnviMonitoringEvent "RCM2 ECU: a814 idf envi monitoring event";
CM_ SG_ 1009 RCM2_a815_upFrntPedProMLSht2Gnd "RCM2 ECU: a815 up frnt ped pro ML sht2 gnd";
CM_ SG_ 1009 RCM2_a816_upFrntPedProMLSht2Bat "RCM2 ECU: a816 up frnt ped pro ML sht2 bat";
CM_ SG_ 1009 RCM2_a817_upFrntPedProMLOpen "RCM2 ECU: a817 up frnt ped pro ML open";
CM_ SG_ 1009 RCM2_a818_upFrntPedProMLCrssCoup "RCM2 ECU: a818 up frnt ped pro ML crss coup";
CM_ SG_ 1009 RCM2_a819_upFrntPedProMLCommErr "RCM2 ECU: a819 up frnt ped pro ML comm err";
CM_ SG_ 1009 RCM2_a820_upFrntPedProMLIntTyp "RCM2 ECU: a820 up frnt ped pro ML int typ";
CM_ SG_ 1009 RCM2_a821_upFrntPedProMLConfig "RCM2 ECU: a821 up frnt ped pro ML config";
CM_ SG_ 1009 RCM2_a822_upFrntPedProMLDefect "RCM2 ECU: a822 up frnt ped pro ML defect";
CM_ SG_ 1009 RCM2_a823_upFrntPedProMLSigMon "RCM2 ECU: a823 up frnt ped pro ML sig mon";
CM_ SG_ 1009 RCM2_a824_upFrntPedProMRSht2Gnd "RCM2 ECU: a824 up frnt ped pro MR sht2 gnd";
CM_ SG_ 1009 RCM2_a825_upFrntPedProMRSht2Bat "RCM2 ECU: a825 up frnt ped pro MR sht2 bat";
CM_ SG_ 1009 RCM2_a826_upFrntPedProMROpen "RCM2 ECU: a826 up frnt ped pro MR open";
CM_ SG_ 1009 RCM2_a827_upFrntPedProMRCrssCoup "RCM2 ECU: a827 up frnt ped pro MR crss coup";
CM_ SG_ 1009 RCM2_a828_upFrntPedProMRCommErr "RCM2 ECU: a828 up frnt ped pro MR comm err";
CM_ SG_ 1009 RCM2_a829_upFrntPedProMRIntTyp "RCM2 ECU: a829 up frnt ped pro MR int typ";
CM_ SG_ 1009 RCM2_a830_upFrntPedProMRConfig "RCM2 ECU: a830 up frnt ped pro MR config";
CM_ SG_ 1009 RCM2_a831_upFrntPedProMRDefect "RCM2 ECU: a831 up frnt ped pro MR defect";
CM_ SG_ 1009 RCM2_a832_upFrntPedProMRSigMon "RCM2 ECU: a832 up frnt ped pro MR sig mon";
CM_ SG_ 1009 RCM2_a833_pretenShldCSht2Gnd "RCM2 ECU: a833 preten shld c sht2 gnd";
CM_ SG_ 1009 RCM2_a834_pretenShldCSht2Bat "RCM2 ECU: a834 preten shld c sht2 bat";
CM_ SG_ 1009 RCM2_a835_pretenShldCOpen "RCM2 ECU: a835 preten shld c open";
CM_ SG_ 1009 RCM2_a836_pretenShldCShort "RCM2 ECU: a836 preten shld c short";
CM_ SG_ 1009 RCM2_a837_pretenShldCCrossC "RCM2 ECU: a837 preten shld c cross c";
CM_ SG_ 1009 RCM2_a838_pretenShldCConfig "RCM2 ECU: a838 preten shld c config";
CM_ SG_ 1009 RCM2_a839_preten2ndRowCSht2Gnd "RCM2 ECU: a839 preten2nd row c sht2 gnd";
CM_ SG_ 1009 RCM2_a840_preten2ndRowCSht2Bat "RCM2 ECU: a840 preten2nd row c sht2 bat";
CM_ SG_ 1009 RCM2_a841_preten2ndRowCOpen "RCM2 ECU: a841 preten2nd row c open";
CM_ SG_ 1009 RCM2_a842_preten2ndRowCShort "RCM2 ECU: a842 preten2nd row c short";
CM_ SG_ 1009 RCM2_a843_preten2ndRowCCrssCoup "RCM2 ECU: a843 preten2nd row c crss coup";
CM_ SG_ 1009 RCM2_a844_preten2ndRowCConfig "RCM2 ECU: a844 preten2nd row c config";
CM_ SG_ 1009 RCM2_a845_comUIchassisControlMIA "RCM2 ECU: a845 com u ichassis control MIA";
CM_ SG_ 1009 RCM2_a846_comSCCMstrAnglSnsMIA "RCM2 ECU: a846 com SCC mstr angl sns MIA";
CM_ SG_ 1009 RCM2_a847_comDASctrlMIA "RCM2 ECU: a847 com DA sctrl MIA";
CM_ SG_ 1009 RCM2_a848_comDIlocStatMIA "RCM2 ECU: a848 com d iloc stat MIA";
CM_ SG_ 1009 RCM2_a849_comIBSTparty1MIA "RCM2 ECU: a849 com IBS tparty1 MIA";
CM_ SG_ 1009 RCM2_a850_comVCFRONTlightingMIA "RCM2 ECU: a850 com VCFRON tlighting MIA";
CM_ SG_ 1009 RCM2_a851_internalFaultTemp "RCM2 ECU: a851 internal fault temp";
CM_ SG_ 1009 RCM2_a852_autarkyEvent "RCM2 ECU: a852 autarky event";
CM_ SG_ 1009 RCM2_a853_ConfigParametersIncons "RCM2 ECU: a853 config parameters inconsistent";
CM_ SG_ 1009 RCM2_a854_ConfigParametersNotLea "RCM2 ECU: a854 config parameters not learned";
CM_ SG_ 1009 RCM2_a857_comVCLEFT2rCBuckle "RCM2 ECU: a857 com vcleft2r c buckle";
CM_ SG_ 1009 RCM2_a858_comVCxLVPowerStateMIA "RCM2 ECU: a858 com v cx LV power state MIA";
CM_ SG_ 1009 RCM2_a859_comVCxLVPowerStateChkS "RCM2 ECU: a859 com v cx LV power state chk sm";
CM_ SG_ 1009 RCM2_a860_comVCxLVPowerStateCntr "RCM2 ECU: a860 com v cx LV power state cntr";
CM_ SG_ 1009 RCM2_a861_typeApprovalStringNotL "RCM2 ECU: a861 type approval string not learned";
CM_ SG_ 1009 RCM2_a862_comPCSalertMatrixMIA "RCM2 ECU: a862 com PC salert matrix MIA";
CM_ SG_ 1009 RCM2_a863_comVCFRONTalertMatrixM "RCM2 ECU: a863 com VCFRON talert matrix MIA";
CM_ SG_ 1009 RCM2_a864_comGTWepochTimeMIA "RCM2 ECU: a864 com GT wepoch time MIA";
CM_ SG_ 1009 RCM2_a865_comVCLVBMSstatusHighMI "RCM2 ECU: a865 com VCLVBM sstatus high MIA";
CM_ SG_ 1009 RCM2_a866_comDASstatusMIA "RCM2 ECU: a866 com DA sstatus MIA";
CM_ SG_ 1009 RCM2_a867_comPPBepbc1MIA "RCM2 ECU: a867 com PP bepbc1 MIA";
CM_ SG_ 1009 RCM2_a868_headAB3rdRowRSht2Gnd "RCM2 ECU: a868 head ab3rd row r sht2 gnd";
CM_ SG_ 1009 RCM2_a869_headAB3rdRowRSht2Bat "RCM2 ECU: a869 head ab3rd row r sht2 bat";
CM_ SG_ 1009 RCM2_a870_headAB3rdRowROpen "RCM2 ECU: a870 head ab3rd row r open";
CM_ SG_ 1009 RCM2_a871_headAB3rdRowRShort "RCM2 ECU: a871 head ab3rd row r short";
CM_ SG_ 1009 RCM2_a872_headAB3rdRowRCrossC "RCM2 ECU: a872 head ab3rd row r cross c";
CM_ SG_ 1009 RCM2_a873_headAB3rdRowRConfig "RCM2 ECU: a873 head ab3rd row r config";
CM_ SG_ 1009 RCM2_a874_headAB3rdRowLSht2Gnd "RCM2 ECU: a874 head ab3rd row l sht2 gnd";
CM_ SG_ 1009 RCM2_a875_headAB3rdRowLSht2Bat "RCM2 ECU: a875 head ab3rd row l sht2 bat";
CM_ SG_ 1009 RCM2_a876_headAB3rdRowLOpen "RCM2 ECU: a876 head ab3rd row l open";
CM_ SG_ 1009 RCM2_a877_headAB3rdRowLShort "RCM2 ECU: a877 head ab3rd row l short";
CM_ SG_ 1009 RCM2_a878_headAB3rdRowLCrossC "RCM2 ECU: a878 head ab3rd row l cross c";
CM_ SG_ 1009 RCM2_a879_headAB3rdRowLConfig "RCM2 ECU: a879 head ab3rd row l config";
CM_ SG_ 1009 RCM2_a880_comVCLEFT3rLBuckle "RCM2 ECU: a880 com vcleft3r l buckle";
CM_ SG_ 1009 RCM2_a881_comVCRIGHT3rRBuckle "RCM2 ECU: a881 com vcright3r r buckle";
CM_ SG_ 1009 RCM2_a882_comPEBSbrakeSpeedMIA "RCM2 ECU: a882 com PEB sbrake speed MIA";
CM_ SG_ 1009 RCM2_a883_comPEBSstatus2MIA "RCM2 ECU: a883 com PEB sstatus2 MIA";
CM_ SG_ 1009 RCM2_a884_comPEBSstatus3MIA "RCM2 ECU: a884 com PEB sstatus3 MIA";
CM_ SG_ 1009 RCM2_a885_comPEBSstatus2Counter "RCM2 ECU: a885 com PEB sstatus2 counter";
CM_ SG_ 1009 RCM2_a886_comPEBSstatus2CRC "RCM2 ECU: a886 com PEB sstatus2 CRC";
CM_ BO_ 1252 "RCM3 ECU message: alert log; frame length from the layout, not yet observed on a vehicle bus";
CM_ SG_ 1252 RCM3_alertID "RCM3 ECU: alert ID";
CM_ SG_ 1252 RCM3_alertState "RCM3 ECU: alert state";
CM_ BO_ 1010 "RCM3 ECU message: alert matrix; frame length from the layout, not yet observed on a vehicle bus";
CM_ SG_ 1010 RCM3_matrixIndex "RCM3 ECU: matrix index";
CM_ SG_ 1010 RCM3_a001_LVPowerLossDetected "RCM3 ECU: a001 LV power loss detected";
CM_ BO_ 257 "Restraint control module message: inertial1; frame length from the layout, not yet observed on a vehicle bus";
CM_ SG_ 257 RCM_yawRate "Offset compensated yaw rate measured by the airbag ECU. ISO axis convention (Positive during left turn); raw 32768 = signal not available (SNA)";
CM_ SG_ 257 RCM_pitchRate "Offset compensated pitch rate measured by the airbag ECU. ISO axis convention (positive when the nose pitches down); raw 16384 = signal not available (SNA)";
CM_ SG_ 257 RCM_rollRate "Offset compensated roll rate measured by the airbag ECU. ISO axis convention (positive during left turn); raw 16384 = signal not available (SNA)";
CM_ SG_ 257 RCM_rollRateQF "Restraint control module: roll rate QF";
CM_ SG_ 257 RCM_yawRateQF "Restraint control module: yaw rate QF";
CM_ SG_ 257 RCM_pitchRateQF "Restraint control module: pitch rate QF";
CM_ SG_ 257 RCM_inertial1Counter "Restraint control module: inertial1 counter";
CM_ SG_ 257 RCM_inertial1Checksum "Restraint control module: inertial1 checksum";
CM_ BO_ 273 "Restraint control module message: inertial2; frame length from the layout, not yet observed on a vehicle bus";
CM_ SG_ 273 RCM_longitudinalAccel "Offset compensated longitudinal acceleration measured by the airbag ECU. ISO axis convention (positive during forward acceleration); raw 32768 = signal not available (SNA)";
CM_ SG_ 273 RCM_lateralAccel "Reports offset compensated lateral acceleration measured by the airbag ECU. Follows ISO axis convention that measurements are positive during left turns and negative during right turns; raw 32768 = signal not available (SNA)";
CM_ SG_ 273 RCM_verticalAccel "Offset compensated vertical acceleration measured by the airbag ECU. ISO axis convention (positive up); raw 32768 = signal not available (SNA)";
CM_ SG_ 273 RCM_longitudinalAccelQF "Restraint control module: longitudinal accel QF";
CM_ SG_ 273 RCM_lateralAccelQF "Restraint control module: lateral accel QF";
CM_ SG_ 273 RCM_verticalAccelQF "Restraint control module: vertical accel QF";
CM_ SG_ 273 RCM_CGTranslationFault "Restraint control module: CG translation fault";
CM_ SG_ 273 RCM_inertial2Counter "Restraint control module: inertial2 counter";
CM_ SG_ 273 RCM_inertial2Checksum "Restraint control module: inertial2 checksum";
CM_ BO_ 849 "Restraint control module message: info; frame length from the layout, not yet observed on a vehicle bus";
CM_ SG_ 849 RCM_infoIndex "Restraint control module: info index";
CM_ SG_ 849 RCM_infoBuildType "Restraint control module: info build type";
CM_ SG_ 849 RCM_infoComponentID "Restraint control module: info component ID";
CM_ SG_ 849 RCM_infoPcbaID "Reports the Restraint Control Module (RCM) Printed Circuit Board Assembly (PCBA) identifier.";
CM_ SG_ 849 RCM_infoAssemblyID "Restraint control module: info assembly ID";
CM_ SG_ 849 RCM_infoUsageID "Reports the Restraint Control Module (RCM) usage identification.";
CM_ SG_ 849 RCM_infoApplicationCRC "Reports the Restraint Control Module (RCM) application Cyclic Redundancy Check (CRC).";
CM_ SG_ 849 RCM_infoBootUdsProtoVersion "Reports the Restraint Control Module (RCM) boot Unified Diagnostic Services (UDS) protocol version.";
CM_ SG_ 849 RCM_infoBootloaderCRC "Reports the Restraint Control Module (RCM) bootloader Cyclic Redundancy Check (CRC).";
CM_ SG_ 849 RCM_infoAlgoCalID "Reports the Restraint Control Module (RCM) algorithm calibration identification.";
CM_ SG_ 849 RCM_infoVariantCRC "Reports the Restraint Control Module (RCM) variant Cyclic Redundancy Check (CRC).";
CM_ BO_ 529 "Restraint control module message: status; frame length from the layout, not yet observed on a vehicle bus";
CM_ SG_ 529 RCM_statusChecksum "Restraint control module: status checksum";
CM_ SG_ 529 RCM_statusCounter "Restraint control module: status counter";
CM_ SG_ 529 RCM_armStatus "Reports the arm status of the Restraint Control Module (RCM); raw 3 = signal not available (SNA)";
CM_ SG_ 529 RCM_warningIndicatorState "Reports whether the Restraint Control Module (RCM) warning indicator is present on the User Interface (UI); raw 3 = signal not available (SNA)";
CM_ SG_ 529 RCM_passAirbagIndicatorRequest "Reports status of the Front Passenger Airbag Off telltale; raw 3 = signal not available (SNA)";
CM_ SG_ 529 RCM_airbagCutoffStatus "Reports the front passenger airbag enabled or disabled status; raw 3 = signal not available (SNA)";
CM_ SG_ 529 RCM_alrSwitchStatus "Reports status of the front passenger automatic locking seat belt retractor; raw 3 = signal not available (SNA)";
CM_ SG_ 529 RCM_vinLearnFlag "Reports whether the Vehicle Identification Number has been learned; raw 3 = signal not available (SNA)";
CM_ SG_ 529 RCM_seatTrackPositionDrvr "Driver seat track position status; raw 3 = signal not available (SNA)";
CM_ SG_ 529 RCM_seatTrackPositionPass "Passenger seat track position status; raw 3 = signal not available (SNA)";
CM_ SG_ 529 RCM_edr1State "Reports status of Restraint Control Module (RCM) Event Data Recorder (EDR) memory slot 1.";
CM_ SG_ 529 RCM_edr2State "Reports status of Restraint Control Module (RCM) Event Data Recorder (EDR) memory slot 2.";
CM_ SG_ 529 RCM_keepPowerReason "Restraint Control Module request to maintain power; raw 8 = signal not available (SNA)";
CM_ SG_ 529 RCM_imuOffsetLearnState "Restraint control module: imu offset learn state";
CM_ SG_ 529 RCM_edr3State "Reports status of Restraint Control Module (RCM) Event Data Recorder (EDR) memory slot 3.";
CM_ SG_ 529 RCM_driverOrientationInitStatus "Restraint control module: driver orientation init status; raw 7 = signal not available (SNA)";
CM_ SG_ 529 RCM_occupantClassificationSource "Indicates whether the occupant classification source is the Right Vehicle Controller (VCRIGHT) or the Occupancy Classification System - 1st Row Passenger (OCS1P).";
CM_ SG_ 529 RCM_pedProEDR1State "Reports status of the PedPro Event Data Recorder (EDR) memory slot 1.";
CM_ SG_ 529 RCM_pedProEDR2State "Reports status of the PedPro Event Data Recorder (EDR) memory slot 2.";
CM_ BO_ 1617 "Restraint control module message: uds response; frame length from the layout, not yet observed on a vehicle bus";
CM_ SG_ 1617 RCM_udsResponseData "Restraint control module: uds response data";
CM_ BO_ 1471 "RCU ECU message: alert log; frame length from the layout, not yet observed on a vehicle bus";
CM_ SG_ 1471 RCU_alertID "RCU ECU: alert ID";
CM_ SG_ 1471 RCU_alertState "RCU ECU: alert state";
CM_ SG_ 1471 RCU_a010_sensorPowerSupply "RCU ECU: a010 sensor power supply";
CM_ SG_ 1471 RCU_a010_sensorHardware "RCU ECU: a010 sensor hardware";
CM_ SG_ 1471 RCU_a010_sensorSignal "RCU ECU: a010 sensor signal";
CM_ SG_ 1471 RCU_a023_validityOnChassisBus "RCU ECU: a023 validity on chassis bus";
CM_ SG_ 1471 RCU_a023_validityOnPartyBus "RCU ECU: a023 validity on party bus";
CM_ SG_ 1471 RCU_a024_validityOnChassisBus "RCU ECU: a024 validity on chassis bus";
CM_ SG_ 1471 RCU_a024_validityOnPartyBus "RCU ECU: a024 validity on party bus";
CM_ SG_ 1471 RCU_a025_validityOnChassisBus "RCU ECU: a025 validity on chassis bus";
CM_ SG_ 1471 RCU_a025_validityOnPartyBus "RCU ECU: a025 validity on party bus";
CM_ SG_ 1471 RCU_a035_validityOnChassisBus "RCU ECU: a035 validity on chassis bus";
CM_ SG_ 1471 RCU_a035_validityOnPartyBus "RCU ECU: a035 validity on party bus";
CM_ SG_ 1471 RCU_a036_validityOnChassisBus "RCU ECU: a036 validity on chassis bus";
CM_ SG_ 1471 RCU_a036_validityOnPartyBus "RCU ECU: a036 validity on party bus";
CM_ BO_ 998 "RCU ECU message: alert matrix; frame length from the layout, not yet observed on a vehicle bus";
CM_ SG_ 998 RCU_matrixIndex "RCU ECU: matrix index";
CM_ SG_ 998 RCU_a001_valveDriverFault "RCU ECU: a001 valve driver fault";
CM_ SG_ 998 RCU_a002_solenoidValveFault "RCU ECU: a002 solenoid valve fault";
CM_ SG_ 998 RCU_a003_pumpMotorFault "RCU ECU: a003 pump motor fault";
CM_ SG_ 998 RCU_a004_supplyOvervoltage "RCU ECU: a004 supply overvoltage";
CM_ SG_ 998 RCU_a005_supplyUndervoltage "RCU ECU: a005 supply undervoltage";
CM_ SG_ 998 RCU_a006_wakeLineOpen "RCU ECU: a006 wake line open";
CM_ SG_ 998 RCU_a007_pressureSensorFault "RCU ECU: a007 pressure sensor fault";
CM_ SG_ 998 RCU_a008_pressureNotCalibrated "RCU ECU: a008 pressure not calibrated";
CM_ SG_ 998 RCU_a009_brakeFluidLow "RCU ECU: a009 brake fluid low";
CM_ SG_ 998 RCU_a010_pedalSensorFault "RCU ECU: a010 pedal sensor fault";
CM_ SG_ 998 RCU_a011_idbPedalTravelMismatch "RCU ECU: a011 idb pedal travel mismatch";
CM_ SG_ 998 RCU_a012_pedalSensorNotCal "RCU ECU: a012 pedal sensor not cal";
CM_ SG_ 998 RCU_a013_mcuGenericFault "RCU ECU: a013 mcu generic fault";
CM_ SG_ 998 RCU_a014_asicTempHigh "RCU ECU: a014 asic temp high";
CM_ SG_ 998 RCU_a015_fluidLeakDetected "RCU ECU: a015 fluid leak detected";
CM_ SG_ 998 RCU_a016_partyBusOff "RCU ECU: a016 party bus off";
CM_ SG_ 998 RCU_a017_chassisBusOff "RCU ECU: a017 chassis bus off";
CM_ SG_ 998 RCU_a018_DItorquePathFaulted "RCU ECU: a018 d itorque path faulted";
CM_ SG_ 998 RCU_a019_DItorquePathActive "RCU ECU: a019 d itorque path active";
CM_ SG_ 998 RCU_a020_BBstatusDLC "RCU ECU: a020 b bstatus DLC";
CM_ SG_ 998 RCU_a021_BBstatusChecksum "RCU ECU: a021 b bstatus checksum";
CM_ SG_ 998 RCU_a022_BBstatusCounter "RCU ECU: a022 b bstatus counter";
CM_ SG_ 998 RCU_a023_IDBstatusDLC "RCU ECU: a023 ID bstatus DLC";
CM_ SG_ 998 RCU_a024_IDBstatusChecksum "RCU ECU: a024 ID bstatus checksum";
CM_ SG_ 998 RCU_a025_IDBstatusCounter "RCU ECU: a025 ID bstatus counter";
CM_ SG_ 998 RCU_a026_DIchassisControlDLC "RCU ECU: a026 d ichassis control DLC";
CM_ SG_ 998 RCU_a027_DIchassisCtrlChecksum "RCU ECU: a027 d ichassis ctrl checksum";
CM_ SG_ 998 RCU_a028_DIchassisControlCounter "RCU ECU: a028 d ichassis control counter";
CM_ SG_ 998 RCU_a029_PMstate2DLC "RCU ECU: a029 p mstate2 DLC";
CM_ SG_ 998 RCU_a030_PMstate2Checksum "RCU ECU: a030 p mstate2 checksum";
CM_ SG_ 998 RCU_a031_PMstate2Counter "RCU ECU: a031 p mstate2 counter";
CM_ SG_ 998 RCU_a032_VCFRONTLVPowerStateDLC "RCU ECU: a032 VCFRONTLV power state DLC";
CM_ SG_ 998 RCU_a033_VCFRONTLVPowerStateChec "RCU ECU: a033 VCFRONTLV power state checksum";
CM_ SG_ 998 RCU_a034_VCFRONTLVPowerStateCoun "RCU ECU: a034 VCFRONTLV power state counter";
CM_ SG_ 998 RCU_a035_IDBpcpInvalid "RCU ECU: a035 ID bpcp invalid";
CM_ SG_ 998 RCU_a036_IDBpspInvalid "RCU ECU: a036 ID bpsp invalid";
CM_ SG_ 998 RCU_a037_IDBinputRodStrokeInvali "RCU ECU: a037 ID binput rod stroke invalid";
CM_ SG_ 998 RCU_a038_DIsystemStatusDLC "RCU ECU: a038 d isystem status DLC";
CM_ SG_ 998 RCU_a039_DIaccelPosInvalid "RCU ECU: a039 d iaccel pos invalid";
CM_ SG_ 998 RCU_a040_DIgearInvalid "RCU ECU: a040 d igear invalid";
CM_ SG_ 998 RCU_a041_DIsystemStatusCounter "RCU ECU: a041 d isystem status counter";
CM_ SG_ 998 RCU_a042_DIsystemStatusChecksum "RCU ECU: a042 d isystem status checksum";
CM_ SG_ 998 RCU_a043_VCFRONTiBoosterLvStateI "RCU ECU: a043 VCFRON ti booster lv state invalid";
CM_ SG_ 998 RCU_a044_VCFRONTsensorsMIA "RCU ECU: a044 VCFRON tsensors MIA";
CM_ SG_ 998 RCU_a045_VCFRONTtempInvalid "RCU ECU: a045 VCFRON ttemp invalid";
CM_ SG_ 998 RCU_a046_brakeFluidLevelSNA "RCU ECU: a046 brake fluid level SNA";
CM_ SG_ 998 RCU_a047_ESPwheelSpeedsDLC "RCU ECU: a047 ES pwheel speeds DLC";
CM_ SG_ 998 RCU_a048_ESPFrLWSSLInvalid "RCU ECU: a048 ESP fr LWSSL invalid";
CM_ SG_ 998 RCU_a049_ESPFrRWSSLInvalid "RCU ECU: a049 ESP fr RWSSL invalid";
CM_ SG_ 998 RCU_a050_ESPReLWSSLInvalid "RCU ECU: a050 ESP re LWSSL invalid";
CM_ SG_ 998 RCU_a051_ESPReRWSSLInvalid "RCU ECU: a051 ESP re RWSSL invalid";
CM_ SG_ 998 RCU_a052_ESPwheelSpeedsCounter "RCU ECU: a052 ES pwheel speeds counter";
CM_ SG_ 998 RCU_a053_ESPwheelSpeedsChecksum "RCU ECU: a053 ES pwheel speeds checksum";
CM_ SG_ 998 RCU_a054_IDBcircuitPressFaulted "RCU ECU: a054 ID bcircuit press faulted";
CM_ SG_ 998 RCU_a055_IDBsimulatorPressFaulte "RCU ECU: a055 ID bsimulator press faulted";
CM_ SG_ 998 RCU_a056_redundantControllerIsMa "RCU ECU: a056 redundant controller is master";
CM_ SG_ 998 RCU_a057_DASredundantBrakingCont "RCU ECU: a057 DA sredundant braking control DLC";
CM_ SG_ 998 RCU_a058_DASredundantBrakingCont "RCU ECU: a058 DA sredundant braking control counter";
CM_ SG_ 998 RCU_a059_DASredundantBrakingCont "RCU ECU: a059 DA sredundant braking control checksum";
CM_ SG_ 998 RCU_a060_DASbrakeTorqueCommandIn "RCU ECU: a060 DA sbrake torque command invalid";
CM_ SG_ 998 RCU_a061_DIlocStatus2DLC "RCU ECU: a061 d iloc status2 DLC";
CM_ SG_ 998 RCU_a062_DIlocStatus2Counter "RCU ECU: a062 d iloc status2 counter";
CM_ SG_ 998 RCU_a063_DIlocStatus2Checksum "RCU ECU: a063 d iloc status2 checksum";
CM_ SG_ 998 RCU_a064_ESPredundantBrakingStat "RCU ECU: a064 ES predundant braking status DLC";
CM_ SG_ 998 RCU_a065_ESPredundantBrakingStat "RCU ECU: a065 ES predundant braking status counter";
CM_ SG_ 998 RCU_a066_ESPredundantBrakingStat "RCU ECU: a066 ES predundant braking status checksum";
CM_ BO_ 831 "RCU ECU message: info; frame length from the layout, not yet observed on a vehicle bus";
CM_ SG_ 831 RCU_infoIndex "RCU ECU: info index";
CM_ SG_ 831 RCU_infoPcbaID "RCU ECU: info pcba ID";
CM_ SG_ 831 RCU_infoAssemblyID "RCU ECU: info assembly ID";
CM_ SG_ 831 RCU_infoUsageID "RCU ECU: info usage ID";
CM_ SG_ 831 RCU_infoSubUsageID "RCU ECU: info sub usage ID";
CM_ BO_ 879 "Tire pressure monitoring message: status c; frame length from the layout, not yet observed on a vehicle bus";
CM_ SG_ 879 TPMS_c_globalHardWarning "Tire pressure monitoring: c global hard warning";
CM_ SG_ 879 TPMS_c_globalSoftWarning "Tire pressure monitoring: c global soft warning";
CM_ SG_ 879 TPMS_systemMalfunction "Tire pressure monitoring: system malfunction";
CM_ SG_ 879 TPMS_WA_version "Tire pressure monitoring: WA version";
CM_ SG_ 879 TPMS_globalDeltaPressure "Tire pressure monitoring: global delta pressure";
CM_ SG_ 879 TPMS_newSensorLearnt "Tire pressure monitoring: new sensor learnt";
CM_ SG_ 879 TPMS_softWarningRR "Tire pressure monitoring: soft warning RR";
CM_ SG_ 879 TPMS_hardWarningRR "Tire pressure monitoring: hard warning RR";
CM_ SG_ 879 TPMS_softWarningRL "Tire pressure monitoring: soft warning RL";
CM_ SG_ 879 TPMS_hardWarningRL "Tire pressure monitoring: hard warning RL";
CM_ SG_ 879 TPMS_softWarningFR "Tire pressure monitoring: soft warning FR";
CM_ SG_ 879 TPMS_hardWarningFR "Tire pressure monitoring: hard warning FR";
CM_ SG_ 879 TPMS_softWarningFL "Tire pressure monitoring: soft warning FL";
CM_ SG_ 879 TPMS_hardWarningFL "Tire pressure monitoring: hard warning FL";
CM_ SG_ 879 TPMS_learningStatus "Monitors Tire Pressure Monitoring System (TPMS) Learn Status and evaluates issues.";
CM_ SG_ 879 TPMS_localisationStatus "Monitors Tire Pressure Monitoring System (TPMS) Localization Status and evaluates issues.";
CM_ SG_ 879 TPMS_deltaPressWarningFL "Tire pressure monitoring: delta press warning FL";
CM_ SG_ 879 TPMS_deltaPressWarningFR "Tire pressure monitoring: delta press warning FR";
CM_ SG_ 879 TPMS_deltaPressWarningRL "Tire pressure monitoring: delta press warning RL";
CM_ SG_ 879 TPMS_deltaPressWarningRR "Tire pressure monitoring: delta press warning RR";
CM_ SG_ 879 TPMS_sensorNoResponseFL "Count of times Front Left sensor did not respond to message";
CM_ SG_ 879 TPMS_sensorNoResponseFR "Count of times Front Right sensor did not respond to message";
CM_ SG_ 879 TPMS_sensorNoResponseRL "Count of times Rear Left sensor did not respond to message";
CM_ SG_ 879 TPMS_sensorNoResponseRR "Count of times Rear Right sensor did not respond to message";
CM_ SG_ 879 TPMS_sensorThermShutdownFL "Tire pressure monitoring: sensor therm shutdown FL";
CM_ SG_ 879 TPMS_sensorThermShutdownFR "Tire pressure monitoring: sensor therm shutdown FR";
CM_ SG_ 879 TPMS_sensorThermShutdownRL "Tire pressure monitoring: sensor therm shutdown RL";
CM_ SG_ 879 TPMS_sensorThermShutdownRR "Tire pressure monitoring: sensor therm shutdown RR";
CM_ SG_ 879 TPMS_sensorBatteryLowFL "Tracks near end of life sensor batteries in the fleet.";
CM_ SG_ 879 TPMS_sensorBatteryLowFR "Tracks near end of life sensor batteries in the fleet.";
CM_ SG_ 879 TPMS_sensorBatteryLowRL "Tracks near end of life sensor batteries in the fleet.";
CM_ SG_ 879 TPMS_sensorBatteryLowRR "Tracks near end of life sensor batteries in the fleet.";
CM_ SG_ 879 TPMS_sensorDefectiveFL "Tracks malfunctioning sensors in the fleet.";
CM_ SG_ 879 TPMS_sensorDefectiveFR "Tracks malfunctioning sensors in the fleet.";
CM_ SG_ 879 TPMS_sensorDefectiveRL "Tracks malfunctioning sensors in the fleet.";
CM_ SG_ 879 TPMS_sensorDefectiveRR "Tracks malfunctioning sensors in the fleet.";
CM_ SG_ 879 TPMS_ecuUnderVoltage "Tire pressure monitoring: ecu under voltage";
CM_ SG_ 879 TPMS_ecuOverVoltage "Tire pressure monitoring: ecu over voltage";
CM_ SG_ 879 TPMS_ecuRamRomNvMFail "Tire pressure monitoring: ecu ram rom nv m fail";
CM_ SG_ 879 TPMS_rfReceiverFail "Tire pressure monitoring: rf receiver fail";
CM_ SG_ 879 TPMS_wheelPulseMissing "Tire pressure monitoring: wheel pulse missing";
CM_ SG_ 879 TPMS_vehicleSpeedFail "Tire pressure monitoring: vehicle speed fail";
CM_ SG_ 879 TPMS_externalTemperatureFail "Tire pressure monitoring: external temperature fail";
CM_ SG_ 879 TPMS_eolNotCompleted "Monitors sensor completion of End of Line (EOL) routine.";
CM_ SG_ 879 TPMS_rcpFront "Front tire recommended cold pressure";
CM_ SG_ 879 TPMS_rcpRear "Rear tire recommended cold pressure";
CM_ BO_ 799 "Tire pressure monitoring message: data; frame length from the layout, not yet observed on a vehicle bus";
CM_ SG_ 799 TPMS_pressureFL "front left tire pressure; raw 255 = signal not available (SNA)";
CM_ SG_ 799 TPMS_temperatureFL "front left tire temperature; raw 255 = signal not available (SNA)";
CM_ SG_ 799 TPMS_pressureFR "front right tire pressure; raw 255 = signal not available (SNA)";
CM_ SG_ 799 TPMS_temperatureFR "front right tire temperature; raw 255 = signal not available (SNA)";
CM_ SG_ 799 TPMS_pressureRL "rear left tire pressure; raw 255 = signal not available (SNA)";
CM_ SG_ 799 TPMS_temperatureRL "rear left tire temperature; raw 255 = signal not available (SNA)";
CM_ SG_ 799 TPMS_pressureRR "rear right tire pressure; raw 255 = signal not available (SNA)";
CM_ SG_ 799 TPMS_temperatureRR "rear right tire temperature; raw 255 = signal not available (SNA)";
CM_ BO_ 1519 "Tire pressure monitoring message: info; frame length from the layout, not yet observed on a vehicle bus";
CM_ SG_ 1519 TPMS_infoIndex "Tire pressure monitoring: info index";
CM_ SG_ 1519 TPMS_infoComponentID "Tire pressure monitoring: info component ID";
CM_ SG_ 1519 TPMS_infoPcbaID "Tire pressure monitoring: info pcba ID";
CM_ SG_ 1519 TPMS_infoAssemblyID "Tire pressure monitoring: info assembly ID";
CM_ SG_ 1519 TPMS_infoUsageID "Tire pressure monitoring: info usage ID";
CM_ SG_ 1519 TPMS_infoApplicationCRC "Tire pressure monitoring: info application CRC";
CM_ SG_ 1519 TPMS_infoBootUdsProtoVersion "Tire pressure monitoring: info boot uds proto version";
CM_ SG_ 1519 TPMS_infoBootloaderCRC "Tire pressure monitoring: info bootloader CRC";
CM_ BO_ 1631 "Tire pressure monitoring message: uds response; frame length from the layout, not yet observed on a vehicle bus";
CM_ SG_ 1631 TPMS_udsResponseData "Tire pressure monitoring: uds response data";
CM_ BO_ 1609 "UDS ECU message: das request; forwarded onto this bus by the gateway; frame length from the layout, not yet observed on a vehicle bus";
CM_ SG_ 1609 UDS_dasRequestData "UDS ECU: das request data";
CM_ BO_ 1584 "UDS ECU message: epas3p request; forwarded onto this bus by the gateway; frame length from the layout, not yet observed on a vehicle bus";
CM_ SG_ 1584 UDS_epas3pRequestData "UDS ECU: epas3p request data";
CM_ BO_ 1840 "UDS ECU message: epas3s request; forwarded onto this bus by the gateway; frame length from the layout, not yet observed on a vehicle bus";
CM_ SG_ 1840 UDS_epas3sRequestData "UDS ECU: epas3s request data";
CM_ BO_ 1605 "UDS ECU message: esp request; forwarded onto this bus by the gateway; frame length from the layout, not yet observed on a vehicle bus";
CM_ SG_ 1605 UDS_espRequestData "UDS ECU: esp request data";
CM_ BO_ 2015 "UDS ECU message: functional request CH; forwarded onto this bus by the gateway; frame length from the layout, not yet observed on a vehicle bus";
CM_ SG_ 2015 UDS_functionalRequestDataCH "UDS ECU: functional request data CH";
CM_ BO_ 1613 "UDS ECU message: ibst request; forwarded onto this bus by the gateway; frame length from the layout, not yet observed on a vehicle bus";
CM_ SG_ 1613 UDS_ibstRequestData "UDS ECU: ibst request data";
CM_ BO_ 1614 "UDS ECU message: park request; forwarded onto this bus by the gateway; frame length from the layout, not yet observed on a vehicle bus";
CM_ SG_ 1614 UDS_parkRequestData "UDS ECU: park request data";
CM_ BO_ 1649 "UDS ECU message: radc request; forwarded onto this bus by the gateway; frame length from the layout, not yet observed on a vehicle bus";
CM_ SG_ 1649 UDS_radcRequestData "UDS ECU: radc request data";
CM_ BO_ 1601 "UDS ECU message: rcm request; forwarded onto this bus by the gateway; frame length from the layout, not yet observed on a vehicle bus";
CM_ SG_ 1601 UDS_rcmRequestData "UDS ECU: rcm request data";
CM_ BO_ 1615 "UDS ECU message: tpms request; forwarded onto this bus by the gateway; frame length from the layout, not yet observed on a vehicle bus";
CM_ SG_ 1615 UDS_tpmsRequestData "UDS ECU: tpms request data";
CM_ BO_ 1021 "Touchscreen user interface computer message: autopilot control; forwarded onto this bus by the gateway; frame length from the layout, not yet observed on a vehicle bus";
CM_ SG_ 1021 UI_autopilotControlIndex "Touchscreen user interface computer: autopilot control index";
CM_ SG_ 1021 UI_hovEnabled "UI HOV routes enabled";
CM_ SG_ 1021 UI_donDisableAutoWiperDuration "Touchscreen user interface computer: don disable auto wiper duration";
CM_ SG_ 1021 UI_donDisableOnAutoWiperSpeed "Touchscreen user interface computer: don disable on auto wiper speed";
CM_ SG_ 1021 UI_blindspotMinSpeed "Touchscreen user interface computer: blindspot min speed";
CM_ SG_ 1021 UI_blindspotDistance "Touchscreen user interface computer: blindspot distance";
CM_ SG_ 1021 UI_blindspotTTC "Touchscreen user interface computer: blindspot TTC";
CM_ SG_ 1021 UI_donStopEndOfRampBuffer "Touchscreen user interface computer: don stop end of ramp buffer";
CM_ SG_ 1021 UI_donDisableCutin "Touchscreen user interface computer: don disable cutin";
CM_ SG_ 1021 UI_smartSetSpeedOffset "TACC will apply this offset over the speed limit";
CM_ SG_ 1021 UI_smartSetSpeedOffsetType "Offset applied will be a percentage or fixed value based on this setting";
CM_ SG_ 1021 UI_autopilotMonarchBackup "Touchscreen user interface computer: autopilot monarch backup";
CM_ SG_ 1021 UI_fsdVisualizationEnabled "Touchscreen user interface computer: fsd visualization enabled";
CM_ SG_ 1021 UI_fsdStopsControlEnabled "Indicates if autopilot control for traffic lights and stops signs has been enabled by the driver";
CM_ SG_ 1021 UI_fsdContinueOnGreenWithCIPV "Touchscreen user interface computer: fsd continue on green with CIPV";
CM_ SG_ 1021 UI_smartSetSpeed "TACC will use speed limit + offset as user set speed when enabled";
CM_ SG_ 1021 UI_automaticSetSpeedOffset "Maximum set speed offset would be determined automatically when this option is enabled";
CM_ SG_ 1021 UI_apply2021_1958_ISA "Touchscreen user interface computer: apply2021 1958 ISA";
CM_ SG_ 1021 UI_apply2021_646_ELKS "Touchscreen user interface computer: apply2021 646 ELKS";
CM_ SG_ 1021 UI_apply2021_1341_DDAW "Touchscreen user interface computer: apply2021 1341 DDAW";
CM_ SG_ 1021 UI_homelinkNearby "Touchscreen user interface computer: homelink nearby";
CM_ SG_ 1021 UI_enableFullSelfDriving "Indicates if the driver has enabled FSD behaviors";
CM_ SG_ 1021 UI_hasFullSelfDriving "Indicates if the vehicle hardware, software, and dependencies allow FSD";
CM_ SG_ 1021 UI_autosteerActivation "User-selected autosteer activation method";
CM_ SG_ 1021 UI_fsdBetaRequest "User accepted disclaimer and requested FSD (Supervised) builds";
CM_ SG_ 1021 UI_fullSelfDrivingSuspended "Full self driving is suspended";
CM_ SG_ 1021 UI_disableOptionalLaneChanges "Disable optional lane changes while FSD is controlling";
CM_ SG_ 1021 UI_applyR152_AEBS "Touchscreen user interface computer: apply R152 AEBS";
CM_ SG_ 1021 UI_applyDCASBehavior "Touchscreen user interface computer: apply DCAS behavior";
CM_ SG_ 1021 UI_applyDCASBehaviorLegacy "Touchscreen user interface computer: apply DCAS behavior legacy";
CM_ SG_ 1021 UI_applyADDWWarnings "ADDW warnings are enabled on this vehicle";
CM_ SG_ 1021 UI_autopilotControlMux0Valid "Touchscreen user interface computer: autopilot control mux0 valid";
CM_ SG_ 1021 UI_selectableCameraRequest "Infotainment selectable camera state request from AP signal; raw 15 = signal not available (SNA)";
CM_ SG_ 1021 UI_overrideSleepWithSuspend "Touchscreen user interface computer: override sleep with suspend";
CM_ SG_ 1021 UI_driverMonitorConfirmation "Driver attentiveness confirmation";
CM_ SG_ 1021 UI_parkAssistUseVision "Reports if the vehicle should use vision park assist.";
CM_ SG_ 1021 UI_applyEceR79 "Touchscreen user interface computer: apply ece R79";
CM_ SG_ 1021 UI_enableMapStops "Touchscreen user interface computer: enable map stops";
CM_ SG_ 1021 UI_disableMain "Touchscreen user interface computer: disable main";
CM_ SG_ 1021 UI_disableNarrow "Touchscreen user interface computer: disable narrow";
CM_ SG_ 1021 UI_disableFisheye "Touchscreen user interface computer: disable fisheye";
CM_ SG_ 1021 UI_disableLeftPillar "Touchscreen user interface computer: disable left pillar";
CM_ SG_ 1021 UI_disableRightPillar "Touchscreen user interface computer: disable right pillar";
CM_ SG_ 1021 UI_disableLeftRepeater "Touchscreen user interface computer: disable left repeater";
CM_ SG_ 1021 UI_disableRightRepeater "Touchscreen user interface computer: disable right repeater";
CM_ SG_ 1021 UI_disableBackup "Touchscreen user interface computer: disable backup";
CM_ SG_ 1021 UI_disableRadar "Touchscreen user interface computer: disable radar";
CM_ SG_ 1021 UI_noStalkConfirmAlertHaptic "Detects if alert haptic feedback should trigger.";
CM_ SG_ 1021 UI_regulatoryLKA "Touchscreen user interface computer: regulatory LKA";
CM_ SG_ 1021 UI_regulatoryLaneAssistLevel "Touchscreen user interface computer: regulatory lane assist level";
CM_ SG_ 1021 UI_ulcSnooze "Touchscreen user interface computer: ulc snooze";
CM_ SG_ 1021 UI_noStalkConfirmAlertChime "Detects if alert chime should trigger.";
CM_ SG_ 1021 UI_factorySummonEnable "Controls Factory Summon.";
CM_ SG_ 1021 UI_apmv3Branch "Touchscreen user interface computer: apmv3 branch";
CM_ SG_ 1021 UI_enableCabinCamera "Indicates if autopilot can enable cabin camera";
CM_ SG_ 1021 UI_enableAutopilotStopWarning "Enables the Autopilot active red light warning function.";
CM_ SG_ 1021 UI_showLaneGraph "Touchscreen user interface computer: show lane graph";
CM_ SG_ 1021 UI_showTrackLabels "Touchscreen user interface computer: show track labels";
CM_ SG_ 1021 UI_hardCoreSummon "Touchscreen user interface computer: hard core summon";
CM_ SG_ 1021 UI_enableCabinCameraTelemetry "Touchscreen user interface computer: enable cabin camera telemetry";
CM_ SG_ 1021 UI_enableVisionSpeedControl "Indicates if autopilot can enable vision speed control";
CM_ SG_ 1021 UI_autopilotTelemetryInChina "Touchscreen user interface computer: autopilot telemetry in china";
CM_ SG_ 1021 UI_enableTeslaAutopark "Indicates if autopilot can enable Telsa Autopark control";
CM_ SG_ 1021 UI_autoTurnSignalMode "Turn signal activation mode";
CM_ SG_ 1021 UI_enableCautionLightControl "Touchscreen user interface computer: enable caution light control";
CM_ SG_ 1021 UI_applyEceR79SmartSummonOnly "Touchscreen user interface computer: apply ece R79 smart summon only";
CM_ SG_ 1021 UI_autopilotMonarchEnabled "Touchscreen user interface computer: autopilot monarch enabled";
CM_ SG_ 1021 UI_autopilotEphemerisEnabled "Touchscreen user interface computer: autopilot ephemeris enabled";
CM_ SG_ 1021 UI_enableCabinAudioRecording "Indicates if autopilot can record cabin audio";
CM_ SG_ 1021 UI_autopilotControlMux1Valid "Touchscreen user interface computer: autopilot control mux1 valid";
CM_ SG_ 1021 UI_enableApproachingEmergencyVeh "Touchscreen user interface computer: enable approaching emergency vehicle detection";
CM_ SG_ 1021 UI_enableStartFsdFromParkBrakeCo "Touchscreen user interface computer: enable start fsd from park brake confirmation";
CM_ SG_ 1021 UI_enableStartFsdFromPark "Touchscreen user interface computer: enable start fsd from park";
CM_ SG_ 1021 UI_fsdMaxSpeedOffsetPercentage "Touchscreen user interface computer: fsd max speed offset percentage";
CM_ SG_ 1021 UI_calibrationReadyInFactory "Touchscreen user interface computer: calibration ready in factory";
CM_ SG_ 1021 UI_coldStartMonarchInFactory "Touchscreen user interface computer: cold start monarch in factory";
CM_ SG_ 1021 UI_navMinutesToArrival "Touchscreen user interface computer: nav minutes to arrival";
CM_ SG_ 1021 UI_fsdQuizRequired "Touchscreen user interface computer: fsd quiz required";
CM_ SG_ 1021 UI_fsdQuizPassed "Touchscreen user interface computer: fsd quiz passed";
CM_ SG_ 1021 UI_fsdAllowedInLocalizedRegion "Touchscreen user interface computer: fsd allowed in localized region";
CM_ SG_ 1021 UI_autopilotDrivingProfile "Driving profile for autopilot control";
CM_ SG_ 1021 UI_autopilotControlMux2Valid "Touchscreen user interface computer: autopilot control mux2 valid";
CM_ BO_ 659 "Touchscreen user interface computer message: chassis control; forwarded onto this bus by the gateway; frame length from the layout, not yet observed on a vehicle bus";
CM_ SG_ 659 UI_steeringTuneRequest "UI customer level request for steering feel. MS had comfort, normal, sport. M3 intent is Normal, sport see SW-95934";
CM_ SG_ 659 UI_tractionControlMode "Transport user selected traction control modes";
CM_ SG_ 659 UI_parkBrakeRequest "User selection for Park brake; raw 3 = signal not available (SNA)";
CM_ SG_ 659 UI_narrowGarages "Touchscreen user interface computer: narrow garages";
CM_ SG_ 659 UI_winchModeRequest "Winch mode (towing) request";
CM_ SG_ 659 UI_zeroSpeedConfirmed "Touchscreen user interface computer: zero speed confirmed; raw 3 = signal not available (SNA)";
CM_ SG_ 659 UI_trailerMode "Indicates whether trailer mode is selected. To be used when towing a trailer.";
CM_ SG_ 659 UI_distanceUnits "Touchscreen user interface computer: distance units";
CM_ SG_ 659 UI_dasDebugEnable "Touchscreen user interface computer: das debug enable";
CM_ SG_ 659 UI_accOvertakeEnable "Enable ACC Overtake assistance (reduce follow distance when the turn signal is on), UI firmware only sets datavalue to True; raw 3 = signal not available (SNA)";
CM_ SG_ 659 UI_aebEnable "Enable Autonomous Emergency Brakes; raw 3 = signal not available (SNA)";
CM_ SG_ 659 UI_aesEnable "Enable Automatic Emergency Steering (associated datavalue set to true and never changed by UI firmware); raw 3 = signal not available (SNA)";
CM_ SG_ 659 UI_ahlbEnable "Enable Automatic High/Low Beams; raw 3 = signal not available (SNA)";
CM_ SG_ 659 UI_autoLaneChangeEnable "Enable Automatic Lane Change; raw 3 = signal not available (SNA)";
CM_ SG_ 659 UI_winchProxUserOverride "User feedback from tow mode panel confirming that charge cable is disconnected when vehicle is unable to determine cable status";
CM_ SG_ 659 UI_rebootAutopilot "Touchscreen user interface computer: reboot autopilot";
CM_ SG_ 659 UI_autoParkRequest "Request Automatic Parking; raw 15 = signal not available (SNA)";
CM_ SG_ 659 UI_bsdEnable "Enable Blind Spot Detection (datavalue defaults to true and not changed by UI firmware); raw 3 = signal not available (SNA)";
CM_ SG_ 659 UI_fcwEnable "Enable Forward Collision Warning; raw 3 = signal not available (SNA)";
CM_ SG_ 659 UI_fcwSensitivity "Forward Collision Warning Level; raw 3 = signal not available (SNA)";
CM_ SG_ 659 UI_latControlEnable "Enable Lateral Control (lane centering, lane keeping, lane changing); raw 3 = signal not available (SNA)";
CM_ SG_ 659 UI_ldwEnable "Enable Lane Departure Warning; raw 3 = signal not available (SNA)";
CM_ SG_ 659 UI_pedalSafetyEnable "Touchscreen user interface computer: pedal safety enable; raw 3 = signal not available (SNA)";
CM_ SG_ 659 UI_pedalMap_epas "Touchscreen user interface computer: pedal map epas";
CM_ SG_ 659 UI_redLightStopSignEnable "Touchscreen user interface computer: red light stop sign enable; raw 3 = signal not available (SNA)";
CM_ SG_ 659 UI_selfParkTune "Touchscreen user interface computer: self park tune; raw 15 = signal not available (SNA)";
CM_ SG_ 659 UI_chassisControlCounter "Touchscreen user interface computer: chassis control counter";
CM_ SG_ 659 UI_chassisControlChecksum "Touchscreen user interface computer: chassis control checksum";
CM_ BO_ 664 "Touchscreen user interface computer message: csa offramp curvature; forwarded onto this bus by the gateway; frame length from the layout, not yet observed on a vehicle bus";
CM_ SG_ 664 UI_csaOfframpCurvC2 "Touchscreen user interface computer: csa offramp curv C2";
CM_ SG_ 664 UI_csaOfframpCurvC3 "Touchscreen user interface computer: csa offramp curv C3";
CM_ SG_ 664 UI_csaOfframpCurvRange "Touchscreen user interface computer: csa offramp curv range";
CM_ SG_ 664 UI_csaOfframpCurvCounter "Touchscreen user interface computer: csa offramp curv counter";
CM_ SG_ 664 UI_csaOfframpCurvUsingTspline "Touchscreen user interface computer: csa offramp curv using tspline";
CM_ SG_ 664 UI_csaOfframpCurvReserved "Touchscreen user interface computer: csa offramp curv reserved";
CM_ SG_ 664 UI_csaOfframpCurvChecksum "Touchscreen user interface computer: csa offramp curv checksum";
BA_DEF_ BO_ "GenMsgCycleTime" INT 0 3600000;
BA_DEF_ BO_ "GenMsgSendType" ENUM "Cyclic","NotUsed","NotUsed","NotUsed","NotUsed","NotUsed","NotUsed","IfActive","NoMsgSendType","NotUsed";
BA_DEF_ BO_ "VFrameFormat" ENUM "StandardCAN","ExtendedCAN","reserved","J1939PG","reserved","reserved","reserved","reserved","reserved","reserved","reserved","reserved","reserved","reserved","StandardCAN_FD","ExtendedCAN_FD";
BA_DEF_ BO_ "CANFD_BRS" ENUM "0","1";
BA_DEF_ SG_ "GenSigSNA" STRING;
BA_DEF_ SG_ "SystemSignalLongSymbol" STRING;
BA_DEF_ SG_ "Confidence" ENUM "validated","plausible","layout-only","contradicted";
BA_DEF_DEF_ "GenMsgCycleTime" 0;
BA_DEF_DEF_ "GenMsgSendType" "NoMsgSendType";
BA_DEF_DEF_ "VFrameFormat" "StandardCAN";
BA_DEF_DEF_ "CANFD_BRS" "1";
BA_DEF_DEF_ "GenSigSNA" "";
BA_DEF_DEF_ "SystemSignalLongSymbol" "";
BA_DEF_DEF_ "Confidence" "layout-only";
BA_ "GenMsgCycleTime" BO_ 1009 1000;
BA_ "GenMsgSendType" BO_ 1009 0;
BA_ "GenMsgCycleTime" BO_ 1010 1000;
BA_ "GenMsgSendType" BO_ 1010 0;
BA_ "GenMsgCycleTime" BO_ 257 20;
BA_ "GenMsgSendType" BO_ 257 0;
BA_ "GenMsgCycleTime" BO_ 273 20;
BA_ "GenMsgSendType" BO_ 273 0;
BA_ "GenMsgCycleTime" BO_ 849 2000;
BA_ "GenMsgSendType" BO_ 849 0;
BA_ "GenMsgCycleTime" BO_ 529 100;
BA_ "GenMsgSendType" BO_ 529 0;
BA_ "GenMsgCycleTime" BO_ 998 1000;
BA_ "GenMsgSendType" BO_ 998 0;
BA_ "GenMsgCycleTime" BO_ 831 10000;
BA_ "GenMsgSendType" BO_ 831 0;
BA_ "GenMsgCycleTime" BO_ 879 1000;
BA_ "GenMsgSendType" BO_ 879 0;
BA_ "GenMsgCycleTime" BO_ 799 1000;
BA_ "GenMsgSendType" BO_ 799 0;
BA_ "GenMsgCycleTime" BO_ 1519 1000;
BA_ "GenMsgSendType" BO_ 1519 0;
BA_ "GenMsgCycleTime" BO_ 1021 500;
BA_ "GenMsgSendType" BO_ 1021 0;
BA_ "GenMsgCycleTime" BO_ 659 500;
BA_ "GenMsgSendType" BO_ 659 0;
BA_ "GenMsgCycleTime" BO_ 664 500;
BA_ "GenMsgSendType" BO_ 664 0;
BA_ "Confidence" SG_ 1009 RCM2_matrixIndex 1;
BA_ "SystemSignalLongSymbol" SG_ 1009 RCM2_a270_imuPtchR8OffCompPosLif "RCM2_a270_imuPtchR8OffCompPosLife";
BA_ "SystemSignalLongSymbol" SG_ 1009 RCM2_a271_imuPtchR8OffCompNegLif "RCM2_a271_imuPtchR8OffCompNegLife";
BA_ "SystemSignalLongSymbol" SG_ 1009 RCM2_a272_imuPtchR8OffCompPosFLD "RCM2_a272_imuPtchR8OffCompPosFLDC";
BA_ "SystemSignalLongSymbol" SG_ 1009 RCM2_a273_imuPtchR8OffCompNegFLD "RCM2_a273_imuPtchR8OffCompNegFLDC";
BA_ "SystemSignalLongSymbol" SG_ 1009 RCM2_a274_imuPtchR8OffCompPosSLD "RCM2_a274_imuPtchR8OffCompPosSLDC";
BA_ "SystemSignalLongSymbol" SG_ 1009 RCM2_a275_imuPtchR8OffCompNegSLD "RCM2_a275_imuPtchR8OffCompNegSLDC";
BA_ "SystemSignalLongSymbol" SG_ 1009 RCM2_a276_imuRollR8OffCompPosLif "RCM2_a276_imuRollR8OffCompPosLife";
BA_ "SystemSignalLongSymbol" SG_ 1009 RCM2_a277_imuRollR8OffCompNegLif "RCM2_a277_imuRollR8OffCompNegLife";
BA_ "SystemSignalLongSymbol" SG_ 1009 RCM2_a278_imuRollR8OffCompPosFLD "RCM2_a278_imuRollR8OffCompPosFLDC";
BA_ "SystemSignalLongSymbol" SG_ 1009 RCM2_a279_imuRollR8OffCompNegFLD "RCM2_a279_imuRollR8OffCompNegFLDC";
BA_ "SystemSignalLongSymbol" SG_ 1009 RCM2_a280_imuRollR8OffCompPosSLD "RCM2_a280_imuRollR8OffCompPosSLDC";
BA_ "SystemSignalLongSymbol" SG_ 1009 RCM2_a281_imuRollR8OffCompNegSLD "RCM2_a281_imuRollR8OffCompNegSLDC";
BA_ "SystemSignalLongSymbol" SG_ 1009 RCM2_a590_sbrRearNetworkUndefine "RCM2_a590_sbrRearNetworkUndefined";
BA_ "SystemSignalLongSymbol" SG_ 1009 RCM2_a593_driveOrientationSht2Gn "RCM2_a593_driveOrientationSht2Gnd";
BA_ "SystemSignalLongSymbol" SG_ 1009 RCM2_a594_driveOrientationSht2Ba "RCM2_a594_driveOrientationSht2Bat";
BA_ "SystemSignalLongSymbol" SG_ 1009 RCM2_a596_driveOrientationUndefi "RCM2_a596_driveOrientationUndefined";
BA_ "SystemSignalLongSymbol" SG_ 1009 RCM2_a597_driveOrientationCrssCo "RCM2_a597_driveOrientationCrssCoup";
BA_ "SystemSignalLongSymbol" SG_ 1009 RCM2_a853_ConfigParametersIncons "RCM2_a853_ConfigParametersInconsistent";
BA_ "SystemSignalLongSymbol" SG_ 1009 RCM2_a854_ConfigParametersNotLea "RCM2_a854_ConfigParametersNotLearned";
BA_ "SystemSignalLongSymbol" SG_ 1009 RCM2_a859_comVCxLVPowerStateChkS "RCM2_a859_comVCxLVPowerStateChkSm";
BA_ "SystemSignalLongSymbol" SG_ 1009 RCM2_a861_typeApprovalStringNotL "RCM2_a861_typeApprovalStringNotLearned";
BA_ "SystemSignalLongSymbol" SG_ 1009 RCM2_a863_comVCFRONTalertMatrixM "RCM2_a863_comVCFRONTalertMatrixMIA";
BA_ "SystemSignalLongSymbol" SG_ 1009 RCM2_a865_comVCLVBMSstatusHighMI "RCM2_a865_comVCLVBMSstatusHighMIA";
BA_ "Confidence" SG_ 1252 RCM3_alertID 1;
BA_ "Confidence" SG_ 1252 RCM3_alertState 1;
BA_ "Confidence" SG_ 1010 RCM3_matrixIndex 1;
BA_ "Confidence" SG_ 257 RCM_yawRate 0;
BA_ "GenSigSNA" SG_ 257 RCM_yawRate "32768";
BA_ "Confidence" SG_ 257 RCM_pitchRate 0;
BA_ "GenSigSNA" SG_ 257 RCM_pitchRate "16384";
BA_ "Confidence" SG_ 257 RCM_rollRate 0;
BA_ "GenSigSNA" SG_ 257 RCM_rollRate "16384";
BA_ "Confidence" SG_ 257 RCM_rollRateQF 0;
BA_ "Confidence" SG_ 257 RCM_yawRateQF 0;
BA_ "Confidence" SG_ 257 RCM_pitchRateQF 0;
BA_ "Confidence" SG_ 257 RCM_inertial1Counter 0;
BA_ "Confidence" SG_ 257 RCM_inertial1Checksum 0;
BA_ "Confidence" SG_ 273 RCM_longitudinalAccel 0;
BA_ "GenSigSNA" SG_ 273 RCM_longitudinalAccel "32768";
BA_ "Confidence" SG_ 273 RCM_lateralAccel 0;
BA_ "GenSigSNA" SG_ 273 RCM_lateralAccel "32768";
BA_ "Confidence" SG_ 273 RCM_verticalAccel 0;
BA_ "GenSigSNA" SG_ 273 RCM_verticalAccel "32768";
BA_ "Confidence" SG_ 273 RCM_longitudinalAccelQF 0;
BA_ "Confidence" SG_ 273 RCM_lateralAccelQF 0;
BA_ "Confidence" SG_ 273 RCM_verticalAccelQF 0;
BA_ "Confidence" SG_ 273 RCM_CGTranslationFault 0;
BA_ "Confidence" SG_ 273 RCM_inertial2Counter 0;
BA_ "Confidence" SG_ 273 RCM_inertial2Checksum 0;
BA_ "Confidence" SG_ 849 RCM_infoIndex 1;
BA_ "Confidence" SG_ 849 RCM_infoBuildType 0;
BA_ "Confidence" SG_ 849 RCM_infoComponentID 0;
BA_ "Confidence" SG_ 849 RCM_infoPcbaID 0;
BA_ "Confidence" SG_ 849 RCM_infoAssemblyID 0;
BA_ "Confidence" SG_ 849 RCM_infoUsageID 0;
BA_ "Confidence" SG_ 849 RCM_infoApplicationCRC 0;
BA_ "Confidence" SG_ 849 RCM_infoBootUdsProtoVersion 0;
BA_ "Confidence" SG_ 849 RCM_infoBootloaderCRC 0;
BA_ "Confidence" SG_ 849 RCM_infoAlgoCalID 0;
BA_ "Confidence" SG_ 849 RCM_infoVariantCRC 0;
BA_ "Confidence" SG_ 529 RCM_statusChecksum 0;
BA_ "Confidence" SG_ 529 RCM_statusCounter 0;
BA_ "Confidence" SG_ 529 RCM_armStatus 0;
BA_ "GenSigSNA" SG_ 529 RCM_armStatus "3";
BA_ "Confidence" SG_ 529 RCM_warningIndicatorState 0;
BA_ "GenSigSNA" SG_ 529 RCM_warningIndicatorState "3";
BA_ "Confidence" SG_ 529 RCM_passAirbagIndicatorRequest 0;
BA_ "GenSigSNA" SG_ 529 RCM_passAirbagIndicatorRequest "3";
BA_ "Confidence" SG_ 529 RCM_airbagCutoffStatus 0;
BA_ "GenSigSNA" SG_ 529 RCM_airbagCutoffStatus "3";
BA_ "Confidence" SG_ 529 RCM_alrSwitchStatus 0;
BA_ "GenSigSNA" SG_ 529 RCM_alrSwitchStatus "3";
BA_ "Confidence" SG_ 529 RCM_vinLearnFlag 0;
BA_ "GenSigSNA" SG_ 529 RCM_vinLearnFlag "3";
BA_ "Confidence" SG_ 529 RCM_seatTrackPositionDrvr 0;
BA_ "GenSigSNA" SG_ 529 RCM_seatTrackPositionDrvr "3";
BA_ "Confidence" SG_ 529 RCM_seatTrackPositionPass 0;
BA_ "GenSigSNA" SG_ 529 RCM_seatTrackPositionPass "3";
BA_ "Confidence" SG_ 529 RCM_edr1State 0;
BA_ "Confidence" SG_ 529 RCM_edr2State 0;
BA_ "Confidence" SG_ 529 RCM_keepPowerReason 0;
BA_ "GenSigSNA" SG_ 529 RCM_keepPowerReason "8";
BA_ "Confidence" SG_ 529 RCM_imuOffsetLearnState 0;
BA_ "Confidence" SG_ 529 RCM_edr3State 0;
BA_ "Confidence" SG_ 529 RCM_driverOrientationInitStatus 0;
BA_ "GenSigSNA" SG_ 529 RCM_driverOrientationInitStatus "7";
BA_ "Confidence" SG_ 529 RCM_occupantClassificationSource 0;
BA_ "Confidence" SG_ 529 RCM_pedProEDR1State 0;
BA_ "Confidence" SG_ 529 RCM_pedProEDR2State 0;
BA_ "Confidence" SG_ 1617 RCM_udsResponseData 1;
BA_ "Confidence" SG_ 1471 RCU_alertID 1;
BA_ "Confidence" SG_ 1471 RCU_alertState 1;
BA_ "Confidence" SG_ 1471 RCU_a010_sensorPowerSupply 1;
BA_ "Confidence" SG_ 1471 RCU_a010_sensorHardware 1;
BA_ "Confidence" SG_ 1471 RCU_a010_sensorSignal 1;
BA_ "Confidence" SG_ 1471 RCU_a023_validityOnChassisBus 1;
BA_ "Confidence" SG_ 1471 RCU_a023_validityOnPartyBus 1;
BA_ "Confidence" SG_ 1471 RCU_a024_validityOnChassisBus 1;
BA_ "Confidence" SG_ 1471 RCU_a024_validityOnPartyBus 1;
BA_ "Confidence" SG_ 1471 RCU_a025_validityOnChassisBus 1;
BA_ "Confidence" SG_ 1471 RCU_a025_validityOnPartyBus 1;
BA_ "Confidence" SG_ 1471 RCU_a035_validityOnChassisBus 1;
BA_ "Confidence" SG_ 1471 RCU_a035_validityOnPartyBus 1;
BA_ "Confidence" SG_ 1471 RCU_a036_validityOnChassisBus 1;
BA_ "Confidence" SG_ 1471 RCU_a036_validityOnPartyBus 1;
BA_ "Confidence" SG_ 998 RCU_matrixIndex 1;
BA_ "SystemSignalLongSymbol" SG_ 998 RCU_a033_VCFRONTLVPowerStateChec "RCU_a033_VCFRONTLVPowerStateChecksum";
BA_ "SystemSignalLongSymbol" SG_ 998 RCU_a034_VCFRONTLVPowerStateCoun "RCU_a034_VCFRONTLVPowerStateCounter";
BA_ "SystemSignalLongSymbol" SG_ 998 RCU_a037_IDBinputRodStrokeInvali "RCU_a037_IDBinputRodStrokeInvalid";
BA_ "SystemSignalLongSymbol" SG_ 998 RCU_a043_VCFRONTiBoosterLvStateI "RCU_a043_VCFRONTiBoosterLvStateInvalid";
BA_ "SystemSignalLongSymbol" SG_ 998 RCU_a055_IDBsimulatorPressFaulte "RCU_a055_IDBsimulatorPressFaulted";
BA_ "SystemSignalLongSymbol" SG_ 998 RCU_a056_redundantControllerIsMa "RCU_a056_redundantControllerIsMaster";
BA_ "SystemSignalLongSymbol" SG_ 998 RCU_a057_DASredundantBrakingCont "RCU_a057_DASredundantBrakingControlDLC";
BA_ "SystemSignalLongSymbol" SG_ 998 RCU_a058_DASredundantBrakingCont "RCU_a058_DASredundantBrakingControlCounter";
BA_ "SystemSignalLongSymbol" SG_ 998 RCU_a059_DASredundantBrakingCont "RCU_a059_DASredundantBrakingControlChecksum";
BA_ "SystemSignalLongSymbol" SG_ 998 RCU_a060_DASbrakeTorqueCommandIn "RCU_a060_DASbrakeTorqueCommandInvalid";
BA_ "SystemSignalLongSymbol" SG_ 998 RCU_a064_ESPredundantBrakingStat "RCU_a064_ESPredundantBrakingStatusDLC";
BA_ "SystemSignalLongSymbol" SG_ 998 RCU_a065_ESPredundantBrakingStat "RCU_a065_ESPredundantBrakingStatusCounter";
BA_ "SystemSignalLongSymbol" SG_ 998 RCU_a066_ESPredundantBrakingStat "RCU_a066_ESPredundantBrakingStatusChecksum";
BA_ "Confidence" SG_ 831 RCU_infoIndex 1;
BA_ "Confidence" SG_ 831 RCU_infoPcbaID 0;
BA_ "Confidence" SG_ 831 RCU_infoAssemblyID 0;
BA_ "Confidence" SG_ 831 RCU_infoUsageID 0;
BA_ "Confidence" SG_ 831 RCU_infoSubUsageID 0;
BA_ "Confidence" SG_ 879 TPMS_c_globalHardWarning 0;
BA_ "Confidence" SG_ 879 TPMS_c_globalSoftWarning 0;
BA_ "Confidence" SG_ 879 TPMS_systemMalfunction 0;
BA_ "Confidence" SG_ 879 TPMS_WA_version 0;
BA_ "Confidence" SG_ 879 TPMS_globalDeltaPressure 0;
BA_ "Confidence" SG_ 879 TPMS_newSensorLearnt 0;
BA_ "Confidence" SG_ 879 TPMS_softWarningRR 0;
BA_ "Confidence" SG_ 879 TPMS_hardWarningRR 0;
BA_ "Confidence" SG_ 879 TPMS_softWarningRL 0;
BA_ "Confidence" SG_ 879 TPMS_hardWarningRL 0;
BA_ "Confidence" SG_ 879 TPMS_softWarningFR 0;
BA_ "Confidence" SG_ 879 TPMS_hardWarningFR 0;
BA_ "Confidence" SG_ 879 TPMS_softWarningFL 0;
BA_ "Confidence" SG_ 879 TPMS_hardWarningFL 0;
BA_ "Confidence" SG_ 879 TPMS_learningStatus 0;
BA_ "Confidence" SG_ 879 TPMS_localisationStatus 0;
BA_ "Confidence" SG_ 879 TPMS_deltaPressWarningFL 0;
BA_ "Confidence" SG_ 879 TPMS_deltaPressWarningFR 0;
BA_ "Confidence" SG_ 879 TPMS_deltaPressWarningRL 0;
BA_ "Confidence" SG_ 879 TPMS_deltaPressWarningRR 0;
BA_ "Confidence" SG_ 879 TPMS_sensorNoResponseFL 0;
BA_ "Confidence" SG_ 879 TPMS_sensorNoResponseFR 0;
BA_ "Confidence" SG_ 879 TPMS_sensorNoResponseRL 0;
BA_ "Confidence" SG_ 879 TPMS_sensorNoResponseRR 0;
BA_ "Confidence" SG_ 879 TPMS_sensorThermShutdownFL 0;
BA_ "Confidence" SG_ 879 TPMS_sensorThermShutdownFR 0;
BA_ "Confidence" SG_ 879 TPMS_sensorThermShutdownRL 0;
BA_ "Confidence" SG_ 879 TPMS_sensorThermShutdownRR 0;
BA_ "Confidence" SG_ 879 TPMS_sensorBatteryLowFL 0;
BA_ "Confidence" SG_ 879 TPMS_sensorBatteryLowFR 0;
BA_ "Confidence" SG_ 879 TPMS_sensorBatteryLowRL 0;
BA_ "Confidence" SG_ 879 TPMS_sensorBatteryLowRR 0;
BA_ "Confidence" SG_ 879 TPMS_sensorDefectiveFL 0;
BA_ "Confidence" SG_ 879 TPMS_sensorDefectiveFR 0;
BA_ "Confidence" SG_ 879 TPMS_sensorDefectiveRL 0;
BA_ "Confidence" SG_ 879 TPMS_sensorDefectiveRR 0;
BA_ "Confidence" SG_ 879 TPMS_ecuUnderVoltage 0;
BA_ "Confidence" SG_ 879 TPMS_ecuOverVoltage 0;
BA_ "Confidence" SG_ 879 TPMS_ecuRamRomNvMFail 0;
BA_ "Confidence" SG_ 879 TPMS_rfReceiverFail 0;
BA_ "Confidence" SG_ 879 TPMS_wheelPulseMissing 0;
BA_ "Confidence" SG_ 879 TPMS_vehicleSpeedFail 0;
BA_ "Confidence" SG_ 879 TPMS_externalTemperatureFail 0;
BA_ "Confidence" SG_ 879 TPMS_eolNotCompleted 0;
BA_ "Confidence" SG_ 879 TPMS_rcpFront 0;
BA_ "Confidence" SG_ 879 TPMS_rcpRear 0;
BA_ "Confidence" SG_ 799 TPMS_pressureFL 0;
BA_ "GenSigSNA" SG_ 799 TPMS_pressureFL "255";
BA_ "Confidence" SG_ 799 TPMS_temperatureFL 0;
BA_ "GenSigSNA" SG_ 799 TPMS_temperatureFL "255";
BA_ "Confidence" SG_ 799 TPMS_pressureFR 0;
BA_ "GenSigSNA" SG_ 799 TPMS_pressureFR "255";
BA_ "Confidence" SG_ 799 TPMS_temperatureFR 0;
BA_ "GenSigSNA" SG_ 799 TPMS_temperatureFR "255";
BA_ "Confidence" SG_ 799 TPMS_pressureRL 0;
BA_ "GenSigSNA" SG_ 799 TPMS_pressureRL "255";
BA_ "Confidence" SG_ 799 TPMS_temperatureRL 0;
BA_ "GenSigSNA" SG_ 799 TPMS_temperatureRL "255";
BA_ "Confidence" SG_ 799 TPMS_pressureRR 0;
BA_ "GenSigSNA" SG_ 799 TPMS_pressureRR "255";
BA_ "Confidence" SG_ 799 TPMS_temperatureRR 0;
BA_ "GenSigSNA" SG_ 799 TPMS_temperatureRR "255";
BA_ "Confidence" SG_ 1519 TPMS_infoIndex 1;
BA_ "Confidence" SG_ 1519 TPMS_infoComponentID 0;
BA_ "Confidence" SG_ 1519 TPMS_infoPcbaID 0;
BA_ "Confidence" SG_ 1519 TPMS_infoAssemblyID 0;
BA_ "Confidence" SG_ 1519 TPMS_infoUsageID 0;
BA_ "Confidence" SG_ 1519 TPMS_infoApplicationCRC 0;
BA_ "Confidence" SG_ 1519 TPMS_infoBootUdsProtoVersion 0;
BA_ "Confidence" SG_ 1519 TPMS_infoBootloaderCRC 0;
BA_ "Confidence" SG_ 1631 TPMS_udsResponseData 1;
BA_ "Confidence" SG_ 1609 UDS_dasRequestData 1;
BA_ "Confidence" SG_ 1584 UDS_epas3pRequestData 1;
BA_ "Confidence" SG_ 1840 UDS_epas3sRequestData 1;
BA_ "Confidence" SG_ 1605 UDS_espRequestData 1;
BA_ "Confidence" SG_ 2015 UDS_functionalRequestDataCH 1;
BA_ "Confidence" SG_ 1613 UDS_ibstRequestData 1;
BA_ "Confidence" SG_ 1614 UDS_parkRequestData 1;
BA_ "Confidence" SG_ 1649 UDS_radcRequestData 1;
BA_ "Confidence" SG_ 1601 UDS_rcmRequestData 1;
BA_ "Confidence" SG_ 1615 UDS_tpmsRequestData 1;
BA_ "Confidence" SG_ 1021 UI_autopilotControlIndex 1;
BA_ "Confidence" SG_ 1021 UI_hovEnabled 0;
BA_ "Confidence" SG_ 1021 UI_donDisableAutoWiperDuration 1;
BA_ "Confidence" SG_ 1021 UI_donDisableOnAutoWiperSpeed 1;
BA_ "Confidence" SG_ 1021 UI_blindspotMinSpeed 1;
BA_ "Confidence" SG_ 1021 UI_blindspotDistance 1;
BA_ "Confidence" SG_ 1021 UI_blindspotTTC 1;
BA_ "Confidence" SG_ 1021 UI_donStopEndOfRampBuffer 1;
BA_ "Confidence" SG_ 1021 UI_donDisableCutin 1;
BA_ "Confidence" SG_ 1021 UI_smartSetSpeedOffset 0;
BA_ "Confidence" SG_ 1021 UI_smartSetSpeedOffsetType 0;
BA_ "Confidence" SG_ 1021 UI_autopilotMonarchBackup 1;
BA_ "Confidence" SG_ 1021 UI_fsdVisualizationEnabled 1;
BA_ "Confidence" SG_ 1021 UI_fsdStopsControlEnabled 0;
BA_ "Confidence" SG_ 1021 UI_fsdContinueOnGreenWithCIPV 1;
BA_ "Confidence" SG_ 1021 UI_smartSetSpeed 0;
BA_ "Confidence" SG_ 1021 UI_automaticSetSpeedOffset 0;
BA_ "Confidence" SG_ 1021 UI_apply2021_1958_ISA 1;
BA_ "Confidence" SG_ 1021 UI_apply2021_646_ELKS 1;
BA_ "Confidence" SG_ 1021 UI_apply2021_1341_DDAW 1;
BA_ "Confidence" SG_ 1021 UI_homelinkNearby 1;
BA_ "Confidence" SG_ 1021 UI_enableFullSelfDriving 0;
BA_ "Confidence" SG_ 1021 UI_hasFullSelfDriving 0;
BA_ "Confidence" SG_ 1021 UI_autosteerActivation 0;
BA_ "Confidence" SG_ 1021 UI_fsdBetaRequest 0;
BA_ "Confidence" SG_ 1021 UI_fullSelfDrivingSuspended 0;
BA_ "Confidence" SG_ 1021 UI_disableOptionalLaneChanges 0;
BA_ "Confidence" SG_ 1021 UI_applyR152_AEBS 1;
BA_ "Confidence" SG_ 1021 UI_applyDCASBehavior 1;
BA_ "Confidence" SG_ 1021 UI_applyDCASBehaviorLegacy 1;
BA_ "Confidence" SG_ 1021 UI_applyADDWWarnings 0;
BA_ "Confidence" SG_ 1021 UI_autopilotControlMux0Valid 1;
BA_ "Confidence" SG_ 1021 UI_selectableCameraRequest 0;
BA_ "GenSigSNA" SG_ 1021 UI_selectableCameraRequest "15";
BA_ "Confidence" SG_ 1021 UI_overrideSleepWithSuspend 1;
BA_ "Confidence" SG_ 1021 UI_driverMonitorConfirmation 0;
BA_ "Confidence" SG_ 1021 UI_parkAssistUseVision 0;
BA_ "Confidence" SG_ 1021 UI_applyEceR79 1;
BA_ "Confidence" SG_ 1021 UI_enableMapStops 1;
BA_ "Confidence" SG_ 1021 UI_disableMain 1;
BA_ "Confidence" SG_ 1021 UI_disableNarrow 1;
BA_ "Confidence" SG_ 1021 UI_disableFisheye 1;
BA_ "Confidence" SG_ 1021 UI_disableLeftPillar 1;
BA_ "Confidence" SG_ 1021 UI_disableRightPillar 1;
BA_ "Confidence" SG_ 1021 UI_disableLeftRepeater 1;
BA_ "Confidence" SG_ 1021 UI_disableRightRepeater 1;
BA_ "Confidence" SG_ 1021 UI_disableBackup 1;
BA_ "Confidence" SG_ 1021 UI_disableRadar 1;
BA_ "Confidence" SG_ 1021 UI_noStalkConfirmAlertHaptic 0;
BA_ "Confidence" SG_ 1021 UI_regulatoryLKA 1;
BA_ "Confidence" SG_ 1021 UI_regulatoryLaneAssistLevel 1;
BA_ "Confidence" SG_ 1021 UI_ulcSnooze 1;
BA_ "Confidence" SG_ 1021 UI_noStalkConfirmAlertChime 0;
BA_ "Confidence" SG_ 1021 UI_factorySummonEnable 0;
BA_ "Confidence" SG_ 1021 UI_apmv3Branch 1;
BA_ "Confidence" SG_ 1021 UI_enableCabinCamera 0;
BA_ "Confidence" SG_ 1021 UI_enableAutopilotStopWarning 0;
BA_ "Confidence" SG_ 1021 UI_showLaneGraph 1;
BA_ "Confidence" SG_ 1021 UI_showTrackLabels 1;
BA_ "Confidence" SG_ 1021 UI_hardCoreSummon 1;
BA_ "Confidence" SG_ 1021 UI_enableCabinCameraTelemetry 1;
BA_ "Confidence" SG_ 1021 UI_enableVisionSpeedControl 0;
BA_ "Confidence" SG_ 1021 UI_autopilotTelemetryInChina 1;
BA_ "Confidence" SG_ 1021 UI_enableTeslaAutopark 0;
BA_ "Confidence" SG_ 1021 UI_autoTurnSignalMode 0;
BA_ "Confidence" SG_ 1021 UI_enableCautionLightControl 1;
BA_ "Confidence" SG_ 1021 UI_applyEceR79SmartSummonOnly 1;
BA_ "Confidence" SG_ 1021 UI_autopilotMonarchEnabled 1;
BA_ "Confidence" SG_ 1021 UI_autopilotEphemerisEnabled 1;
BA_ "Confidence" SG_ 1021 UI_enableCabinAudioRecording 0;
BA_ "Confidence" SG_ 1021 UI_autopilotControlMux1Valid 1;
BA_ "Confidence" SG_ 1021 UI_enableApproachingEmergencyVeh 1;
BA_ "SystemSignalLongSymbol" SG_ 1021 UI_enableApproachingEmergencyVeh "UI_enableApproachingEmergencyVehicleDetection";
BA_ "Confidence" SG_ 1021 UI_enableStartFsdFromParkBrakeCo 1;
BA_ "SystemSignalLongSymbol" SG_ 1021 UI_enableStartFsdFromParkBrakeCo "UI_enableStartFsdFromParkBrakeConfirmation";
BA_ "Confidence" SG_ 1021 UI_enableStartFsdFromPark 1;
BA_ "Confidence" SG_ 1021 UI_fsdMaxSpeedOffsetPercentage 1;
BA_ "Confidence" SG_ 1021 UI_calibrationReadyInFactory 1;
BA_ "Confidence" SG_ 1021 UI_coldStartMonarchInFactory 1;
BA_ "Confidence" SG_ 1021 UI_navMinutesToArrival 1;
BA_ "Confidence" SG_ 1021 UI_fsdQuizRequired 1;
BA_ "Confidence" SG_ 1021 UI_fsdQuizPassed 1;
BA_ "Confidence" SG_ 1021 UI_fsdAllowedInLocalizedRegion 1;
BA_ "Confidence" SG_ 1021 UI_autopilotDrivingProfile 0;
BA_ "Confidence" SG_ 1021 UI_autopilotControlMux2Valid 1;
BA_ "Confidence" SG_ 659 UI_steeringTuneRequest 0;
BA_ "Confidence" SG_ 659 UI_tractionControlMode 0;
BA_ "Confidence" SG_ 659 UI_parkBrakeRequest 0;
BA_ "GenSigSNA" SG_ 659 UI_parkBrakeRequest "3";
BA_ "Confidence" SG_ 659 UI_narrowGarages 1;
BA_ "Confidence" SG_ 659 UI_winchModeRequest 0;
BA_ "Confidence" SG_ 659 UI_zeroSpeedConfirmed 1;
BA_ "GenSigSNA" SG_ 659 UI_zeroSpeedConfirmed "3";
BA_ "Confidence" SG_ 659 UI_trailerMode 0;
BA_ "Confidence" SG_ 659 UI_distanceUnits 1;
BA_ "Confidence" SG_ 659 UI_dasDebugEnable 1;
BA_ "Confidence" SG_ 659 UI_accOvertakeEnable 0;
BA_ "GenSigSNA" SG_ 659 UI_accOvertakeEnable "3";
BA_ "Confidence" SG_ 659 UI_aebEnable 0;
BA_ "GenSigSNA" SG_ 659 UI_aebEnable "3";
BA_ "Confidence" SG_ 659 UI_aesEnable 0;
BA_ "GenSigSNA" SG_ 659 UI_aesEnable "3";
BA_ "Confidence" SG_ 659 UI_ahlbEnable 0;
BA_ "GenSigSNA" SG_ 659 UI_ahlbEnable "3";
BA_ "Confidence" SG_ 659 UI_autoLaneChangeEnable 0;
BA_ "GenSigSNA" SG_ 659 UI_autoLaneChangeEnable "3";
BA_ "Confidence" SG_ 659 UI_winchProxUserOverride 0;
BA_ "Confidence" SG_ 659 UI_rebootAutopilot 1;
BA_ "Confidence" SG_ 659 UI_autoParkRequest 0;
BA_ "GenSigSNA" SG_ 659 UI_autoParkRequest "15";
BA_ "Confidence" SG_ 659 UI_bsdEnable 0;
BA_ "GenSigSNA" SG_ 659 UI_bsdEnable "3";
BA_ "Confidence" SG_ 659 UI_fcwEnable 0;
BA_ "GenSigSNA" SG_ 659 UI_fcwEnable "3";
BA_ "Confidence" SG_ 659 UI_fcwSensitivity 0;
BA_ "GenSigSNA" SG_ 659 UI_fcwSensitivity "3";
BA_ "Confidence" SG_ 659 UI_latControlEnable 0;
BA_ "GenSigSNA" SG_ 659 UI_latControlEnable "3";
BA_ "Confidence" SG_ 659 UI_ldwEnable 0;
BA_ "GenSigSNA" SG_ 659 UI_ldwEnable "3";
BA_ "Confidence" SG_ 659 UI_pedalSafetyEnable 1;
BA_ "GenSigSNA" SG_ 659 UI_pedalSafetyEnable "3";
BA_ "Confidence" SG_ 659 UI_pedalMap_epas 1;
BA_ "Confidence" SG_ 659 UI_redLightStopSignEnable 1;
BA_ "GenSigSNA" SG_ 659 UI_redLightStopSignEnable "3";
BA_ "Confidence" SG_ 659 UI_selfParkTune 1;
BA_ "GenSigSNA" SG_ 659 UI_selfParkTune "15";
BA_ "Confidence" SG_ 659 UI_chassisControlCounter 1;
BA_ "Confidence" SG_ 659 UI_chassisControlChecksum 0;
BA_ "Confidence" SG_ 664 UI_csaOfframpCurvC2 1;
BA_ "Confidence" SG_ 664 UI_csaOfframpCurvC3 1;
BA_ "Confidence" SG_ 664 UI_csaOfframpCurvRange 1;
VAL_ 1009 RCM2_matrixIndex 10 "AlertMatrix10" 9 "AlertMatrix9" 8 "AlertMatrix8" 7 "AlertMatrix7" 6 "AlertMatrix6" 5 "AlertMatrix5" 4 "AlertMatrix4" 3 "AlertMatrix3" 2 "AlertMatrix2" 1 "AlertMatrix1" 0 "AlertMatrix0" ;
VAL_ 1252 RCM3_alertID 1 "RCM3_a001_LVPowerLossDetected" ;
VAL_ 1252 RCM3_alertState 1 "SET" 0 "CLEARED" ;
VAL_ 1010 RCM3_matrixIndex 0 "RCM3_AlertMatrix0" ;
VAL_ 257 RCM_yawRate -32768 "SNA" ;
VAL_ 257 RCM_pitchRate -16384 "SNA" ;
VAL_ 257 RCM_rollRate -16384 "SNA" ;
VAL_ 257 RCM_rollRateQF 3 "FAULTED" 2 "TEMP_INVALID" 1 "VALID" 0 "INIT" ;
VAL_ 257 RCM_yawRateQF 1 "NOT_FAULTED" 0 "FAULTED" ;
VAL_ 257 RCM_pitchRateQF 3 "FAULTED" 2 "TEMP_INVALID" 1 "VALID" 0 "INIT" ;
VAL_ 273 RCM_longitudinalAccel -32768 "SNA" ;
VAL_ 273 RCM_lateralAccel -32768 "SNA" ;
VAL_ 273 RCM_verticalAccel -32768 "SNA" ;
VAL_ 273 RCM_longitudinalAccelQF 1 "NOT_FAULTED" 0 "FAULTED" ;
VAL_ 273 RCM_lateralAccelQF 1 "NOT_FAULTED" 0 "FAULTED" ;
VAL_ 273 RCM_verticalAccelQF 1 "NOT_FAULTED" 0 "FAULTED" ;
VAL_ 273 RCM_CGTranslationFault 1 "RCM_COG_TRANSLATION_FAULTED" 0 "RCM_COG_TRANSLATION_NOT_FAULTED" ;
VAL_ 849 RCM_infoIndex 255 "END" 31 "SUBCOMPONENT_GITHASH" 30 "PACKAGE_SN_8_14" 29 "PACKAGE_SN_1_7" 27 "PACKAGE_PN_15_20" 26 "PACKAGE_PN_8_14" 25 "PACKAGE_PN_1_7" 23 "SUBCOMPONENT2" 22 "VARIANTCRC" 20 "UDS_PROTOCOL_BOOTCRC" 19 "VERSION_DEPRECATED" 18 "BOOTLOADER_GITHASH" 17 "APP_GITHASH" 16 "SUBCOMPONENT" 15 "BOOTLOADER_CRC" 14 "BOOTLOADER_SVN" 13 "APP_CRC" 11 "PCBAID_ASSYID_USAGEID" 10 "BUILD_HWID_COMPONENTID" 9 "DEPRECATED_9" 8 "DEPRECATED_8" 7 "DEPRECATED_7" 6 "DEPRECATED_6" 5 "DEPRECATED_5" 4 "DEPRECATED_4" 3 "DEPRECATED_3" 2 "DEPRECATED_2" 1 "DEPRECATED_1" 0 "DEPRECATED_0" ;
VAL_ 849 RCM_infoBuildType 4 "INFO_MFG_BUILD" 3 "INFO_TRACEABLE_CI_BUILD" 2 "INFO_LOCAL_BUILD" 1 "INFO_PLATFORM_BUILD" 0 "INFO_UNKNOWN_BUILD" ;
VAL_ 529 RCM_armStatus 3 "SNA" 2 "ARMED_WITH_NOFIRE_CAL" 1 "RCM_ARMED" 0 "RCM_UNARMED" ;
VAL_ 529 RCM_warningIndicatorState 3 "SNA" 1 "RCM_WARNING_INDICATOR_ON" 0 "RCM_WARNING_INDICATOR_OFF" ;
VAL_ 529 RCM_passAirbagIndicatorRequest 3 "SNA" 1 "RCM_PASSENGER_AIRBAG_INDICATOR_OFF" 0 "RCM_PASSENGER_AIRBAG_INDICATOR_ON" ;
VAL_ 529 RCM_airbagCutoffStatus 3 "SNA" 1 "RCM_PASSENGER_AIRBAG_DISABLED" 0 "RCM_PASSENGER_AIRBAG_ENABLED" ;
VAL_ 529 RCM_alrSwitchStatus 3 "SNA" 2 "RCM_ALR_FAULTED" 1 "RCM_ALR_ENGAGED" 0 "RCM_ALR_NOT_ENGAGED" ;
VAL_ 529 RCM_vinLearnFlag 3 "SNA" 2 "RCM_VIN_STORED_MISMATCH" 1 "RCM_VIN_STORED" 0 "RCM_VIN_NOT_STORED" ;
VAL_ 529 RCM_seatTrackPositionDrvr 3 "SNA" 2 "RCM_SEAT_POSITION_FAULTED" 1 "RCM_SEAT_POSITION_FAR" 0 "RCM_SEAT_POSITION_NEAR" ;
VAL_ 529 RCM_seatTrackPositionPass 3 "SNA" 2 "RCM_SEAT_POSITION_FAULTED" 1 "RCM_SEAT_POSITION_FAR" 0 "RCM_SEAT_POSITION_NEAR" ;
VAL_ 529 RCM_edr1State 3 "RCM_EDR_UNAVAILABLE" 2 "RCM_EDR_LOCKED" 1 "RCM_EDR_STORED" 0 "RCM_EDR_EMPTY" ;
VAL_ 529 RCM_edr2State 3 "RCM_EDR_UNAVAILABLE" 2 "RCM_EDR_LOCKED" 1 "RCM_EDR_STORED" 0 "RCM_EDR_EMPTY" ;
VAL_ 529 RCM_keepPowerReason 8 "RCM_KEEP_POWER_REASON_SNA" 7 "RCM_INVALID_POWER_OFF_REQUEST" 6 "RCM_INITIALIZATION_PHASE" 5 "RCM_CANNOT_POWER_DOWN" 4 "RCM_EDR_UPLOADING" 3 "RCM_EDR_STORING_TO_EEPROM" 2 "RCM_CRASH_ALGO_ACTIVE" 1 "RCM_IN_IDLE_MODE" 0 "RCM_NO_KEEP_POWER_REQUEST" ;
VAL_ 529 RCM_imuOffsetLearnState 3 "IMU_OFFSETS_UNABLE_TO_LEARN" 2 "IMU_FAST_LEARNING_TIME" 1 "IMU_SLOW_LEARNING_DISTANCE" 0 "IMU_OFFSET_LEARNING_OFF" ;
VAL_ 529 RCM_edr3State 3 "RCM_EDR_UNAVAILABLE" 2 "RCM_EDR_LOCKED" 1 "RCM_EDR_STORED" 0 "RCM_EDR_EMPTY" ;
VAL_ 529 RCM_driverOrientationInitStatus 7 "SNA" 4 "RCM_DRIVER_ORIENTATION_MISMATCH_DEFAULT_RHD" 3 "RCM_DRIVER_ORIENTATION_MISMATCH_DEFAULT_LHD" 2 "RCM_DRIVER_ORIENTATION_MATCHED_RHD" 1 "RCM_DRIVER_ORIENTATION_MATCHED_LHD" 0 "RCM_DRIVER_ORIENTATION_INIT_NOT_COMPLETE" ;
VAL_ 529 RCM_occupantClassificationSource 1 "VCRIGHT_CLASSIFICATION_SOURCE" 0 "OCS1P_CLASSIFICATION_SOURCE" ;
VAL_ 529 RCM_pedProEDR1State 3 "RCM_EDR_UNAVAILABLE" 2 "RCM_EDR_LOCKED" 1 "RCM_EDR_STORED" 0 "RCM_EDR_EMPTY" ;
VAL_ 529 RCM_pedProEDR2State 3 "RCM_EDR_UNAVAILABLE" 2 "RCM_EDR_LOCKED" 1 "RCM_EDR_STORED" 0 "RCM_EDR_EMPTY" ;
VAL_ 1471 RCU_alertID 66 "a066_ESPredundantBrakingStatusChecksum" 65 "a065_ESPredundantBrakingStatusCounter" 64 "a064_ESPredundantBrakingStatusDLC" 63 "a063_DIlocStatus2Checksum" 62 "a062_DIlocStatus2Counter" 61 "a061_DIlocStatus2DLC" 60 "a060_DASbrakeTorqueCommandInvalid" 59 "a059_DASredundantBrakingControlChecksum" 58 "a058_DASredundantBrakingControlCounter" 57 "a057_DASredundantBrakingControlDLC" 56 "a056_redundantControllerIsMaster" 55 "a055_IDBsimulatorPressFaulted" 54 "a054_IDBcircuitPressFaulted" 53 "a053_ESPwheelSpeedsChecksum" 52 "a052_ESPwheelSpeedsCounter" 51 "a051_ESPReRWSSLInvalid" 50 "a050_ESPReLWSSLInvalid" 49 "a049_ESPFrRWSSLInvalid" 48 "a048_ESPFrLWSSLInvalid" 47 "a047_ESPwheelSpeedsDLC" 46 "a046_brakeFluidLevelSNA" 45 "a045_VCFRONTtempInvalid" 44 "a044_VCFRONTsensorsMIA" 43 "a043_VCFRONTiBoosterLvStateInvalid" 42 "a042_DIsystemStatusChecksum" 41 "a041_DIsystemStatusCounter" 40 "a040_DIgearInvalid" 39 "a039_DIaccelPosInvalid" 38 "a038_DIsystemStatusDLC" 37 "a037_IDBinputRodStrokeInvalid" 36 "a036_IDBpspInvalid" 35 "a035_IDBpcpInvalid" 34 "a034_VCFRONTLVPowerStateCounter" 33 "a033_VCFRONTLVPowerStateChecksum" 32 "a032_VCFRONTLVPowerStateDLC" 31 "a031_PMstate2Counter" 30 "a030_PMstate2Checksum" 29 "a029_PMstate2DLC" 28 "a028_DIchassisControlCounter" 27 "a027_DIchassisCtrlChecksum" 26 "a026_DIchassisControlDLC" 25 "a025_IDBstatusCounter" 24 "a024_IDBstatusChecksum" 23 "a023_IDBstatusDLC" 22 "a022_BBstatusCounter" 21 "a021_BBstatusChecksum" 20 "a020_BBstatusDLC" 19 "a019_DItorquePathActive" 18 "a018_DItorquePathFaulted" 17 "a017_chassisBusOff" 16 "a016_partyBusOff" 15 "a015_fluidLeakDetected" 14 "a014_asicTempHigh" 13 "a013_mcuGenericFault" 12 "a012_pedalSensorNotCal" 11 "a011_idbPedalTravelMismatch" 10 "a010_pedalSensorFault" 9 "a009_brakeFluidLow" 8 "a008_pressureNotCalibrated" 7 "a007_pressureSensorFault" 6 "a006_wakeLineOpen" 5 "a005_supplyUndervoltage" 4 "a004_supplyOvervoltage" 3 "a003_pumpMotorFault" 2 "a002_solenoidValveFault" 1 "a001_valveDriverFault" 0 "ALERT_DO_NOT_USE_ZERO" ;
VAL_ 1471 RCU_alertState 1 "SET" 0 "CLEARED" ;
VAL_ 1471 RCU_a010_sensorPowerSupply 1 "NOT_OK" 0 "OK" ;
VAL_ 1471 RCU_a010_sensorHardware 1 "NOT_OK" 0 "OK" ;
VAL_ 1471 RCU_a010_sensorSignal 1 "NOT_OK" 0 "OK" ;
VAL_ 1471 RCU_a023_validityOnChassisBus 1 "NOT_OK" 0 "OK" ;
VAL_ 1471 RCU_a023_validityOnPartyBus 1 "NOT_OK" 0 "OK" ;
VAL_ 1471 RCU_a024_validityOnChassisBus 1 "NOT_OK" 0 "OK" ;
VAL_ 1471 RCU_a024_validityOnPartyBus 1 "NOT_OK" 0 "OK" ;
VAL_ 1471 RCU_a025_validityOnChassisBus 1 "NOT_OK" 0 "OK" ;
VAL_ 1471 RCU_a025_validityOnPartyBus 1 "NOT_OK" 0 "OK" ;
VAL_ 1471 RCU_a035_validityOnChassisBus 1 "NOT_OK" 0 "OK" ;
VAL_ 1471 RCU_a035_validityOnPartyBus 1 "NOT_OK" 0 "OK" ;
VAL_ 1471 RCU_a036_validityOnChassisBus 1 "NOT_OK" 0 "OK" ;
VAL_ 1471 RCU_a036_validityOnPartyBus 1 "NOT_OK" 0 "OK" ;
VAL_ 998 RCU_matrixIndex 1 "AlertMatrix1" 0 "AlertMatrix0" ;
VAL_ 831 RCU_infoIndex 255 "END" 31 "SUBCOMPONENT_GITHASH" 30 "PACKAGE_SN_8_14" 29 "PACKAGE_SN_1_7" 27 "PACKAGE_PN_15_20" 26 "PACKAGE_PN_8_14" 25 "PACKAGE_PN_1_7" 23 "SUBCOMPONENT2" 22 "VARIANTCRC" 20 "UDS_PROTOCOL_BOOTCRC" 19 "VERSION_DEPRECATED" 18 "BOOTLOADER_GITHASH" 17 "APP_GITHASH" 16 "SUBCOMPONENT" 15 "BOOTLOADER_CRC" 14 "BOOTLOADER_SVN" 13 "APP_CRC" 11 "PCBAID_ASSYID_USAGEID" 10 "BUILD_HWID_COMPONENTID" 9 "DEPRECATED_9" 8 "DEPRECATED_8" 7 "DEPRECATED_7" 6 "DEPRECATED_6" 5 "DEPRECATED_5" 4 "DEPRECATED_4" 3 "DEPRECATED_3" 2 "DEPRECATED_2" 1 "DEPRECATED_1" 0 "DEPRECATED_0" ;
VAL_ 879 TPMS_learningStatus 3 "PASSED" 2 "STOPPED" 1 "ONGOING" 0 "FAILED" ;
VAL_ 879 TPMS_localisationStatus 3 "PASSED" 2 "STOPPED" 1 "ONGOING" 0 "FAILED" ;
VAL_ 799 TPMS_pressureFL 255 "SNA" 254 "OVER_RANGE" ;
VAL_ 799 TPMS_temperatureFL 255 "TPMS_TEMPERATURE_SNA" ;
VAL_ 799 TPMS_pressureFR 255 "SNA" 254 "OVER_RANGE" ;
VAL_ 799 TPMS_temperatureFR 255 "TPMS_TEMPERATURE_SNA" ;
VAL_ 799 TPMS_pressureRL 255 "SNA" 254 "OVER_RANGE" ;
VAL_ 799 TPMS_temperatureRL 255 "TPMS_TEMPERATURE_SNA" ;
VAL_ 799 TPMS_pressureRR 255 "SNA" 254 "OVER_RANGE" ;
VAL_ 799 TPMS_temperatureRR 255 "TPMS_TEMPERATURE_SNA" ;
VAL_ 1519 TPMS_infoIndex 255 "END" 31 "SUBCOMPONENT_GITHASH" 30 "PACKAGE_SN_8_14" 29 "PACKAGE_SN_1_7" 27 "PACKAGE_PN_15_20" 26 "PACKAGE_PN_8_14" 25 "PACKAGE_PN_1_7" 23 "SUBCOMPONENT2" 22 "VARIANTCRC" 20 "UDS_PROTOCOL_BOOTCRC" 19 "VERSION_DEPRECATED" 18 "BOOTLOADER_GITHASH" 17 "APP_GITHASH" 16 "SUBCOMPONENT" 15 "BOOTLOADER_CRC" 14 "BOOTLOADER_SVN" 13 "APP_CRC" 11 "PCBAID_ASSYID_USAGEID" 10 "BUILD_HWID_COMPONENTID" 9 "DEPRECATED_9" 8 "DEPRECATED_8" 7 "DEPRECATED_7" 6 "DEPRECATED_6" 5 "DEPRECATED_5" 4 "DEPRECATED_4" 3 "DEPRECATED_3" 2 "DEPRECATED_2" 1 "DEPRECATED_1" 0 "DEPRECATED_0" ;
VAL_ 1021 UI_autopilotControlIndex 7 "7" 6 "6" 5 "5" 4 "4" 3 "3" 2 "2" 1 "1" 0 "0" ;
VAL_ 1021 UI_hovEnabled 1 "HOV_ON" 0 "HOV_OFF" ;
VAL_ 1021 UI_donDisableAutoWiperDuration 6 "OFF" 5 "120_S" 4 "60_S" 3 "30_S" 2 "15_S" 1 "5_S" 0 "DEFAULT" ;
VAL_ 1021 UI_donDisableOnAutoWiperSpeed 15 "INVALID" 14 "14" 13 "13" 12 "12" 11 "11" 10 "10" 9 "9" 8 "8" 7 "7" 6 "6" 5 "5" 4 "4" 3 "3" 2 "2" 1 "1" 0 "OFF" ;
VAL_ 1021 UI_blindspotMinSpeed 10 "OFF" 9 "45_KPH" 8 "40_KPH" 7 "35_KPH" 6 "30_KPH" 5 "25_KPH" 4 "20_KPH" 3 "15_KPH" 2 "10_KPH" 1 "5_KPH" 0 "DEFAULT" ;
VAL_ 1021 UI_blindspotDistance 5 "OFF" 4 "4_M" 3 "2_M" 2 "1_M" 1 "0P5_M" 0 "DEFAULT" ;
VAL_ 1021 UI_blindspotTTC 7 "OFF" 6 "5_S" 5 "3_S" 4 "4_S" 3 "2_S" 2 "1_S" 1 "0P5_S" 0 "DEFAULT" ;
VAL_ 1021 UI_donStopEndOfRampBuffer 4 "OFF" 3 "45_M" 2 "30_M" 1 "15_M" 0 "DEFAULT" ;
VAL_ 1021 UI_donDisableCutin 1 "ON" 0 "OFF" ;
VAL_ 1021 UI_smartSetSpeedOffsetType 1 "PERCENTAGE_OFFSET" 0 "FIXED_OFFSET" ;
VAL_ 1021 UI_homelinkNearby 1 "NEARBY" 0 "NOT_NEARBY" ;
VAL_ 1021 UI_autosteerActivation 1 "DOUBLE_CLICK" 0 "SINGLE_CLICK" ;
VAL_ 1021 UI_fsdBetaRequest 1 "FSD_REQUEST_ACTIVE" 0 "FSD_REQUEST_NOT_ACTIVE" ;
VAL_ 1021 UI_selectableCameraRequest 15 "SNA" 13 "REPEATERS_BACKUP" 12 "FASCIA" 11 "GRID_VIEW" 10 "OCTA" 9 "BACKUP" 8 "RIGHT_REPEATER" 7 "RIGHT_PILLAR" 6 "LEFT_REPEATER" 5 "LEFT_PILLAR" 4 "FRONT_NARROW" 3 "FRONT_FISHEYE" 2 "FRONT_MAIN" 1 "SELFIE" 0 "NONE" ;
VAL_ 1021 UI_overrideSleepWithSuspend 1 "ENABLED" 0 "DISABLED" ;
VAL_ 1021 UI_regulatoryLaneAssistLevel 1 "ASSIST" 0 "WARNING" ;
VAL_ 1021 UI_apmv3Branch 5 "DEMO" 4 "EAP" 3 "STAGE2" 2 "DEV" 1 "STAGE" 0 "LIVE" ;
VAL_ 1021 UI_autoTurnSignalMode 1 "UI_AUTO_TURN_SIGNAL_MODE_AUTO_CANCEL" 0 "UI_AUTO_TURN_SIGNAL_MODE_OFF" ;
VAL_ 1021 UI_autopilotDrivingProfile 4 "CONSERVATIVE" 3 "MAD_MAX" 2 "ASSERTIVE" 1 "NORMAL" 0 "CHILL" ;
VAL_ 659 UI_steeringTuneRequest 2 "STEERING_TUNE_SPORT" 1 "STEERING_TUNE_STANDARD" 0 "STEERING_TUNE_COMFORT" ;
VAL_ 659 UI_tractionControlMode 7 "TC_SLIPPERY_SURFACE_SELECTED" 6 "TC_OFFROAD_ASSIST_SELECTED" 5 "TC_DYNO_MODE_SELECTED" 4 "TC_ROLLS_MODE_SELECTED" 3 "TC_DEV_MODE_2_SELECTED" 2 "TC_DEV_MODE_1_SELECTED" 1 "TC_SLIP_START_SELECTED" 0 "TC_NORMAL_SELECTED" ;
VAL_ 659 UI_parkBrakeRequest 3 "PARK_BRAKE_REQUEST_SNA" 1 "PARK_BRAKE_REQUEST_PRESSED" 0 "PARK_BRAKE_REQUEST_IDLE" ;
VAL_ 659 UI_winchModeRequest 3 "WINCH_MODE_DIALOGUE_OPEN" 2 "WINCH_MODE_EXIT" 1 "WINCH_MODE_ENTER" 0 "WINCH_MODE_IDLE" ;
VAL_ 659 UI_zeroSpeedConfirmed 3 "SNA" 2 "UNUSED" 1 "CONFIRMED" 0 "CANCELED" ;
VAL_ 659 UI_trailerMode 1 "TRAILER_MODE_ON" 0 "TRAILER_MODE_OFF" ;
VAL_ 659 UI_distanceUnits 1 "MILES" 0 "KM" ;
VAL_ 659 UI_accOvertakeEnable 3 "SNA" 1 "ACC_OVERTAKE_ON" 0 "ACC_OVERTAKE_OFF" ;
VAL_ 659 UI_aebEnable 3 "SNA" 1 "AEB_ON" 0 "AEB_OFF" ;
VAL_ 659 UI_aesEnable 3 "SNA" 1 "AES_ON" 0 "AES_OFF" ;
VAL_ 659 UI_ahlbEnable 3 "SNA" 1 "AHLB_ON" 0 "AHLB_OFF" ;
VAL_ 659 UI_autoLaneChangeEnable 3 "SNA" 1 "ON" 0 "OFF" ;
VAL_ 659 UI_autoParkRequest 15 "SNA" 12 "BEGIN_PARKING" 11 "RESUME" 10 "PAUSE" 9 "SEARCH" 8 "COMPLETE" 7 "ABORT" 6 "PARALLEL_PULL_OUT_TO_RIGHT" 5 "PARALLEL_PULL_OUT_TO_LEFT" 4 "PARK_RIGHT_CROSS" 3 "PARK_RIGHT_PARALLEL" 2 "PARK_LEFT_CROSS" 1 "PARK_LEFT_PARALLEL" 0 "NONE" ;
VAL_ 659 UI_bsdEnable 3 "SNA" 1 "BSD_ON" 0 "BSD_OFF" ;
VAL_ 659 UI_fcwEnable 3 "SNA" 1 "FCW_ON" 0 "FCW_OFF" ;
VAL_ 659 UI_fcwSensitivity 3 "SNA" 2 "AEB_SENSITIVITY_LATE" 1 "AEB_SENSITIVITY_AVERAGE" 0 "AEB_SENSITIVITY_EARLY" ;
VAL_ 659 UI_latControlEnable 3 "LATERAL_CONTROL_SNA" 2 "LATERAL_CONTROL_UNAVAILABLE" 1 "LATERAL_CONTROL_ON" 0 "LATERAL_CONTROL_OFF" ;
VAL_ 659 UI_ldwEnable 3 "SNA" 1 "LDW_TRIGGERS_HAPTIC" 0 "NO_HAPTIC" ;
VAL_ 659 UI_pedalSafetyEnable 3 "SNA" 1 "PEDAL_SAFETY_ON" 0 "PEDAL_SAFETY_OFF" ;
VAL_ 659 UI_pedalMap_epas 2 "PERFORMANCE" 1 "SPORT" 0 "CHILL" ;
VAL_ 659 UI_redLightStopSignEnable 3 "SNA" 1 "RLSSW_ON" 0 "RLSSW_OFF" ;
VAL_ 659 UI_selfParkTune 15 "SNA" ;
